VERSION ""

NS_ :

BS_:

BU_: AHLM ASBS CBC DIAGNOST DPDM DTCM ECM EHPS ESC ESL ESM ETM GPF HCP IC IRCM OCM ORC PTS RF_HUB SCCM SGW TBM TCM TPM

BO_ 131 ESP_A1: 8 ESC
 SG_ ABS_BrkEvt : 14|1@1+ (1,0) [0|0] ""  DTCM,ECM,ETM,HCP,ORC,SGW,TBM,TCM
 SG_ BrkIntrvntn_Actv_AS : 6|1@1+ (1,0) [0|0] ""  ETM,IRCM,SGW,TBM,TCM
 SG_ BrkIntrvntn_Actv_ESP : 5|1@1+ (1,0) [0|0] ""  DTCM,ECM,ETM,HCP,ORC,SGW,TBM,TCM
 SG_ BrkIntrvntn_Enbl : 7|1@1+ (1,0) [0|0] ""  ECM,ORC,SGW,TCM
 SG_ BrkPdl_Flt : 4|1@1+ (1,0) [0|0] ""  ECM,ETM,HCP,IRCM,ORC,SGW,TBM
 SG_ BrkPdl_Stat : 2|2@1+ (1,0) [0|0] ""  CBC,DTCM,ECM,ETM,HCP,IRCM,ORC,RF_HUB,SGW,TBM,TCM
 SG_ Brk_Stat : 0|2@1+ (1,0) [0|0] ""  CBC,ECM,ETM,ORC,PTS,SGW,TBM
 SG_ Brk_Thermdl : 25|1@1+ (1,0) [0|0] ""  IRCM,SGW
 SG_ CRC_Brk_Stat : 56|8@1+ (1,0) [0|0] ""  ECM,HCP,IC,IRCM,PTS,RF_HUB,SGW,TCM
 SG_ DTR_CC_Enabled : 23|1@1+ (1,0) [0|0] ""  ECM,HCP,SGW
 SG_ DTR_CC_Engaged : 15|1@1+ (1,0) [0|0] ""  CBC,ECM,HCP,SGW,TCM
 SG_ ESP_Sys_Stat : 10|2@1+ (1,0) [0|0] ""  ECM,ETM,HCP,SGW,TBM,TCM
 SG_ EmgBrk_Actv : 8|1@1+ (1,0) [0|0] ""  ORC,SGW
 SG_ FullBrk_Actv : 9|1@1+ (1,0) [0|0] ""  ORC,SGW
 SG_ GrMax_Rq_ESC : 19|3@1+ (1,0) [0|0] ""  SGW,TCM
 SG_ GrMinMax_Rq_DTR : 22|1@1+ (1,0) [0|0] ""  SGW,TCM
 SG_ GrMin_Rq_ESC : 16|3@1+ (1,0) [0|0] ""  SGW,TCM
 SG_ HillHolderActive : 24|1@1+ (1,0) [0|0] ""  SGW,TCM
 SG_ MC_Brk_Stat : 52|4@1+ (1,0) [0|15] ""  ECM,HCP,IC,IRCM,PTS,RF_HUB,SGW,TCM
 SG_ REF_VEH_SPEED : 33|10@0+ (0.5,0) [0|511] "km/h"  ECM,HCP,ORC,SGW,TCM
 SG_ RollTestMd_Actv : 30|2@1+ (1,0) [0|0] ""  DTCM,ECM,IRCM,SGW
 SG_ SPCR_AS_Off_Rq : 38|2@1+ (1,0) [0|0] ""  ECM,IRCM,SGW
 SG_ SelSpdSts : 12|2@1+ (1,0) [0|0] ""  CBC,DTCM,ECM,IC,SGW,TCM
 SG_ ShftChrDsp_Rq_ESC : 26|4@1+ (1,0) [0|0] ""  ECM,SGW,TCM

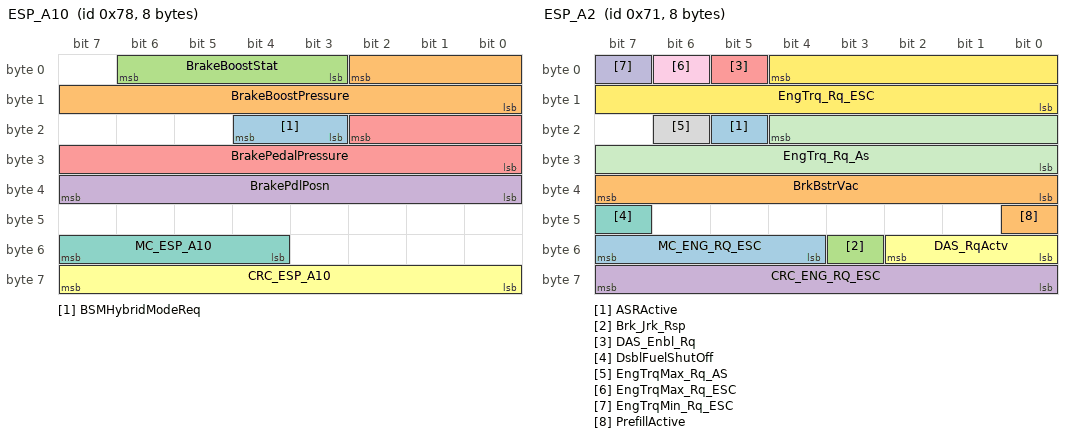
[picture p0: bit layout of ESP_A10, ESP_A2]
BO_ 120 ESP_A10: 8 ESC
 SG_ BSMHybridModeReq : 19|2@1+ (1,0) [0|0] ""  SGW
 SG_ BrakeBoostPressure : 2|11@0+ (0.1,0) [0|200] "bar"  ECM,SGW,TCM
 SG_ BrakeBoostStat : 3|4@1+ (1,0) [0|0] ""  SGW
 SG_ BrakePdlPosn : 32|8@1+ (0.4,0) [0|100] "%"  ECM,ETM,ORC,SGW,TBM,TCM
 SG_ BrakePedalPressure : 18|11@0+ (0.1,0) [0|200] "bar"  ECM,SGW,TCM
 SG_ CRC_ESP_A10 : 56|8@1+ (1,0) [0|0] ""  ECM,SGW,TCM
 SG_ MC_ESP_A10 : 52|4@1+ (1,0) [0|15] ""  ECM,SGW,TCM

BO_ 113 ESP_A2: 8 ESC
 SG_ ASRActive : 21|1@1+ (1,0) [0|0] ""  ETM,ORC,SGW,TBM,TCM
 SG_ BrkBstrVac : 32|8@1+ (0.55,-119.7) [-119.7|20] "kPa"  ECM,ORC,SGW
 SG_ Brk_Jrk_Rsp : 51|1@1+ (1,0) [0|0] ""  IRCM,ORC,SGW
 SG_ CRC_ENG_RQ_ESC : 56|8@1+ (1,0) [0|0] ""  ECM,IRCM,SGW,TCM
 SG_ DAS_Enbl_Rq : 5|1@1+ (1,0) [0|0] ""  ECM,IRCM,SGW
 SG_ DAS_RqActv : 48|3@1+ (1,0) [0|0] ""  IRCM,ORC,SGW
 SG_ DsblFuelShutOff : 47|1@1+ (1,0) [0|0] ""  ECM,SGW
 SG_ EngTrqMax_Rq_AS : 22|1@1+ (1,0) [0|0] ""  ECM,SGW
 SG_ EngTrqMax_Rq_ESC : 6|1@1+ (1,0) [0|0] ""  ECM,SGW,TCM
 SG_ EngTrqMin_Rq_ESC : 7|1@1+ (1,0) [0|0] ""  ECM,SGW,TCM
 SG_ EngTrq_Rq_As : 20|13@0+ (0.25,-500) [-500|1547.5] "Nm"  ECM,IRCM,ORC,SGW
 SG_ EngTrq_Rq_ESC : 4|13@0+ (0.25,-500) [-500|1547.5] "Nm"  DTCM,ECM,ETM,SGW,TBM
 SG_ MC_ENG_RQ_ESC : 52|4@1+ (1,0) [0|15] ""  ECM,IRCM,SGW,TCM
 SG_ PrefillActive : 40|1@1+ (1,0) [0|0] ""  IRCM,SGW

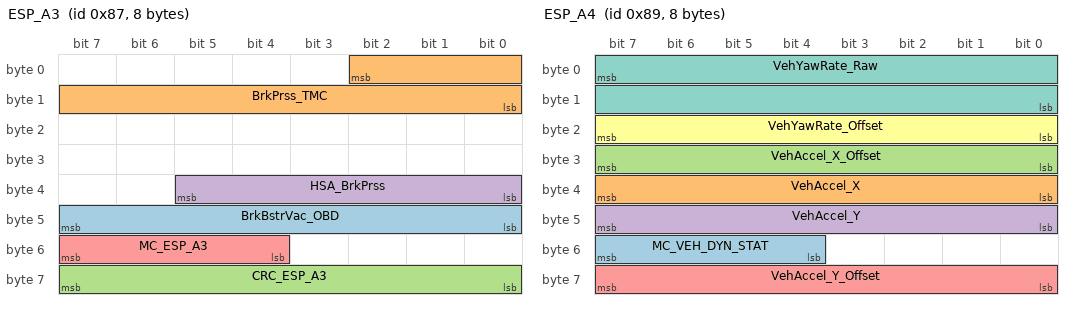
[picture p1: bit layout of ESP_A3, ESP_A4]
BO_ 135 ESP_A3: 8 ESC
 SG_ BrkBstrVac_OBD : 40|8@1+ (0.019607843,0) [0|5] "Volts"  ECM,SGW
 SG_ BrkPrss_TMC : 2|11@0+ (0.1,0) [0|200] "bar"  ECM,ETM,ORC,SGW,TBM,TCM
 SG_ CRC_ESP_A3 : 56|8@1+ (1,0) [0|0] ""  ECM,PTS,SGW,TCM
 SG_ HSA_BrkPrss : 32|6@1+ (1,0) [0|50] "bar"  ECM,ETM,ORC,SGW,TBM
 SG_ MC_ESP_A3 : 52|4@1+ (1,0) [0|15] ""  ECM,PTS,SGW,TCM

BO_ 137 ESP_A4: 8 ESC
 SG_ MC_VEH_DYN_STAT : 52|4@1+ (1,0) [0|15] ""  ECM,ETM,IRCM,PTS,SGW
 SG_ VehAccel_X : 32|8@1+ (0.08,-10.24) [-10.24|10.08] "m/s²"  CBC,DTCM,ECM,ETM,IRCM,SGW,TBM,TCM
 SG_ VehAccel_X_Offset : 24|8@1+ (0.02,-2.56) [-2.56|2.52] "m/s²"  DTCM,ECM,ETM,IRCM,SGW,TBM,TCM
 SG_ VehAccel_Y : 40|8@1+ (0.08,-10.24) [-10.24|10.08] "m/s²"  CBC,DTCM,ECM,ETM,IRCM,SGW,TBM,TCM
 SG_ VehAccel_Y_Offset : 56|8@1+ (0.02,-2.56) [-2.56|2.52] "m/s²"  DTCM,ECM,ETM,IRCM,SGW,TBM,TCM
 SG_ VehYawRate_Offset : 16|8@1+ (0.08,-10.24) [-6.96|6.96] ""  DTCM,ECM,IRCM,ORC,SGW
 SG_ VehYawRate_Raw : 7|16@0+ (0.01,-327.68) [-327.68|327.66] "°/s"  CBC,DTCM,ECM,ETM,IRCM,SGW,TBM

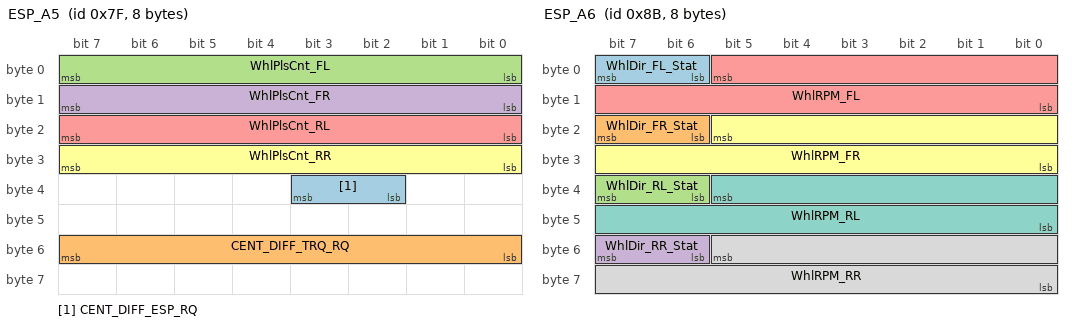
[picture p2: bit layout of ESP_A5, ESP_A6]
BO_ 127 ESP_A5: 8 ESC
 SG_ CENT_DIFF_ESP_RQ : 34|2@1+ (1,0) [0|0] ""  DTCM,SGW
 SG_ CENT_DIFF_TRQ_RQ : 48|8@1+ (10,0) [0|2540] "Nm"  DTCM,SGW
 SG_ WhlPlsCnt_FL : 0|8@1+ (1,0) [0|254] "Impulse"  CBC,IRCM,PTS,SGW,TBM
 SG_ WhlPlsCnt_FR : 8|8@1+ (1,0) [0|254] "Impulse"  CBC,IRCM,PTS,SGW,TBM
 SG_ WhlPlsCnt_RL : 16|8@1+ (1,0) [0|254] "Impulse"  CBC,IRCM,PTS,SGW,TBM
 SG_ WhlPlsCnt_RR : 24|8@1+ (1,0) [0|254] "Impulse"  CBC,IRCM,PTS,SGW,TBM

BO_ 139 ESP_A6: 8 ESC
 SG_ WhlDir_FL_Stat : 6|2@1+ (1,0) [0|0] ""  CBC,HCP,IRCM,PTS,SGW,TBM,TCM
 SG_ WhlDir_FR_Stat : 22|2@1+ (1,0) [0|0] ""  CBC,HCP,IRCM,PTS,SGW,TBM,TCM
 SG_ WhlDir_RL_Stat : 38|2@1+ (1,0) [0|0] ""  CBC,HCP,IRCM,PTS,SGW,TBM,TCM
 SG_ WhlDir_RR_Stat : 54|2@1+ (1,0) [0|0] ""  CBC,HCP,IRCM,PTS,SGW,TBM,TCM
 SG_ WhlRPM_FL : 5|14@0+ (0.5,0) [0|8191] "rpm"  DTCM,ECM,ETM,HCP,IRCM,ORC,PTS,SGW,TBM,TCM
 SG_ WhlRPM_FR : 21|14@0+ (0.5,0) [0|8191] "rpm"  DTCM,ECM,ETM,HCP,IRCM,ORC,PTS,SGW,TBM,TCM
 SG_ WhlRPM_RL : 37|14@0+ (0.5,0) [0|8191] "rpm"  DTCM,ECM,ETM,HCP,IRCM,ORC,PTS,SGW,TBM,TCM
 SG_ WhlRPM_RR : 53|14@0+ (0.5,0) [0|8191] "rpm"  DTCM,ECM,ETM,HCP,IRCM,ORC,PTS,SGW,TBM,TCM

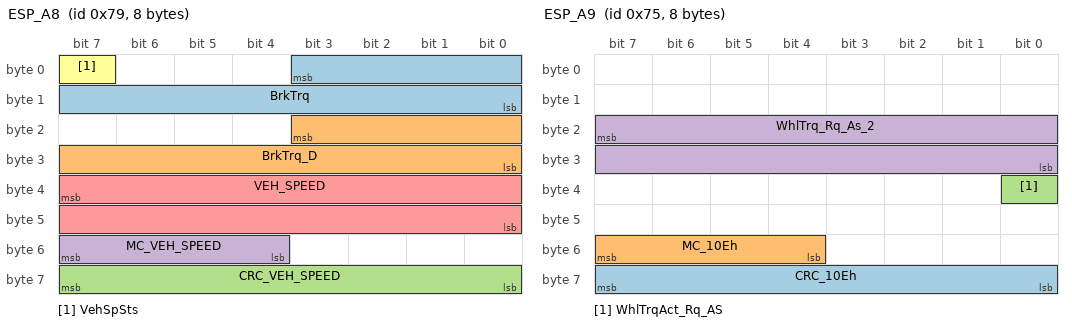
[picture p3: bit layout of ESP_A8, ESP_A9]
BO_ 121 ESP_A8: 8 ESC
 SG_ BrkTrq : 3|12@0+ (3,0) [0|12282] "Nm"  CBC,ECM,IRCM,ORC,SGW,TCM
 SG_ BrkTrq_D : 19|12@0+ (3,0) [0|12282] "Nm"  DTCM,IRCM,SGW,TCM
 SG_ CRC_VEH_SPEED : 56|8@1+ (1,0) [0|0] ""  ECM,ESL,ESM,HCP,IC,IRCM,ORC,PTS,RF_HUB,SGW,TCM
 SG_ MC_VEH_SPEED : 52|4@1+ (1,0) [0|15] ""  ECM,ESL,ESM,HCP,IC,IRCM,ORC,PTS,RF_HUB,SGW,TCM
 SG_ VEH_SPEED : 39|16@0+ (0.0078125,0) [0|511.984375] "km/h"  AHLM,ASBS,CBC,DTCM,ECM,EHPS,ESL,ETM,HCP,IC,IRCM,ORC,PTS,RF_HUB,SGW,TBM,TCM,TPM
 SG_ VehSpSts : 7|1@1+ (1,0) [0|0] ""  HCP,IRCM,SGW

BO_ 117 ESP_A9: 8 ESC
 SG_ CRC_10Eh : 56|8@1+ (1,0) [0|255] ""  ECM,SGW
 SG_ MC_10Eh : 52|4@1+ (1,0) [0|15] ""  ECM,SGW
 SG_ WhlTrqAct_Rq_AS : 32|1@1+ (1,0) [0|0] ""  ECM,SGW
 SG_ WhlTrq_Rq_As_2 : 23|16@0+ (2,-36878) [-36878|94190] "Nm"  ECM,ORC,SGW

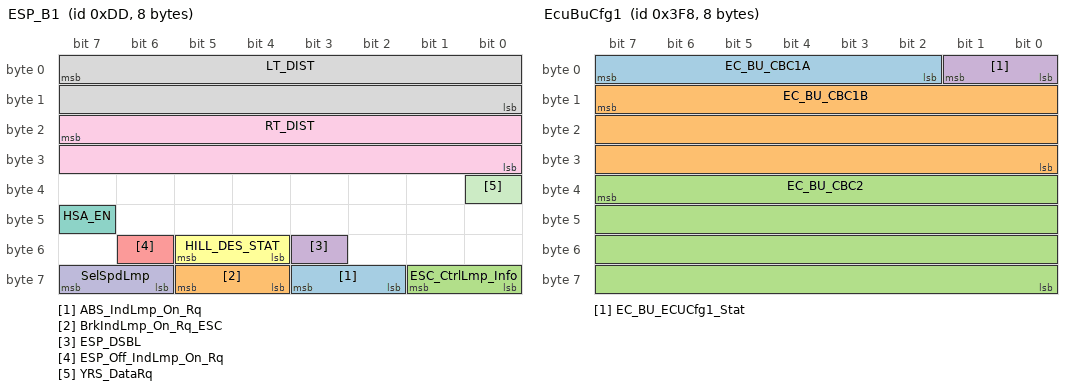
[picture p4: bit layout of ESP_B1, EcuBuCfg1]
BO_ 221 ESP_B1: 8 ESC
 SG_ ABS_IndLmp_On_Rq : 58|2@1+ (1,0) [0|0] ""  ECM,ETM,IC,SGW,TBM
 SG_ BrkIndLmp_On_Rq_ESC : 60|2@1+ (1,0) [0|0] ""  ETM,IC,ORC,SGW,TBM
 SG_ ESC_CtrlLmp_Info : 56|2@1+ (1,0) [0|0] ""  DTCM,ETM,IC,ORC,SGW,TBM
 SG_ ESP_DSBL : 51|1@1+ (1,0) [0|0] ""  CBC,DTCM,ECM,ETM,IC,IRCM,ORC,SGW,TBM
 SG_ ESP_Off_IndLmp_On_Rq : 54|1@1+ (1,0) [0|0] ""  CBC,DTCM,ETM,IC,ORC,SGW,TBM,TCM
 SG_ HILL_DES_STAT : 52|2@1+ (1,0) [0|0] ""  CBC,ECM,IC,ORC,SGW,TCM
 SG_ HSA_EN : 47|1@1+ (1,0) [0|0] ""  CBC,SGW
 SG_ LT_DIST : 7|16@0+ (4,0) [0|262136] "cm"  CBC,ECM,IC,PTS,SGW,TBM
 SG_ RT_DIST : 23|16@0+ (4,0) [0|262136] "cm"  CBC,ECM,IC,PTS,SGW,TBM
 SG_ SelSpdLmp : 62|2@1+ (1,0) [0|0] ""  CBC,ETM,IC,ORC,SGW
 SG_ YRS_DataRq : 32|1@1+ (1,0) [0|0] ""  ORC,SGW

BO_ 327 ESP_B2: 8 ESC
 SG_ ESCSysEmsMlfAtv : 18|1@1+ (1,0) [0|0] ""  HCP,SGW
 SG_ MIL_OnRq_ESC : 2|1@1+ (1,0) [0|0] ""  ECM,ETM,SGW,TBM

BO_ 738 ESP_B4: 8 ESC
 SG_ CODE_CLR_ESC : 15|1@1+ (1,0) [0|0] ""  ECM,SGW
 SG_ REPRGD_PFC_CLR_ESC : 22|1@1+ (1,0) [0|0] ""  ECM,SGW

BO_ 840 ESP_C1: 8 ESC
 SG_ FailSafeError : 7|16@0+ (1,0) [0|65534] ""  IRCM,SGW

BO_ 1016 EcuBuCfg1: 8 RF_HUB
 SG_ EC_BU_CBC1A : 2|6@1+ (1,0) [0|0] ""  CBC,SGW
 SG_ EC_BU_CBC1B : 15|24@0+ (1,0) [0|0] ""  CBC,SGW
 SG_ EC_BU_CBC2 : 39|32@0+ (1,0) [0|0] ""  CBC,SGW
 SG_ EC_BU_ECUCfg1_Stat : 0|2@1+ (1,0) [0|0] ""  CBC,SGW

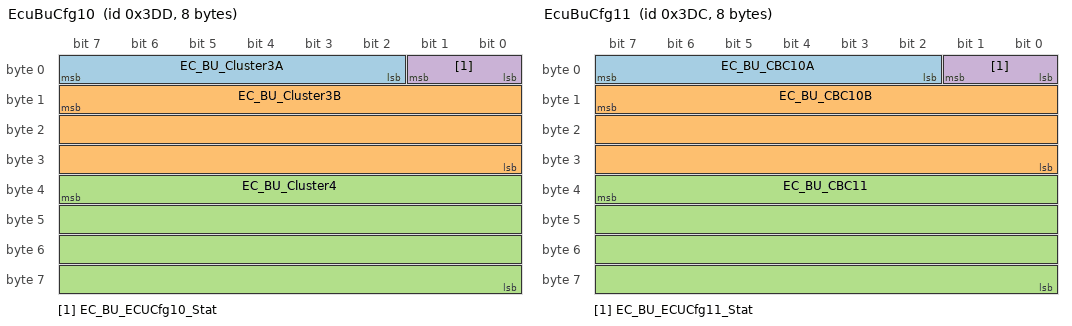
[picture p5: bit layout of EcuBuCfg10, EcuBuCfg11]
BO_ 989 EcuBuCfg10: 8 RF_HUB
 SG_ EC_BU_Cluster3A : 2|6@1+ (1,0) [0|0] ""  CBC,SGW
 SG_ EC_BU_Cluster3B : 15|24@0+ (1,0) [0|0] ""  CBC,SGW
 SG_ EC_BU_Cluster4 : 39|32@0+ (1,0) [0|0] ""  CBC,SGW
 SG_ EC_BU_ECUCfg10_Stat : 0|2@1+ (1,0) [0|0] ""  CBC,SGW

BO_ 988 EcuBuCfg11: 8 RF_HUB
 SG_ EC_BU_CBC10A : 2|6@1+ (1,0) [0|0] ""  CBC,SGW
 SG_ EC_BU_CBC10B : 15|24@0+ (1,0) [0|0] ""  CBC,SGW
 SG_ EC_BU_CBC11 : 39|32@0+ (1,0) [0|0] ""  CBC,SGW
 SG_ EC_BU_ECUCfg11_Stat : 0|2@1+ (1,0) [0|0] ""  CBC,SGW

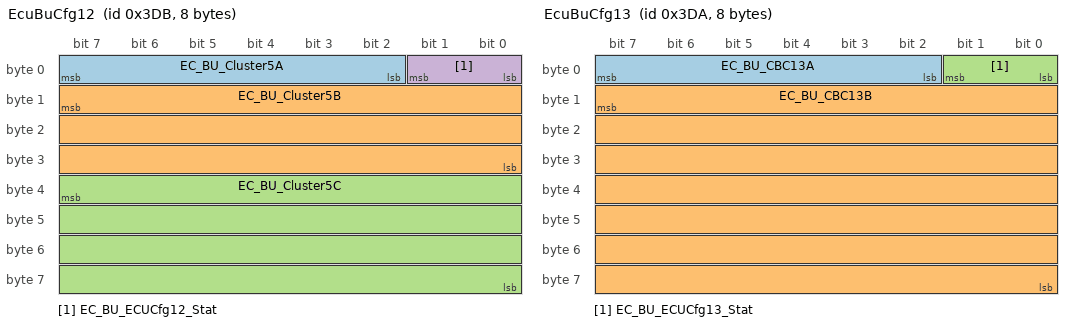
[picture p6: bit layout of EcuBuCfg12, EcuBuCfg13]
BO_ 987 EcuBuCfg12: 8 RF_HUB
 SG_ EC_BU_Cluster5A : 2|6@1+ (1,0) [0|0] ""  CBC,SGW
 SG_ EC_BU_Cluster5B : 15|24@0+ (1,0) [0|0] ""  CBC,SGW
 SG_ EC_BU_Cluster5C : 39|32@0+ (1,0) [0|0] ""  CBC,SGW
 SG_ EC_BU_ECUCfg12_Stat : 0|2@1+ (1,0) [0|0] ""  CBC,SGW

BO_ 986 EcuBuCfg13: 8 RF_HUB
 SG_ EC_BU_CBC13A : 2|6@1+ (1,0) [0|0] ""  CBC,SGW
 SG_ EC_BU_CBC13B : 15|56@0+ (1,0) [0|0] ""  CBC,SGW
 SG_ EC_BU_ECUCfg13_Stat : 0|2@1+ (1,0) [0|0] ""  CBC,SGW

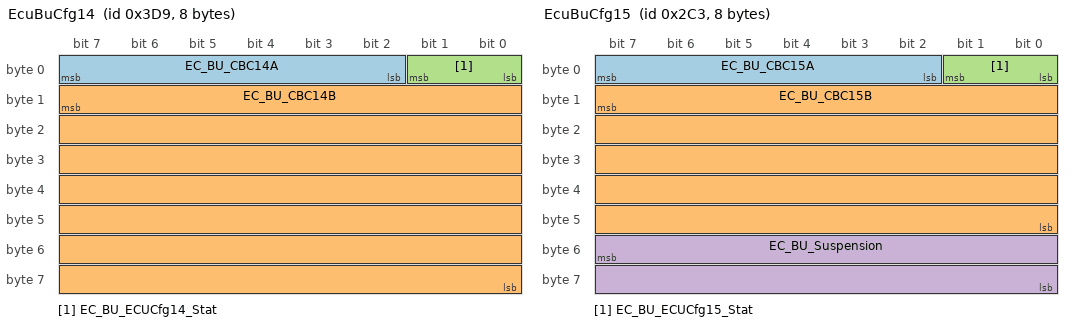
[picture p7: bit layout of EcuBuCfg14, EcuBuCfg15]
BO_ 985 EcuBuCfg14: 8 RF_HUB
 SG_ EC_BU_CBC14A : 2|6@1+ (1,0) [0|0] ""  CBC,SGW
 SG_ EC_BU_CBC14B : 15|56@0+ (1,0) [0|0] ""  CBC,SGW
 SG_ EC_BU_ECUCfg14_Stat : 0|2@1+ (1,0) [0|0] ""  CBC,SGW

BO_ 707 EcuBuCfg15: 8 RF_HUB
 SG_ EC_BU_CBC15A : 2|6@1+ (1,0) [0|0] ""  CBC,SGW
 SG_ EC_BU_CBC15B : 15|40@0+ (1,0) [0|0] ""  CBC,SGW
 SG_ EC_BU_ECUCfg15_Stat : 0|2@1+ (1,0) [0|0] ""  CBC,SGW
 SG_ EC_BU_Suspension : 55|16@0+ (1,0) [0|0] ""  CBC,SGW

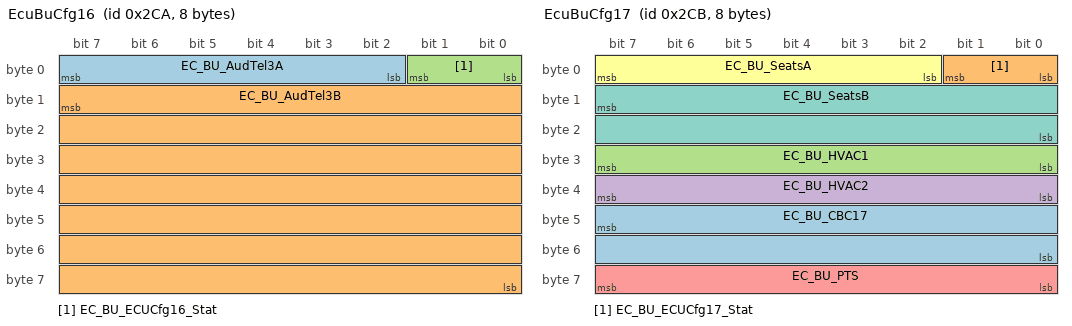
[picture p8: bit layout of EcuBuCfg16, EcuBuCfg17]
BO_ 714 EcuBuCfg16: 8 RF_HUB
 SG_ EC_BU_AudTel3A : 2|6@1+ (1,0) [0|0] ""  CBC,SGW
 SG_ EC_BU_AudTel3B : 15|56@0+ (1,0) [0|0] ""  CBC,SGW
 SG_ EC_BU_ECUCfg16_Stat : 0|2@1+ (1,0) [0|0] ""  CBC,SGW

BO_ 715 EcuBuCfg17: 8 RF_HUB
 SG_ EC_BU_CBC17 : 47|16@0+ (1,0) [0|0] ""  CBC,SGW
 SG_ EC_BU_ECUCfg17_Stat : 0|2@1+ (1,0) [0|0] ""  CBC,SGW
 SG_ EC_BU_HVAC1 : 24|8@1+ (1,0) [0|0] ""  CBC,SGW
 SG_ EC_BU_HVAC2 : 32|8@1+ (1,0) [0|0] ""  CBC,SGW
 SG_ EC_BU_PTS : 56|8@1+ (1,0) [0|0] ""  CBC,SGW
 SG_ EC_BU_SeatsA : 2|6@1+ (1,0) [0|0] ""  CBC,SGW
 SG_ EC_BU_SeatsB : 15|16@0+ (1,0) [0|0] ""  CBC,SGW

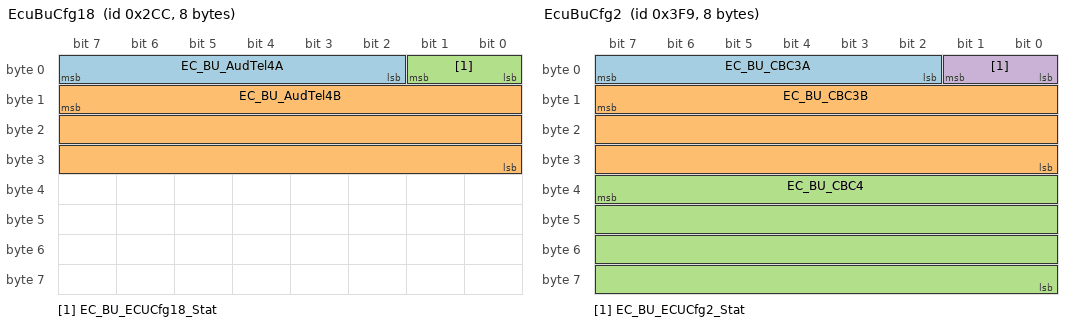
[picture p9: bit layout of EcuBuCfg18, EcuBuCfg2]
BO_ 716 EcuBuCfg18: 8 RF_HUB
 SG_ EC_BU_AudTel4A : 2|6@1+ (1,0) [0|0] ""  CBC,SGW
 SG_ EC_BU_AudTel4B : 15|24@0+ (1,0) [0|0] ""  CBC,SGW
 SG_ EC_BU_ECUCfg18_Stat : 0|2@1+ (1,0) [0|0] ""  CBC,SGW

BO_ 1017 EcuBuCfg2: 8 RF_HUB
 SG_ EC_BU_CBC3A : 2|6@1+ (1,0) [0|0] ""  CBC,SGW
 SG_ EC_BU_CBC3B : 15|24@0+ (1,0) [0|0] ""  CBC,SGW
 SG_ EC_BU_CBC4 : 39|32@0+ (1,0) [0|0] ""  CBC,SGW
 SG_ EC_BU_ECUCfg2_Stat : 0|2@1+ (1,0) [0|0] ""  CBC,SGW

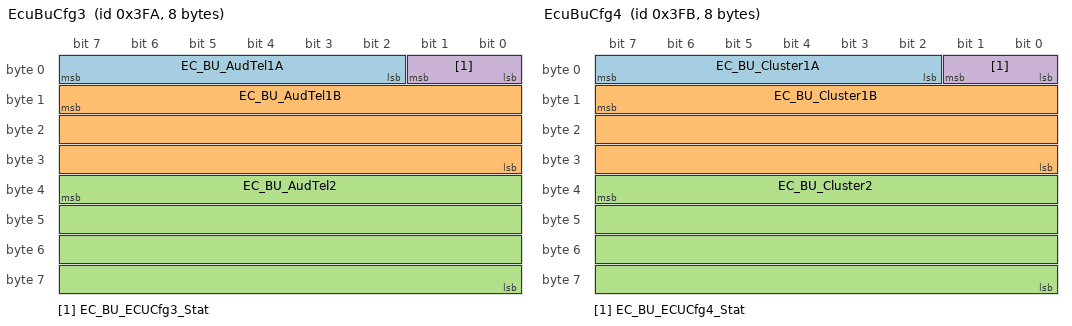
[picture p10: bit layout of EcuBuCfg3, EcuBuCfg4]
BO_ 1018 EcuBuCfg3: 8 RF_HUB
 SG_ EC_BU_AudTel1A : 2|6@1+ (1,0) [0|0] ""  CBC,SGW
 SG_ EC_BU_AudTel1B : 15|24@0+ (1,0) [0|0] ""  CBC,SGW
 SG_ EC_BU_AudTel2 : 39|32@0+ (1,0) [0|0] ""  CBC,SGW
 SG_ EC_BU_ECUCfg3_Stat : 0|2@1+ (1,0) [0|0] ""  CBC,SGW

BO_ 1019 EcuBuCfg4: 8 RF_HUB
 SG_ EC_BU_Cluster1A : 2|6@1+ (1,0) [0|0] ""  CBC,SGW
 SG_ EC_BU_Cluster1B : 15|24@0+ (1,0) [0|0] ""  CBC,SGW
 SG_ EC_BU_Cluster2 : 39|32@0+ (1,0) [0|0] ""  CBC,SGW
 SG_ EC_BU_ECUCfg4_Stat : 0|2@1+ (1,0) [0|0] ""  CBC,SGW

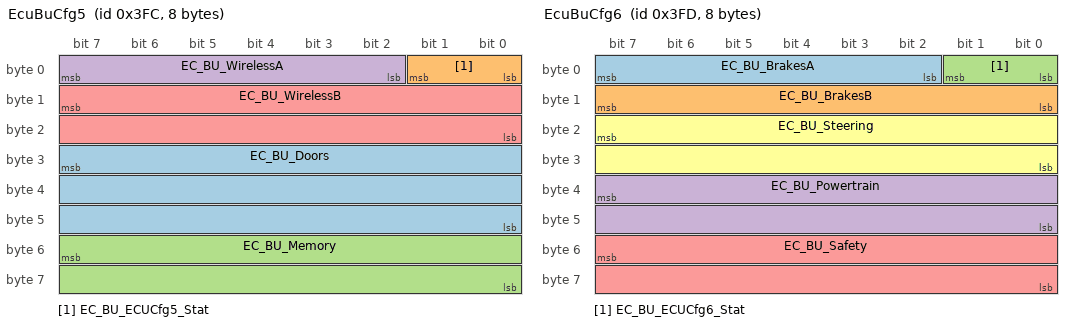
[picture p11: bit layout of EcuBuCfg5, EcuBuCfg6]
BO_ 1020 EcuBuCfg5: 8 RF_HUB
 SG_ EC_BU_Doors : 31|24@0+ (1,0) [0|0] ""  CBC,SGW
 SG_ EC_BU_ECUCfg5_Stat : 0|2@1+ (1,0) [0|0] ""  CBC,SGW
 SG_ EC_BU_Memory : 55|16@0+ (1,0) [0|0] ""  CBC,SGW
 SG_ EC_BU_WirelessA : 2|6@1+ (1,0) [0|0] ""  CBC,SGW
 SG_ EC_BU_WirelessB : 15|16@0+ (1,0) [0|0] ""  CBC,SGW

BO_ 1021 EcuBuCfg6: 8 RF_HUB
 SG_ EC_BU_BrakesA : 2|6@1+ (1,0) [0|0] ""  CBC,SGW
 SG_ EC_BU_BrakesB : 8|8@1+ (1,0) [0|0] ""  CBC,SGW
 SG_ EC_BU_ECUCfg6_Stat : 0|2@1+ (1,0) [0|0] ""  CBC,SGW
 SG_ EC_BU_Powertrain : 39|16@0+ (1,0) [0|0] ""  CBC,SGW
 SG_ EC_BU_Safety : 55|16@0+ (1,0) [0|0] ""  CBC,SGW
 SG_ EC_BU_Steering : 23|16@0+ (1,0) [0|0] ""  CBC,SGW

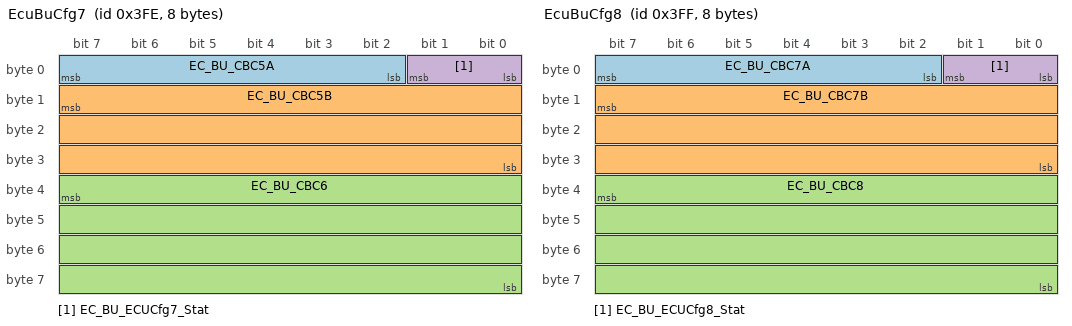
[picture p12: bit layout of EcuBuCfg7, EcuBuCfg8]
BO_ 1022 EcuBuCfg7: 8 RF_HUB
 SG_ EC_BU_CBC5A : 2|6@1+ (1,0) [0|0] ""  CBC,SGW
 SG_ EC_BU_CBC5B : 15|24@0+ (1,0) [0|0] ""  CBC,SGW
 SG_ EC_BU_CBC6 : 39|32@0+ (1,0) [0|0] ""  CBC,SGW
 SG_ EC_BU_ECUCfg7_Stat : 0|2@1+ (1,0) [0|0] ""  CBC,SGW

BO_ 1023 EcuBuCfg8: 8 RF_HUB
 SG_ EC_BU_CBC7A : 2|6@1+ (1,0) [0|0] ""  CBC,SGW
 SG_ EC_BU_CBC7B : 15|24@0+ (1,0) [0|0] ""  CBC,SGW
 SG_ EC_BU_CBC8 : 39|32@0+ (1,0) [0|0] ""  CBC,SGW
 SG_ EC_BU_ECUCfg8_Stat : 0|2@1+ (1,0) [0|0] ""  CBC,SGW

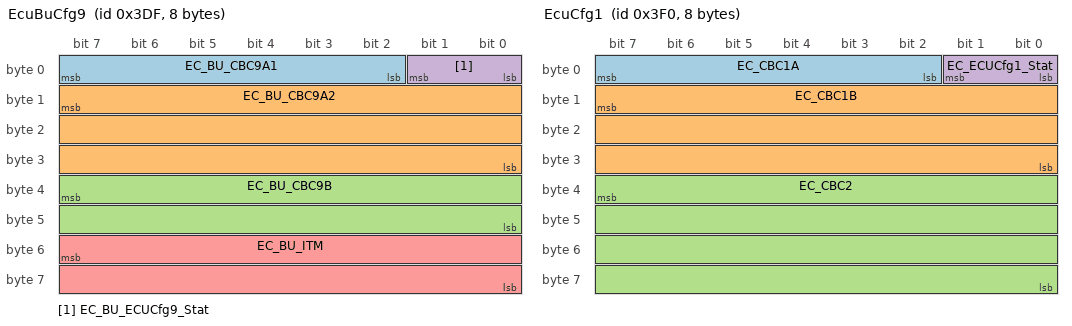
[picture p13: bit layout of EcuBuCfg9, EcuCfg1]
BO_ 991 EcuBuCfg9: 8 RF_HUB
 SG_ EC_BU_CBC9A1 : 2|6@1+ (1,0) [0|0] ""  CBC,SGW
 SG_ EC_BU_CBC9A2 : 15|24@0+ (1,0) [0|0] ""  CBC,SGW
 SG_ EC_BU_CBC9B : 39|16@0+ (1,0) [0|0] ""  CBC,SGW
 SG_ EC_BU_ECUCfg9_Stat : 0|2@1+ (1,0) [0|0] ""  CBC,SGW
 SG_ EC_BU_ITM : 55|16@0+ (1,0) [0|0] ""  CBC,SGW

BO_ 1008 EcuCfg1: 8 CBC
 SG_ EC_CBC1A : 2|6@1+ (1,0) [0|0] ""  RF_HUB,SGW
 SG_ EC_CBC1B : 15|24@0+ (1,0) [0|0] ""  RF_HUB,SGW
 SG_ EC_CBC2 : 39|32@0+ (1,0) [0|0] ""  RF_HUB,SGW
 SG_ EC_ECUCfg1_Stat : 0|2@1+ (1,0) [0|0] ""  RF_HUB,SGW

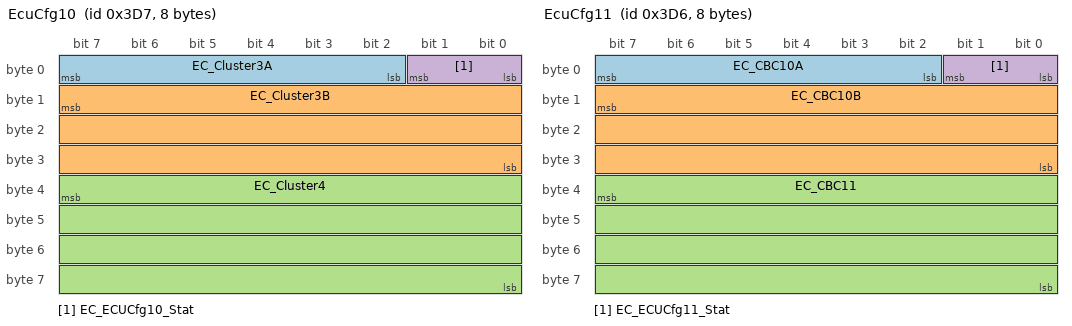
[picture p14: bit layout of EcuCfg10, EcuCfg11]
BO_ 983 EcuCfg10: 8 CBC
 SG_ EC_Cluster3A : 2|6@1+ (1,0) [0|0] ""  RF_HUB,SGW
 SG_ EC_Cluster3B : 15|24@0+ (1,0) [0|0] ""  RF_HUB,SGW
 SG_ EC_Cluster4 : 39|32@0+ (1,0) [0|0] ""  RF_HUB,SGW
 SG_ EC_ECUCfg10_Stat : 0|2@1+ (1,0) [0|0] ""  IC,RF_HUB,SGW

BO_ 982 EcuCfg11: 8 CBC
 SG_ EC_CBC10A : 2|6@1+ (1,0) [0|0] ""  RF_HUB,SGW
 SG_ EC_CBC10B : 15|24@0+ (1,0) [0|0] ""  RF_HUB,SGW
 SG_ EC_CBC11 : 39|32@0+ (1,0) [0|0] ""  RF_HUB,SGW
 SG_ EC_ECUCfg11_Stat : 0|2@1+ (1,0) [0|0] ""  RF_HUB,SGW

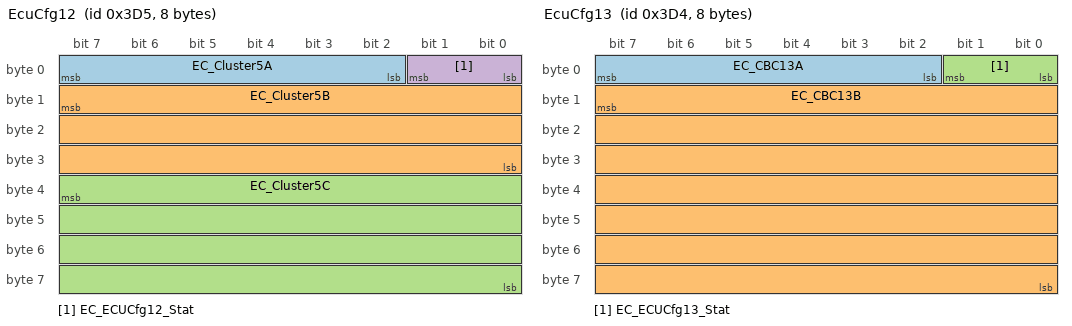
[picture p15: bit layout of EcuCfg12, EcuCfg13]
BO_ 981 EcuCfg12: 8 CBC
 SG_ EC_Cluster5A : 2|6@1+ (1,0) [0|0] ""  RF_HUB,SGW
 SG_ EC_Cluster5B : 15|24@0+ (1,0) [0|0] ""  RF_HUB,SGW
 SG_ EC_Cluster5C : 39|32@0+ (1,0) [0|0] ""  RF_HUB,SGW
 SG_ EC_ECUCfg12_Stat : 0|2@1+ (1,0) [0|0] ""  IC,RF_HUB,SGW

BO_ 980 EcuCfg13: 8 CBC
 SG_ EC_CBC13A : 2|6@1+ (1,0) [0|0] ""  RF_HUB,SGW
 SG_ EC_CBC13B : 15|56@0+ (1,0) [0|0] ""  RF_HUB,SGW
 SG_ EC_ECUCfg13_Stat : 0|2@1+ (1,0) [0|0] ""  RF_HUB,SGW

BO_ 979 EcuCfg14: 8 CBC
 SG_ EC_CBC14A : 2|6@1+ (1,0) [0|0] ""  RF_HUB,SGW
 SG_ EC_CBC14B : 15|56@0+ (1,0) [0|0] ""  RF_HUB,SGW
 SG_ EC_ECUCfg14_Stat : 0|2@1+ (1,0) [0|0] ""  RF_HUB,SGW

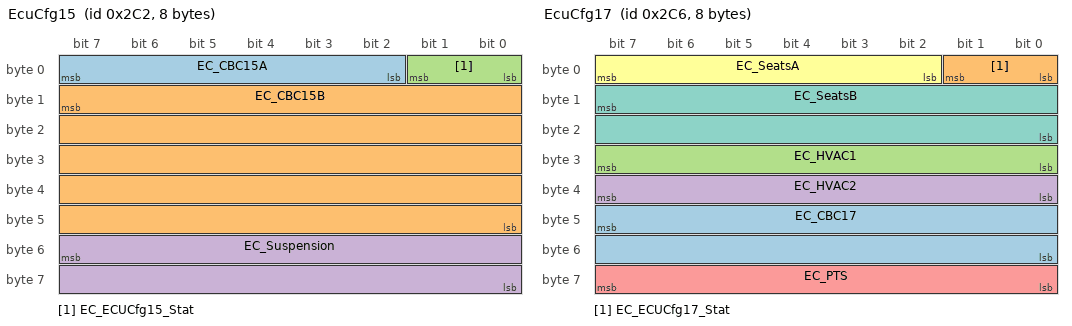
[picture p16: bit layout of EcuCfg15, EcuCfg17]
BO_ 706 EcuCfg15: 8 CBC
 SG_ EC_CBC15A : 2|6@1+ (1,0) [0|0] ""  RF_HUB,SGW
 SG_ EC_CBC15B : 15|40@0+ (1,0) [0|0] ""  RF_HUB,SGW
 SG_ EC_ECUCfg15_Stat : 0|2@1+ (1,0) [0|0] ""  RF_HUB,SGW
 SG_ EC_Suspension : 55|16@0+ (1,0) [0|0] ""  RF_HUB,SGW

BO_ 709 EcuCfg16: 8 CBC
 SG_ EC_AudTel3A : 2|6@1+ (1,0) [0|0] ""  RF_HUB,SGW
 SG_ EC_AudTel3B : 15|56@0+ (1,0) [0|0] ""  RF_HUB,SGW
 SG_ EC_ECUCfg16_Stat : 0|2@1+ (1,0) [0|0] ""  RF_HUB,SGW

BO_ 710 EcuCfg17: 8 CBC
 SG_ EC_CBC17 : 47|16@0+ (1,0) [0|0] ""  RF_HUB,SGW
 SG_ EC_ECUCfg17_Stat : 0|2@1+ (1,0) [0|0] ""  PTS,RF_HUB,SGW
 SG_ EC_HVAC1 : 24|8@1+ (1,0) [0|0] ""  IC,RF_HUB,SGW
 SG_ EC_HVAC2 : 32|8@1+ (1,0) [0|0] ""  RF_HUB,SGW
 SG_ EC_PTS : 56|8@1+ (1,0) [0|0] ""  PTS,RF_HUB,SGW
 SG_ EC_SeatsA : 2|6@1+ (1,0) [0|0] ""  RF_HUB,SGW
 SG_ EC_SeatsB : 15|16@0+ (1,0) [0|0] ""  RF_HUB,SGW

BO_ 711 EcuCfg18: 8 CBC
 SG_ EC_AudTel4A : 2|6@1+ (1,0) [0|0] ""  RF_HUB,SGW
 SG_ EC_AudTel4B : 15|24@0+ (1,0) [0|0] ""  IC,RF_HUB,SGW
 SG_ EC_ECUCfg18_Stat : 0|2@1+ (1,0) [0|0] ""  RF_HUB,SGW

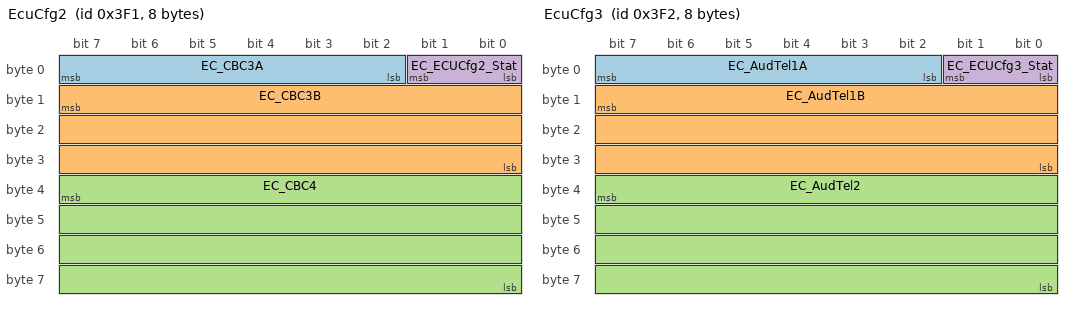
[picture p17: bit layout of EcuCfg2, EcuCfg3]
BO_ 1009 EcuCfg2: 8 CBC
 SG_ EC_CBC3A : 2|6@1+ (1,0) [0|0] ""  RF_HUB,SGW
 SG_ EC_CBC3B : 15|24@0+ (1,0) [0|0] ""  RF_HUB,SGW
 SG_ EC_CBC4 : 39|32@0+ (1,0) [0|0] ""  RF_HUB,SGW
 SG_ EC_ECUCfg2_Stat : 0|2@1+ (1,0) [0|0] ""  RF_HUB,SGW

BO_ 1010 EcuCfg3: 8 CBC
 SG_ EC_AudTel1A : 2|6@1+ (1,0) [0|0] ""  RF_HUB,SGW
 SG_ EC_AudTel1B : 15|24@0+ (1,0) [0|0] ""  RF_HUB,SGW
 SG_ EC_AudTel2 : 39|32@0+ (1,0) [0|0] ""  RF_HUB,SGW
 SG_ EC_ECUCfg3_Stat : 0|2@1+ (1,0) [0|0] ""  RF_HUB,SGW

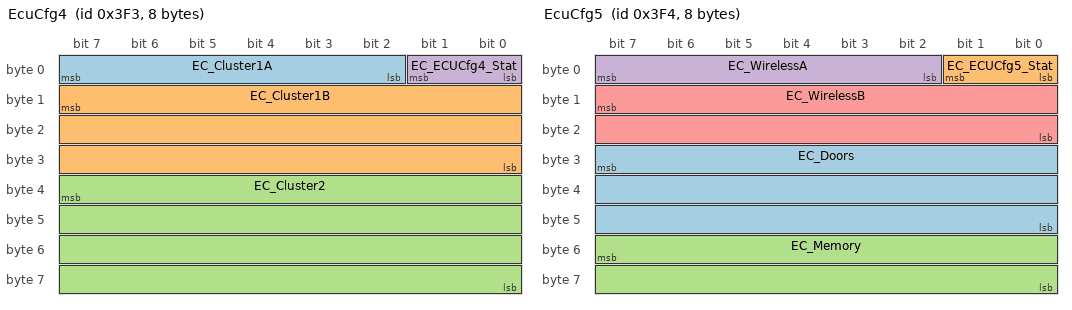
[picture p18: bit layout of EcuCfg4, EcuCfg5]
BO_ 1011 EcuCfg4: 8 CBC
 SG_ EC_Cluster1A : 2|6@1+ (1,0) [0|0] ""  ETM,IC,RF_HUB,SGW
 SG_ EC_Cluster1B : 15|24@0+ (1,0) [0|0] ""  IC,RF_HUB,SGW
 SG_ EC_Cluster2 : 39|32@0+ (1,0) [0|0] ""  IC,RF_HUB,SGW
 SG_ EC_ECUCfg4_Stat : 0|2@1+ (1,0) [0|0] ""  IC,RF_HUB,SGW

BO_ 1012 EcuCfg5: 8 CBC
 SG_ EC_Doors : 31|24@0+ (1,0) [0|0] ""  RF_HUB,SGW
 SG_ EC_ECUCfg5_Stat : 0|2@1+ (1,0) [0|0] ""  OCM,RF_HUB,SGW
 SG_ EC_Memory : 55|16@0+ (1,0) [0|0] ""  OCM,RF_HUB,SGW
 SG_ EC_WirelessA : 2|6@1+ (1,0) [0|0] ""  RF_HUB,SGW
 SG_ EC_WirelessB : 15|16@0+ (1,0) [0|0] ""  RF_HUB,SGW

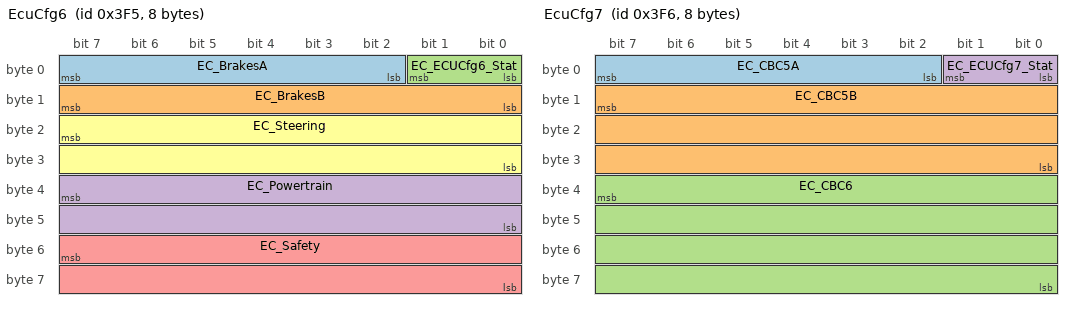
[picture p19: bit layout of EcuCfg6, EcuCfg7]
BO_ 1013 EcuCfg6: 8 CBC
 SG_ EC_BrakesA : 2|6@1+ (1,0) [0|0] ""  ESC,RF_HUB,SGW
 SG_ EC_BrakesB : 8|8@1+ (1,0) [0|0] ""  ESC,RF_HUB,SGW
 SG_ EC_ECUCfg6_Stat : 0|2@1+ (1,0) [0|0] ""  ECM,EHPS,ESC,ORC,RF_HUB,SGW,TCM
 SG_ EC_Powertrain : 39|16@0+ (1,0) [0|0] ""  ECM,RF_HUB,SGW
 SG_ EC_Safety : 55|16@0+ (1,0) [0|0] ""  ORC,RF_HUB,SGW
 SG_ EC_Steering : 23|16@0+ (1,0) [0|0] ""  EHPS,ESC,RF_HUB,SGW

BO_ 1014 EcuCfg7: 8 CBC
 SG_ EC_CBC5A : 2|6@1+ (1,0) [0|0] ""  RF_HUB,SGW
 SG_ EC_CBC5B : 15|24@0+ (1,0) [0|0] ""  RF_HUB,SGW
 SG_ EC_CBC6 : 39|32@0+ (1,0) [0|0] ""  RF_HUB,SGW
 SG_ EC_ECUCfg7_Stat : 0|2@1+ (1,0) [0|0] ""  RF_HUB,SGW

CM_ SG_ 131 ABS_BrkEvt "Any ABS brake event";
CM_ SG_ 131 BrkIntrvntn_Actv_AS "Brake intervention by assistance system active";
CM_ SG_ 131 BrkIntrvntn_Actv_ESP "Brake intervention by ESP active";
CM_ SG_ 131 BrkIntrvntn_Enbl "Brake intervention enabled";
CM_ SG_ 131 BrkPdl_Flt "Brake Pedal Fault is active, 1=Faulted";
CM_ SG_ 131 BrkPdl_Stat "Brake pedal state";
CM_ SG_ 131 Brk_Stat "Brake state";
CM_ SG_ 131 Brk_Thermdl "Brake thermal over target";
CM_ SG_ 131 CRC_Brk_Stat "CRC-checksum byte 1 to 7 according to SAE J1850";
CM_ SG_ 131 DTR_CC_Enabled "ACC is enabled; True = [1]";
CM_ SG_ 131 DTR_CC_Engaged "ACC is engaged; True = [1]";
CM_ SG_ 131 ESP_Sys_Stat "ESP system state";
CM_ SG_ 131 EmgBrk_Actv "Emergency braking";
CM_ SG_ 131 FullBrk_Actv "Maximum (hard) braking (ALS controls all wheels)";
CM_ SG_ 131 GrMax_Rq_ESC "Requested gear, upper limit";
CM_ SG_ 131 GrMinMax_Rq_DTR "Gear limit request from DTR";
CM_ SG_ 131 GrMin_Rq_ESC "Requested gear, lower limit";
CM_ SG_ 131 HillHolderActive "HillHolderActive";
CM_ SG_ 131 MC_Brk_Stat "Message counter";
CM_ SG_ 131 REF_VEH_SPEED "Reference vehicle actual speed";
CM_ SG_ 131 RollTestMd_Actv "Roller test bench mode active";
CM_ SG_ 131 SPCR_AS_Off_Rq "Assistance system off request";
CM_ SG_ 131 SelSpdSts "Select speed status";
CM_ SG_ 131 ShftChrDsp_Rq_ESC "Shift characteristic displacement request";
CM_ SG_ 120 BSMHybridModeReq "Hybrid Drive Mode Request";
CM_ SG_ 120 BrakeBoostPressure "Pressure Information from Brake Booster Pedal Pressure Sensor";
CM_ SG_ 120 BrakeBoostStat "Brake eBoost Status";
CM_ SG_ 120 BrakePdlPosn "Brake pedal travel sensor 0-100% (0 = upstop)";
CM_ SG_ 120 BrakePedalPressure "Pressure Information from Brake Pedal Simulator Pressure Sensor";
CM_ SG_ 120 CRC_ESP_A10 "CRC-checksum byte 1 to 7 according to SAE J1850";
CM_ SG_ 120 MC_ESP_A10 "Message counter";
CM_ SG_ 113 ASRActive "Traction control is active";
CM_ SG_ 113 BrkBstrVac "Brake Booster Vacuum Level";
CM_ SG_ 113 Brk_Jrk_Rsp "Brake jerk response; True = [1]";
CM_ SG_ 113 CRC_ENG_RQ_ESC "CRC-checksum byte 1 to 7 according to SAE J1850";
CM_ SG_ 113 DAS_Enbl_Rq "Enable DAS request; True = [1]";
CM_ SG_ 113 DAS_RqActv "DAS request active";
CM_ SG_ 113 DsblFuelShutOff "Disable fuel shutoff; True = [1]";
CM_ SG_ 113 EngTrqMax_Rq_AS "Engine torque request maximum; True = [1]";
CM_ SG_ 113 EngTrqMax_Rq_ESC "Engine torque request maximum";
CM_ SG_ 113 EngTrqMin_Rq_ESC "Engine torque request minimum";
CM_ SG_ 113 EngTrq_Rq_As "Engine torque request";
CM_ SG_ 113 EngTrq_Rq_ESC "Engine torque request";
CM_ SG_ 113 MC_ENG_RQ_ESC "Message counter";
CM_ SG_ 113 PrefillActive "Brake prefill is active - True = [1]";
CM_ SG_ 135 BrkBstrVac_OBD "Brake booster vacuum level, raw";
CM_ SG_ 135 BrkPrss_TMC "Master cylinder pressure";
CM_ SG_ 135 CRC_ESP_A3 "CRC-checksum byte 1 to 7 according to SAE J1850";
CM_ SG_ 135 HSA_BrkPrss "Hill start assist brake pressure";
CM_ SG_ 135 MC_ESP_A3 "Message counter";
CM_ SG_ 137 MC_VEH_DYN_STAT "Message counter";
CM_ SG_ 137 VehAccel_X "Vehicle longitudinal acceleration (+ means forward)";
CM_ SG_ 137 VehAccel_X_Offset "Offset of vehicle longitudinal acceleration (+ means forward)";
CM_ SG_ 137 VehAccel_Y "Vehicle lateral acceleration (+ means left, specific to center of gravity, offset-corrected )";
CM_ SG_ 137 VehAccel_Y_Offset "Offset of vehicle lateral acceleration (+ means left)";
CM_ SG_ 137 VehYawRate_Offset "Offset of vehicle yaw rate unfiltered/unadjusted (+ means left)";
CM_ SG_ 137 VehYawRate_Raw "Vehicle yaw rate unfiltered/unadjusted (+ means left)";
CM_ SG_ 127 CENT_DIFF_ESP_RQ "ESP Requested Center  Differential State";
CM_ SG_ 127 CENT_DIFF_TRQ_RQ "Desired Torque for Center Diff";
CM_ SG_ 127 WhlPlsCnt_FL "Wheel pulse counter front left (96 per rotation)";
CM_ SG_ 127 WhlPlsCnt_FR "Wheel pulse counter front right (96 per rotation)";
CM_ SG_ 127 WhlPlsCnt_RL "Wheel pulse counter rear left (96 per rotation)";
CM_ SG_ 127 WhlPlsCnt_RR "Wheel pulse counter rear right (96 per rotation)";
CM_ SG_ 139 WhlDir_FL_Stat "Direction of rotation of front left wheel";
CM_ SG_ 139 WhlDir_FR_Stat "Direction of rotation of front right wheel";
CM_ SG_ 139 WhlDir_RL_Stat "Direction of rotation of rear left wheel";
CM_ SG_ 139 WhlDir_RR_Stat "Direction of rotation of rear right wheel";
CM_ SG_ 139 WhlRPM_FL "Wheel rpm front left";
CM_ SG_ 139 WhlRPM_FR "Wheel rpm front right";
CM_ SG_ 139 WhlRPM_RL "Wheel rpm rear left";
CM_ SG_ 139 WhlRPM_RR "Wheel rpm rear right";
CM_ SG_ 121 BrkTrq "Actual brake torque";
CM_ SG_ 121 BrkTrq_D "Brake torque requested by driver";
CM_ SG_ 121 CRC_VEH_SPEED "CRC-checksum byte 1 to 7 according to SAE J1850";
CM_ SG_ 121 MC_VEH_SPEED "Message counter";
CM_ SG_ 121 VEH_SPEED "Vehicle speed";
CM_ SG_ 121 VehSpSts "Vehicle is stopped status signal";
CM_ SG_ 117 CRC_10Eh "CRC-checksum byte 1 to 7 according to SAE J1850";
CM_ SG_ 117 MC_10Eh "Message counter";
CM_ SG_ 117 WhlTrqAct_Rq_AS "Wheel torque request active; True = [1]";
CM_ SG_ 117 WhlTrq_Rq_As_2 "ACC torque request in wheel Domain.";
CM_ SG_ 221 ABS_IndLmp_On_Rq "ABS indication lamp on request";
CM_ SG_ 221 BrkIndLmp_On_Rq_ESC "Brake indication lamp (red) on request";
CM_ SG_ 221 ESC_CtrlLmp_Info "ESC control lamp information";
CM_ SG_ 221 ESP_DSBL "ESP feature is completely disabled = [1]";
CM_ SG_ 221 ESP_Off_IndLmp_On_Rq "ESP-OFF indication lamp on request";
CM_ SG_ 221 HILL_DES_STAT "Hill descent feature status";
CM_ SG_ 221 HSA_EN "Hill Start Assist enabled (1=enabled)";
CM_ SG_ 221 LT_DIST "Distance Traveled by Left Wheel";
CM_ SG_ 221 RT_DIST "Distance Traveled by Right Wheel";
CM_ SG_ 221 SelSpdLmp "Select speed lamp status";
CM_ SG_ 221 YRS_DataRq "Request from ESC for YRS information";
CM_ SG_ 327 ESCSysEmsMlfAtv "ESC emissions related malfunction active";
CM_ SG_ 327 MIL_OnRq_ESC "MIL on request from the ESC";
CM_ SG_ 738 CODE_CLR_ESC "Clear emission related faults; 0= not clear, 1= Clear";
CM_ SG_ 738 REPRGD_PFC_CLR_ESC "Set readiness to 'incomplete'; 0 = Do nothing; 1= Set incomplete";
CM_ SG_ 840 FailSafeError "Fail safe error";
CM_ SG_ 1016 EC_BU_CBC1A "Backup for CBC ecu configuration 1A";
CM_ SG_ 1016 EC_BU_CBC1B "Backup for CBC ecu configuration 1B";
CM_ SG_ 1016 EC_BU_CBC2 "Backup for CBC ecu configuration 2";
CM_ SG_ 1016 EC_BU_ECUCfg1_Stat "Backup for ECU Configuration messages status 1";
CM_ SG_ 989 EC_BU_Cluster3A "Backup for Instrument cluster ecu configuration 3A";
CM_ SG_ 989 EC_BU_Cluster3B "Backup for Instrument cluster ecu configuration 3B";
CM_ SG_ 989 EC_BU_Cluster4 "Backup for Instrument cluster ecu configuration 4";
CM_ SG_ 989 EC_BU_ECUCfg10_Stat "Backup for ECU Configuration messages status 10";
CM_ SG_ 988 EC_BU_CBC10A "Backup for CBC ecu configuration 10A";
CM_ SG_ 988 EC_BU_CBC10B "Backup for CBC ecu configuration 10B";
CM_ SG_ 988 EC_BU_CBC11 "Backup for CBC ecu configuration 11";
CM_ SG_ 988 EC_BU_ECUCfg11_Stat "Backup for ECU Configuration messages status 11";
CM_ SG_ 987 EC_BU_Cluster5A "Backup for Instrument cluster ecu configuration 5A";
CM_ SG_ 987 EC_BU_Cluster5B "Backup for Instrument cluster ecu configuration 5B";
CM_ SG_ 987 EC_BU_Cluster5C "Backup for Instrument cluster ecu configuration 5C";
CM_ SG_ 987 EC_BU_ECUCfg12_Stat "Backup for ECU Configuration messages status 12";
CM_ SG_ 986 EC_BU_CBC13A "Backup for CBC ecu configuration 13A";
CM_ SG_ 986 EC_BU_CBC13B "Backup for CBC ecu configuration 13B";
CM_ SG_ 986 EC_BU_ECUCfg13_Stat "Backup for ECU Configuration messages status 13";
CM_ SG_ 985 EC_BU_CBC14A "Backup for CBC ecu configuration 14A";
CM_ SG_ 985 EC_BU_CBC14B "Backup for CBC ecu configuration 14B";
CM_ SG_ 985 EC_BU_ECUCfg14_Stat "Backup for ECU Configuration messages status 14";
CM_ SG_ 707 EC_BU_CBC15A "Backup for CBC ecu configuration 15A";
CM_ SG_ 707 EC_BU_CBC15B "Backup for CBC ecu configuration 15B";
CM_ SG_ 707 EC_BU_ECUCfg15_Stat "Backup for ECU Configuration messages status 15";
CM_ SG_ 707 EC_BU_Suspension "Backup for Suspension ecu configuration";
CM_ SG_ 714 EC_BU_AudTel3A "Backup for audio and telematics ecu configuration 3A";
CM_ SG_ 714 EC_BU_AudTel3B "Backup for audio and telematics ecu configuration 3B";
CM_ SG_ 714 EC_BU_ECUCfg16_Stat "Backup for ECU Configuration messages status 16";
CM_ SG_ 715 EC_BU_CBC17 "CBC ECU Config 17 Backup";
CM_ SG_ 715 EC_BU_ECUCfg17_Stat "Backup for ECU Configuration messages status 17";
CM_ SG_ 715 EC_BU_HVAC1 "Backup for HVAC ECU Configurations - 1";
CM_ SG_ 715 EC_BU_HVAC2 "Backup for HVAC ECU Configurations - 2";
CM_ SG_ 715 EC_BU_PTS "Backup for park assist ecu configuration";
CM_ SG_ 715 EC_BU_SeatsA "Backup for heated seats ecu configuration";
CM_ SG_ 715 EC_BU_SeatsB "Backup for heated seats ecu configuration";
CM_ SG_ 716 EC_BU_AudTel4A "Backup for audio and telematics ecu configuration 4A";
CM_ SG_ 716 EC_BU_AudTel4B "Backup for audio and telematics ecu configuration 4B";
CM_ SG_ 716 EC_BU_ECUCfg18_Stat "Backup for ECU Configuration messages status 18";
CM_ SG_ 1017 EC_BU_CBC3A "Backup for CBC ecu configuration 3A";
CM_ SG_ 1017 EC_BU_CBC3B "Backup for CBC ecu configuration 3B";
CM_ SG_ 1017 EC_BU_CBC4 "Backup for CBC ecu configuration 4";
CM_ SG_ 1017 EC_BU_ECUCfg2_Stat "Backup for ECU Configuration messages status 2";
CM_ SG_ 1018 EC_BU_AudTel1A "Backup for Audio and telematics ecu configuration 1A";
CM_ SG_ 1018 EC_BU_AudTel1B "Backup for Audio and telematics ecu configuration 1B";
CM_ SG_ 1018 EC_BU_AudTel2 "Backup for Audio and telematics ecu configuration 2";
CM_ SG_ 1018 EC_BU_ECUCfg3_Stat "Backup for ECU Configuration messages status 3";
CM_ SG_ 1019 EC_BU_Cluster1A "Backup for Instrument cluster ecu configuration 1A";
CM_ SG_ 1019 EC_BU_Cluster1B "Backup for Instrument cluster ecu configuration 1B";
CM_ SG_ 1019 EC_BU_Cluster2 "Backup for Instrument cluster ecu configuration 2";
CM_ SG_ 1019 EC_BU_ECUCfg4_Stat "Backup for ECU Configuration messages status 4";
CM_ SG_ 1020 EC_BU_Doors "Backup for Doors ecu configuration";
CM_ SG_ 1020 EC_BU_ECUCfg5_Stat "Backup for ECU Configuration messages status 5";
CM_ SG_ 1020 EC_BU_Memory "Backup for Memory ecu configuration";
CM_ SG_ 1020 EC_BU_WirelessA "Backup for Wireless ecu configurationA";
CM_ SG_ 1020 EC_BU_WirelessB "Backup for Wireless ecu configurationB";
CM_ SG_ 1021 EC_BU_BrakesA "Backup for Brake system ecu configurationA";
CM_ SG_ 1021 EC_BU_BrakesB "Backup for Brake system ecu configurationB";
CM_ SG_ 1021 EC_BU_ECUCfg6_Stat "Backup for ECU Configuration messages status 6";
CM_ SG_ 1021 EC_BU_Powertrain "Backup for Powertrain ecu configuration";
CM_ SG_ 1021 EC_BU_Safety "Backup for Safety ecu configuration";
CM_ SG_ 1021 EC_BU_Steering "Backup for steering ecu configuration";
CM_ SG_ 1022 EC_BU_CBC5A "Backup for CBC ecu configuration 5A";
CM_ SG_ 1022 EC_BU_CBC5B "Backup for CBC ecu configuration 5B";
CM_ SG_ 1022 EC_BU_CBC6 "Backup for CBC ecu configuration 6";
CM_ SG_ 1022 EC_BU_ECUCfg7_Stat "Backup for ECU Configuration messages status 7";
CM_ SG_ 1023 EC_BU_CBC7A "Backup for CBC ecu configuration 7A";
CM_ SG_ 1023 EC_BU_CBC7B "Backup for CBC ecu configuration 7B";
CM_ SG_ 1023 EC_BU_CBC8 "Backup for CBC ecu configuration 8";
CM_ SG_ 1023 EC_BU_ECUCfg8_Stat "Backup for ECU Configuration messages status 8";
CM_ SG_ 991 EC_BU_CBC9A1 "Backup for CBC configuration 9A1";
CM_ SG_ 991 EC_BU_CBC9A2 "Backup for CBC configuration 9A2";
CM_ SG_ 991 EC_BU_CBC9B "Backup for CBC configuration 9B";
CM_ SG_ 991 EC_BU_ECUCfg9_Stat "Backup for ECU Configuration messages status 9";
CM_ SG_ 991 EC_BU_ITM "Backup for ITM ecu configuration";
CM_ SG_ 1008 EC_CBC1A "CBC ecu configuration 1A";
CM_ SG_ 1008 EC_CBC1B "CBC ecu configuration 1B";
CM_ SG_ 1008 EC_CBC2 "CBC ecu configuration 2";
CM_ SG_ 1008 EC_ECUCfg1_Stat "ECU Configuration messages status 1";
CM_ SG_ 983 EC_Cluster3A "Instrument cluster ecu configuration 3A";
CM_ SG_ 983 EC_Cluster3B "Instrument cluster ecu configuration 3B";
CM_ SG_ 983 EC_Cluster4 "Instrument cluster ecu configuration 4";
CM_ SG_ 983 EC_ECUCfg10_Stat "ECU Configuration messages status 10";
CM_ SG_ 982 EC_CBC10A "CBC ecu configuration 10A";
CM_ SG_ 982 EC_CBC10B "CBC ecu configuration 10B";
CM_ SG_ 982 EC_CBC11 "CBC ecu configuration 11";
CM_ SG_ 982 EC_ECUCfg11_Stat "ECU Configuration messages status 11";
CM_ SG_ 981 EC_Cluster5A "Instrument cluster ecu configuration 5A";
CM_ SG_ 981 EC_Cluster5B "Instrument cluster ecu configuration 5B";
CM_ SG_ 981 EC_Cluster5C "Instrument cluster ecu configuration 5C";
CM_ SG_ 981 EC_ECUCfg12_Stat "ECU Configuration messages status 12";
CM_ SG_ 980 EC_CBC13A "CBC ecu configuration 13A";
CM_ SG_ 980 EC_CBC13B "CBC ecu configuration 13B";
CM_ SG_ 980 EC_ECUCfg13_Stat "ECU Configuration messages status 13";
CM_ SG_ 979 EC_CBC14A "CBC ecu configuration 14A";
CM_ SG_ 979 EC_CBC14B "CBC ecu configuration 14B";
CM_ SG_ 979 EC_ECUCfg14_Stat "ECU Configuration messages status 14";
CM_ SG_ 706 EC_CBC15A "CBC ecu configuration 15A";
CM_ SG_ 706 EC_CBC15B "CBC ecu configuration 15B";
CM_ SG_ 706 EC_ECUCfg15_Stat "ECU Configuration messages status 15";
CM_ SG_ 706 EC_Suspension "Suspension ecu configuration";
CM_ SG_ 709 EC_AudTel3A "Audio and telematics ecu configuration 3A";
CM_ SG_ 709 EC_AudTel3B "Audio and telematics ecu configuration 3B";
CM_ SG_ 709 EC_ECUCfg16_Stat "ECU Configuration messages status 16";
CM_ SG_ 710 EC_CBC17 "CBC ECU Config 17";
CM_ SG_ 710 EC_ECUCfg17_Stat "ECU Configuration messages status 17";
CM_ SG_ 710 EC_HVAC1 "HVAC ECU Configurations - 1";
CM_ SG_ 710 EC_HVAC2 "HVAC ECU Configurations - 2";
CM_ SG_ 710 EC_PTS "Park assist ecu configuration";
CM_ SG_ 710 EC_SeatsA "Heated seats ecu configuration - A";
CM_ SG_ 710 EC_SeatsB "Heated seats ecu configuration - B";
CM_ SG_ 711 EC_AudTel4A "Audio and telematics ecu configuration 4A";
CM_ SG_ 711 EC_AudTel4B "Audio and telematics ecu configuration 4B";
CM_ SG_ 711 EC_ECUCfg18_Stat "ECU Configuration messages status 18";
CM_ SG_ 1009 EC_CBC3A "CBC ecu configuration 3A";
CM_ SG_ 1009 EC_CBC3B "CBC ecu configuration 3B";
CM_ SG_ 1009 EC_CBC4 "CBC ecu configuration 4";
CM_ SG_ 1009 EC_ECUCfg2_Stat "ECU Configuration messages status 2";
CM_ SG_ 1010 EC_AudTel1A "Audio and telematics ecu configuration 1A";
CM_ SG_ 1010 EC_AudTel1B "Audio and telematics ecu configuration 1B";
CM_ SG_ 1010 EC_AudTel2 "Audio and telematics ecu configuration 2";
CM_ SG_ 1010 EC_ECUCfg3_Stat "ECU Configuration messages status 3";
CM_ SG_ 1011 EC_Cluster1A "Instrument cluster ecu configuration 1A";
CM_ SG_ 1011 EC_Cluster1B "Instrument cluster ecu configuration 1B";
CM_ SG_ 1011 EC_Cluster2 "Instrument cluster ecu configuration 2";
CM_ SG_ 1011 EC_ECUCfg4_Stat "ECU Configuration messages status 4";
CM_ SG_ 1012 EC_Doors "Doors ecu configuration";
CM_ SG_ 1012 EC_ECUCfg5_Stat "ECU Configuration messages status 5";
CM_ SG_ 1012 EC_Memory "Memory ecu configuration";
CM_ SG_ 1012 EC_WirelessA "Wireless ecu configurationA";
CM_ SG_ 1012 EC_WirelessB "Wireless ecu configurationB";
CM_ SG_ 1013 EC_BrakesA "Brake system ecu configurationA";
CM_ SG_ 1013 EC_BrakesB "Brake system ecu configurationB";
CM_ SG_ 1013 EC_ECUCfg6_Stat "ECU Configuration messages status 6";
CM_ SG_ 1013 EC_Powertrain "Powertrain ecu configuration";
CM_ SG_ 1013 EC_Safety "Safety ecu configuration";
CM_ SG_ 1013 EC_Steering "Steering ecu configuration";
CM_ SG_ 1014 EC_CBC5A "CBC ecu configuration 5A";
CM_ SG_ 1014 EC_CBC5B "CBC ecu configuration 5B";
CM_ SG_ 1014 EC_CBC6 "CBC ecu configuration 6";
CM_ SG_ 1014 EC_ECUCfg7_Stat "ECU Configuration messages status 7";
BA_DEF_ BO_  "App-Botschaft" ENUM  "nein","ja";
BA_DEF_ BO_  "CanMsgMinLen" INT 0 8;
BA_DEF_ BO_  "DiagRequest" ENUM  "nein","ja";
BA_DEF_ BO_  "DiagResponse" ENUM  "nein","ja";
BA_DEF_ BO_  "DiagState" ENUM  "nein","ja";
BA_DEF_ BO_  "GenMsgCycleTime" INT 0 65535;
BA_DEF_ BO_  "GenMsgCycleTimeActive" INT 0 65535;
BA_DEF_ BO_  "GenMsgDelayTime" INT 0 65535;
BA_DEF_ BO_  "GenMsgNrOfRepetitions" INT 0 65535;
BA_DEF_ BO_  "GenMsgSendType" ENUM  "cyclicX","spontanX","cyclicIfActiveX","spontanWithDelay","cyclicAndSpontanX","cyclicAndSpontanWithDelay","spontanWithRepitition","cyclicIfActiveAndSpontanWD","cyclicIfActiveFast","cyclicWithRepeatOnDemand","none";
BA_DEF_ BO_  "GenMsgStartDelayTime" INT 0 65535;
BA_DEF_ BO_  "GenMsgStartValue" STRING ;
BA_DEF_ BO_  "NWM-Botschaft" ENUM  "nein","ja";
BA_DEF_ BO_  "TpTxIndex" INT 0 99;
BA_DEF_ SG_  "FlexKomComment" STRING ;
BA_DEF_ SG_  "FlexKomIsMotorola" ENUM  "nein","ja";
BA_DEF_ SG_  "FlexKomSID" INT 0 2147483647;
BA_DEF_ SG_  "FlexKomSigLaenge" INT 0 64;
BA_DEF_ SG_  "FlexKomSigName" STRING ;
BA_DEF_ SG_  "FlexKomSigStartPos" INT 0 63;
BA_DEF_ SG_  "FlexKomSigStartValue" STRING ;
BA_DEF_ SG_  "GenSigCycleTime" INT 0 65535;
BA_DEF_ SG_  "GenSigCycleTimeActive" INT 0 65535;
BA_DEF_ SG_  "GenSigSendType" ENUM  "cyclicX","spontanX","cyclicIfActiveX","spontanWithDelay","cyclicAndSpontanX","cyclicAndSpontanWithDelay","spontanWithRepitition","cyclicIfActiveAndSpontanWD","cyclicIfActiveFast","cyclicWithRepeatOnDemand","none";
BA_DEF_ SG_  "GenSigSNA" STRING ;
BA_DEF_ SG_  "GenSigStartValue" HEX 0 2147483648;
BA_DEF_ SG_  "GenSigTimeout_AHLM" INT 0 65535;
BA_DEF_ SG_  "GenSigTimeout_ASBS" INT 0 65535;
BA_DEF_ SG_  "GenSigTimeout_CBC" INT 0 65535;
BA_DEF_ SG_  "GenSigTimeout_DPDM" INT 0 65535;
BA_DEF_ SG_  "GenSigTimeout_DTCM" INT 0 65535;
BA_DEF_ SG_  "GenSigTimeout_EHPS" INT 0 65535;
BA_DEF_ SG_  "GenSigTimeout_ESC" INT 0 65535;
BA_DEF_ SG_  "GenSigTimeout_ESL" INT 0 65535;
BA_DEF_ SG_  "GenSigTimeout_ESM" INT 0 65535;
BA_DEF_ SG_  "GenSigTimeout_ETM" INT 0 65535;
BA_DEF_ SG_  "GenSigTimeout_IC" INT 0 65535;
BA_DEF_ SG_  "GenSigTimeout_OCM" INT 0 65535;
BA_DEF_ SG_  "GenSigTimeout_ORC" INT 0 65535;
BA_DEF_ SG_  "GenSigTimeout_PTS" INT 0 65535;
BA_DEF_ SG_  "GenSigTimeout_RF_HUB" INT 0 65535;
BA_DEF_ SG_  "GenSigTimeout_SCCM" INT 0 65535;
BA_DEF_ SG_  "GenSigTimeout_TBM" INT 0 65535;
BA_DEF_ SG_  "GenSigTimeout_TCM" INT 0 65535;
BA_DEF_ SG_  "GenSigTimeout_TPM" INT 0 65535;
BA_DEF_ SG_  "RID" STRING ;
BA_DEF_ SG_  "SystemSignalLongSymbol" STRING ;
BA_DEF_DEF_  "App-Botschaft" "nein";
BA_DEF_DEF_  "CanMsgMinLen" 0;
BA_DEF_DEF_  "DiagRequest" "nein";
BA_DEF_DEF_  "DiagResponse" "nein";
BA_DEF_DEF_  "DiagState" "nein";
BA_DEF_DEF_  "GenMsgCycleTime" 0;
BA_DEF_DEF_  "GenMsgCycleTimeActive" 0;
BA_DEF_DEF_  "GenMsgDelayTime" 0;
BA_DEF_DEF_  "GenMsgNrOfRepetitions" 0;
BA_DEF_DEF_  "GenMsgSendType" "cyclicX";
BA_DEF_DEF_  "GenMsgStartDelayTime" 0;
BA_DEF_DEF_  "GenMsgStartValue" "";
BA_DEF_DEF_  "NWM-Botschaft" "nein";
BA_DEF_DEF_  "TpTxIndex" 0;
BA_DEF_DEF_  "FlexKomComment" "";
BA_DEF_DEF_  "FlexKomIsMotorola" "nein";
BA_DEF_DEF_  "FlexKomSID" 0;
BA_DEF_DEF_  "FlexKomSigLaenge" 0;
BA_DEF_DEF_  "FlexKomSigName" "";
BA_DEF_DEF_  "FlexKomSigStartPos" 0;
BA_DEF_DEF_  "FlexKomSigStartValue" "";
BA_DEF_DEF_  "GenSigCycleTime" 0;
BA_DEF_DEF_  "GenSigCycleTimeActive" 0;
BA_DEF_DEF_  "GenSigSendType" "cyclicX";
BA_DEF_DEF_  "GenSigSNA" "";
BA_DEF_DEF_  "GenSigStartValue" 0;
BA_DEF_DEF_  "GenSigTimeout_AHLM" 0;
BA_DEF_DEF_  "GenSigTimeout_ASBS" 0;
BA_DEF_DEF_  "GenSigTimeout_CBC" 0;
BA_DEF_DEF_  "GenSigTimeout_DPDM" 0;
BA_DEF_DEF_  "GenSigTimeout_DTCM" 0;
BA_DEF_DEF_  "GenSigTimeout_EHPS" 0;
BA_DEF_DEF_  "GenSigTimeout_ESC" 0;
BA_DEF_DEF_  "GenSigTimeout_ESL" 0;
BA_DEF_DEF_  "GenSigTimeout_ESM" 0;
BA_DEF_DEF_  "GenSigTimeout_ETM" 0;
BA_DEF_DEF_  "GenSigTimeout_IC" 0;
BA_DEF_DEF_  "GenSigTimeout_OCM" 0;
BA_DEF_DEF_  "GenSigTimeout_ORC" 0;
BA_DEF_DEF_  "GenSigTimeout_PTS" 0;
BA_DEF_DEF_  "GenSigTimeout_RF_HUB" 0;
BA_DEF_DEF_  "GenSigTimeout_SCCM" 0;
BA_DEF_DEF_  "GenSigTimeout_TBM" 0;
BA_DEF_DEF_  "GenSigTimeout_TCM" 0;
BA_DEF_DEF_  "GenSigTimeout_TPM" 0;
BA_DEF_DEF_  "RID" "";
BA_DEF_DEF_  "SystemSignalLongSymbol" "";
BA_ "GenMsgStartValue" BO_ 131 "0F3400C003FF00FFh";
BA_ "GenMsgNrOfRepetitions" BO_ 131 2;
BA_ "GenMsgDelayTime" BO_ 131 20;
BA_ "GenMsgCycleTime" BO_ 131 20;
BA_ "GenMsgStartValue" BO_ 120 "00000000000000FFh";
BA_ "GenMsgNrOfRepetitions" BO_ 120 2;
BA_ "GenMsgDelayTime" BO_ 120 20;
BA_ "GenMsgCycleTime" BO_ 120 20;
BA_ "GenMsgStartValue" BO_ 113 "00000000FF0000FFh";
BA_ "GenMsgNrOfRepetitions" BO_ 113 2;
BA_ "GenMsgDelayTime" BO_ 113 20;
BA_ "GenMsgCycleTime" BO_ 113 20;
BA_ "GenMsgStartValue" BO_ 135 "7000FFFF00FF00FFh";
BA_ "GenMsgNrOfRepetitions" BO_ 135 2;
BA_ "GenMsgDelayTime" BO_ 135 20;
BA_ "GenMsgCycleTime" BO_ 135 20;
BA_ "GenMsgStartValue" BO_ 137 "FFFFFFFFFFFF00FFh";
BA_ "GenMsgNrOfRepetitions" BO_ 137 2;
BA_ "GenMsgDelayTime" BO_ 137 20;
BA_ "GenMsgCycleTime" BO_ 137 20;
BA_ "GenMsgStartValue" BO_ 127 "0000000000FFFFFFh";
BA_ "GenMsgNrOfRepetitions" BO_ 127 2;
BA_ "GenMsgDelayTime" BO_ 127 20;
BA_ "GenMsgCycleTime" BO_ 127 20;
BA_ "GenMsgStartValue" BO_ 139 "FFFFFFFFFFFFFFFFh";
BA_ "GenMsgNrOfRepetitions" BO_ 139 2;
BA_ "GenMsgDelayTime" BO_ 139 20;
BA_ "GenMsgCycleTime" BO_ 139 20;
BA_ "GenMsgStartValue" BO_ 121 "0FFF0FFFFFFF00FFh";
BA_ "GenMsgNrOfRepetitions" BO_ 121 2;
BA_ "GenMsgDelayTime" BO_ 121 20;
BA_ "GenMsgCycleTime" BO_ 121 20;
BA_ "GenMsgStartValue" BO_ 117 "00000000000000FFh";
BA_ "GenMsgNrOfRepetitions" BO_ 117 2;
BA_ "GenMsgDelayTime" BO_ 117 20;
BA_ "GenMsgCycleTime" BO_ 117 20;
BA_ "GenMsgStartValue" BO_ 221 "FFFFFFFF0000003Fh";
BA_ "GenMsgNrOfRepetitions" BO_ 221 2;
BA_ "GenMsgDelayTime" BO_ 221 20;
BA_ "GenMsgCycleTime" BO_ 221 50;
BA_ "GenMsgStartValue" BO_ 327 "C1FE01FE00000000h";
BA_ "GenMsgNrOfRepetitions" BO_ 327 2;
BA_ "GenMsgDelayTime" BO_ 327 20;
BA_ "GenMsgCycleTime" BO_ 327 100;
BA_ "GenMsgStartValue" BO_ 738 "00000000000000FFh";
BA_ "GenMsgNrOfRepetitions" BO_ 738 2;
BA_ "GenMsgDelayTime" BO_ 738 20;
BA_ "GenMsgCycleTime" BO_ 738 100;
BA_ "GenMsgStartValue" BO_ 840 "0000000000000000h";
BA_ "GenMsgSendType" BO_ 840 1;
BA_ "GenMsgNrOfRepetitions" BO_ 840 2;
BA_ "GenMsgDelayTime" BO_ 840 20;
BA_ "GenMsgStartValue" BO_ 1016 "0300000000000000h";
BA_ "GenMsgSendType" BO_ 1016 1;
BA_ "GenMsgNrOfRepetitions" BO_ 1016 2;
BA_ "GenMsgDelayTime" BO_ 1016 20;
BA_ "GenMsgStartValue" BO_ 989 "0300000000000000h";
BA_ "GenMsgSendType" BO_ 989 1;
BA_ "GenMsgNrOfRepetitions" BO_ 989 2;
BA_ "GenMsgDelayTime" BO_ 989 20;
BA_ "GenMsgStartValue" BO_ 988 "0300000000000000h";
BA_ "GenMsgSendType" BO_ 988 1;
BA_ "GenMsgNrOfRepetitions" BO_ 988 2;
BA_ "GenMsgDelayTime" BO_ 988 20;
BA_ "GenMsgStartValue" BO_ 987 "0300000000000000h";
BA_ "GenMsgSendType" BO_ 987 1;
BA_ "GenMsgNrOfRepetitions" BO_ 987 2;
BA_ "GenMsgDelayTime" BO_ 987 20;
BA_ "GenMsgStartValue" BO_ 986 "0300000000000000h";
BA_ "GenMsgSendType" BO_ 986 1;
BA_ "GenMsgNrOfRepetitions" BO_ 986 2;
BA_ "GenMsgDelayTime" BO_ 986 20;
BA_ "GenMsgStartValue" BO_ 985 "0300000000000000h";
BA_ "GenMsgSendType" BO_ 985 1;
BA_ "GenMsgNrOfRepetitions" BO_ 985 2;
BA_ "GenMsgDelayTime" BO_ 985 20;
BA_ "GenMsgStartValue" BO_ 707 "0300000000000000h";
BA_ "GenMsgSendType" BO_ 707 1;
BA_ "GenMsgNrOfRepetitions" BO_ 707 2;
BA_ "GenMsgDelayTime" BO_ 707 20;
BA_ "GenMsgStartValue" BO_ 714 "0300000000000000h";
BA_ "GenMsgSendType" BO_ 714 1;
BA_ "GenMsgNrOfRepetitions" BO_ 714 2;
BA_ "GenMsgDelayTime" BO_ 714 20;
BA_ "GenMsgStartValue" BO_ 715 "0300000000000000h";
BA_ "GenMsgSendType" BO_ 715 1;
BA_ "GenMsgNrOfRepetitions" BO_ 715 2;
BA_ "GenMsgDelayTime" BO_ 715 20;
BA_ "GenMsgStartValue" BO_ 716 "0300000000000000h";
BA_ "GenMsgSendType" BO_ 716 1;
BA_ "GenMsgNrOfRepetitions" BO_ 716 2;
BA_ "GenMsgDelayTime" BO_ 716 20;
BA_ "GenMsgStartValue" BO_ 1017 "0300000000000000h";
BA_ "GenMsgSendType" BO_ 1017 1;
BA_ "GenMsgNrOfRepetitions" BO_ 1017 2;
BA_ "GenMsgDelayTime" BO_ 1017 20;
BA_ "GenMsgStartValue" BO_ 1018 "0300000000000000h";
BA_ "GenMsgSendType" BO_ 1018 1;
BA_ "GenMsgNrOfRepetitions" BO_ 1018 2;
BA_ "GenMsgDelayTime" BO_ 1018 20;
BA_ "GenMsgStartValue" BO_ 1019 "0300000000000000h";
BA_ "GenMsgSendType" BO_ 1019 1;
BA_ "GenMsgNrOfRepetitions" BO_ 1019 2;
BA_ "GenMsgDelayTime" BO_ 1019 20;
BA_ "GenMsgStartValue" BO_ 1020 "0300000000000000h";
BA_ "GenMsgSendType" BO_ 1020 1;
BA_ "GenMsgNrOfRepetitions" BO_ 1020 2;
BA_ "GenMsgDelayTime" BO_ 1020 20;
BA_ "GenMsgStartValue" BO_ 1021 "0300000000000000h";
BA_ "GenMsgSendType" BO_ 1021 1;
BA_ "GenMsgNrOfRepetitions" BO_ 1021 2;
BA_ "GenMsgDelayTime" BO_ 1021 20;
BA_ "GenMsgStartValue" BO_ 1022 "0300000000000000h";
BA_ "GenMsgSendType" BO_ 1022 1;
BA_ "GenMsgNrOfRepetitions" BO_ 1022 2;
BA_ "GenMsgDelayTime" BO_ 1022 20;
BA_ "GenMsgStartValue" BO_ 1023 "0300000000000000h";
BA_ "GenMsgSendType" BO_ 1023 1;
BA_ "GenMsgNrOfRepetitions" BO_ 1023 2;
BA_ "GenMsgDelayTime" BO_ 1023 20;
BA_ "GenMsgStartValue" BO_ 991 "0300000000000000h";
BA_ "GenMsgSendType" BO_ 991 1;
BA_ "GenMsgNrOfRepetitions" BO_ 991 2;
BA_ "GenMsgDelayTime" BO_ 991 20;
BA_ "GenMsgStartValue" BO_ 1008 "0300000000000000h";
BA_ "GenMsgStartDelayTime" BO_ 1008 140;
BA_ "GenMsgNrOfRepetitions" BO_ 1008 2;
BA_ "GenMsgDelayTime" BO_ 1008 20;
BA_ "GenMsgCycleTime" BO_ 1008 2000;
BA_ "GenMsgStartValue" BO_ 983 "0300000000000000h";
BA_ "GenMsgStartDelayTime" BO_ 983 100;
BA_ "GenMsgSendType" BO_ 983 5;
BA_ "GenMsgNrOfRepetitions" BO_ 983 2;
BA_ "GenMsgDelayTime" BO_ 983 20;
BA_ "GenMsgCycleTime" BO_ 983 2000;
BA_ "GenMsgStartValue" BO_ 982 "0300000000000000h";
BA_ "GenMsgStartDelayTime" BO_ 982 130;
BA_ "GenMsgNrOfRepetitions" BO_ 982 2;
BA_ "GenMsgDelayTime" BO_ 982 20;
BA_ "GenMsgCycleTime" BO_ 982 2000;
BA_ "GenMsgStartValue" BO_ 981 "0300000000000000h";
BA_ "GenMsgStartDelayTime" BO_ 981 120;
BA_ "GenMsgSendType" BO_ 981 5;
BA_ "GenMsgNrOfRepetitions" BO_ 981 2;
BA_ "GenMsgDelayTime" BO_ 981 20;
BA_ "GenMsgCycleTime" BO_ 981 2000;
BA_ "GenMsgStartValue" BO_ 980 "0300000000000000h";
BA_ "GenMsgStartDelayTime" BO_ 980 130;
BA_ "GenMsgNrOfRepetitions" BO_ 980 2;
BA_ "GenMsgDelayTime" BO_ 980 20;
BA_ "GenMsgCycleTime" BO_ 980 2000;
BA_ "GenMsgStartValue" BO_ 979 "0300000000000000h";
BA_ "GenMsgStartDelayTime" BO_ 979 130;
BA_ "GenMsgNrOfRepetitions" BO_ 979 2;
BA_ "GenMsgDelayTime" BO_ 979 20;
BA_ "GenMsgCycleTime" BO_ 979 2000;
BA_ "GenMsgStartValue" BO_ 706 "0300000000000000h";
BA_ "GenMsgSendType" BO_ 706 5;
BA_ "GenMsgNrOfRepetitions" BO_ 706 2;
BA_ "GenMsgDelayTime" BO_ 706 20;
BA_ "GenMsgCycleTime" BO_ 706 2000;
BA_ "GenMsgStartValue" BO_ 709 "0300000000000000h";
BA_ "GenMsgSendType" BO_ 709 5;
BA_ "GenMsgNrOfRepetitions" BO_ 709 2;
BA_ "GenMsgDelayTime" BO_ 709 20;
BA_ "GenMsgCycleTime" BO_ 709 2000;
BA_ "GenMsgStartValue" BO_ 710 "0300000000000000h";
BA_ "GenMsgSendType" BO_ 710 5;
BA_ "GenMsgNrOfRepetitions" BO_ 710 2;
BA_ "GenMsgDelayTime" BO_ 710 20;
BA_ "GenMsgCycleTime" BO_ 710 2000;
BA_ "GenMsgStartValue" BO_ 711 "0300000000000000h";
BA_ "GenMsgSendType" BO_ 711 5;
BA_ "GenMsgNrOfRepetitions" BO_ 711 2;
BA_ "GenMsgDelayTime" BO_ 711 20;
BA_ "GenMsgCycleTime" BO_ 711 2000;
BA_ "GenMsgStartValue" BO_ 1009 "0300000000000000h";
BA_ "GenMsgStartDelayTime" BO_ 1009 150;
BA_ "GenMsgNrOfRepetitions" BO_ 1009 2;
BA_ "GenMsgDelayTime" BO_ 1009 20;
BA_ "GenMsgCycleTime" BO_ 1009 2000;
BA_ "GenMsgStartValue" BO_ 1010 "0300000000000000h";
BA_ "GenMsgStartDelayTime" BO_ 1010 30;
BA_ "GenMsgSendType" BO_ 1010 5;
BA_ "GenMsgNrOfRepetitions" BO_ 1010 2;
BA_ "GenMsgDelayTime" BO_ 1010 20;
BA_ "GenMsgCycleTime" BO_ 1010 2000;
BA_ "GenMsgStartValue" BO_ 1011 "0300000000000000h";
BA_ "GenMsgStartDelayTime" BO_ 1011 40;
BA_ "GenMsgSendType" BO_ 1011 5;
BA_ "GenMsgNrOfRepetitions" BO_ 1011 2;
BA_ "GenMsgDelayTime" BO_ 1011 20;
BA_ "GenMsgCycleTime" BO_ 1011 2000;
BA_ "GenMsgStartValue" BO_ 1012 "0300000000000000h";
BA_ "GenMsgStartDelayTime" BO_ 1012 50;
BA_ "GenMsgSendType" BO_ 1012 5;
BA_ "GenMsgNrOfRepetitions" BO_ 1012 2;
BA_ "GenMsgDelayTime" BO_ 1012 20;
BA_ "GenMsgCycleTime" BO_ 1012 2000;
BA_ "GenMsgStartValue" BO_ 1013 "0300000000000000h";
BA_ "GenMsgStartDelayTime" BO_ 1013 60;
BA_ "GenMsgSendType" BO_ 1013 5;
BA_ "GenMsgNrOfRepetitions" BO_ 1013 2;
BA_ "GenMsgDelayTime" BO_ 1013 20;
BA_ "GenMsgCycleTime" BO_ 1013 2000;
BA_ "GenMsgStartValue" BO_ 1014 "0300000000000000h";
BA_ "GenMsgStartDelayTime" BO_ 1014 150;
BA_ "GenMsgNrOfRepetitions" BO_ 1014 2;
BA_ "GenMsgDelayTime" BO_ 1014 20;
BA_ "GenMsgCycleTime" BO_ 1014 2000;
BA_ "RID" SG_ 131 ABS_BrkEvt "5034";
BA_ "GenSigTimeout_ORC" SG_ 131 ABS_BrkEvt 70;
BA_ "GenSigTimeout_ETM" SG_ 131 ABS_BrkEvt 210;
BA_ "GenSigTimeout_DTCM" SG_ 131 ABS_BrkEvt 210;
BA_ "GenSigSNA" SG_ 131 ABS_BrkEvt "0h";
BA_ "GenSigCycleTime" SG_ 131 ABS_BrkEvt 20;
BA_ "FlexKomSigStartValue" SG_ 131 ABS_BrkEvt "0F3400C003FF00FFh";
BA_ "FlexKomSigStartPos" SG_ 131 ABS_BrkEvt 7;
BA_ "FlexKomSigName" SG_ 131 ABS_BrkEvt "ESP_BRK_STAT";
BA_ "FlexKomSigLaenge" SG_ 131 ABS_BrkEvt 64;
BA_ "FlexKomIsMotorola" SG_ 131 ABS_BrkEvt 1;
BA_ "FlexKomComment" SG_ 131 ABS_BrkEvt "ESP Brake Status Information";
BA_ "GenSigTimeout_TBM" SG_ 131 BrkIntrvntn_Actv_AS 210;
BA_ "GenSigTimeout_ORC" SG_ 131 BrkIntrvntn_Actv_AS 70;
BA_ "GenSigSNA" SG_ 131 BrkIntrvntn_Actv_AS "0h";
BA_ "GenSigCycleTime" SG_ 131 BrkIntrvntn_Actv_AS 20;
BA_ "FlexKomSigStartValue" SG_ 131 BrkIntrvntn_Actv_AS "0F3400C003FF00FFh";
BA_ "FlexKomSigStartPos" SG_ 131 BrkIntrvntn_Actv_AS 7;
BA_ "FlexKomSigName" SG_ 131 BrkIntrvntn_Actv_AS "ESP_BRK_STAT";
BA_ "FlexKomSigLaenge" SG_ 131 BrkIntrvntn_Actv_AS 64;
BA_ "FlexKomIsMotorola" SG_ 131 BrkIntrvntn_Actv_AS 1;
BA_ "FlexKomComment" SG_ 131 BrkIntrvntn_Actv_AS "ESP Brake Status Information";
BA_ "GenSigTimeout_TBM" SG_ 131 BrkIntrvntn_Actv_ESP 210;
BA_ "GenSigTimeout_ORC" SG_ 131 BrkIntrvntn_Actv_ESP 70;
BA_ "GenSigTimeout_ESM" SG_ 131 BrkIntrvntn_Actv_ESP 210;
BA_ "GenSigTimeout_DTCM" SG_ 131 BrkIntrvntn_Actv_ESP 210;
BA_ "GenSigSNA" SG_ 131 BrkIntrvntn_Actv_ESP "0h";
BA_ "GenSigCycleTime" SG_ 131 BrkIntrvntn_Actv_ESP 20;
BA_ "FlexKomSigStartValue" SG_ 131 BrkIntrvntn_Actv_ESP "0F3400C003FF00FFh";
BA_ "FlexKomSigStartPos" SG_ 131 BrkIntrvntn_Actv_ESP 7;
BA_ "FlexKomSigName" SG_ 131 BrkIntrvntn_Actv_ESP "ESP_BRK_STAT";
BA_ "FlexKomSigLaenge" SG_ 131 BrkIntrvntn_Actv_ESP 64;
BA_ "FlexKomIsMotorola" SG_ 131 BrkIntrvntn_Actv_ESP 1;
BA_ "FlexKomComment" SG_ 131 BrkIntrvntn_Actv_ESP "ESP Brake Status Information";
BA_ "GenSigTimeout_ORC" SG_ 131 BrkIntrvntn_Enbl 70;
BA_ "GenSigSNA" SG_ 131 BrkIntrvntn_Enbl "0h";
BA_ "GenSigCycleTime" SG_ 131 BrkIntrvntn_Enbl 20;
BA_ "FlexKomSigStartValue" SG_ 131 BrkIntrvntn_Enbl "0F3400C003FF00FFh";
BA_ "FlexKomSigStartPos" SG_ 131 BrkIntrvntn_Enbl 7;
BA_ "FlexKomSigName" SG_ 131 BrkIntrvntn_Enbl "ESP_BRK_STAT";
BA_ "FlexKomSigLaenge" SG_ 131 BrkIntrvntn_Enbl 64;
BA_ "FlexKomIsMotorola" SG_ 131 BrkIntrvntn_Enbl 1;
BA_ "FlexKomComment" SG_ 131 BrkIntrvntn_Enbl "ESP Brake Status Information";
BA_ "RID" SG_ 131 BrkPdl_Flt "5033";
BA_ "GenSigSNA" SG_ 131 BrkPdl_Flt "0h";
BA_ "GenSigCycleTime" SG_ 131 BrkPdl_Flt 20;
BA_ "FlexKomSigStartValue" SG_ 131 BrkPdl_Flt "0F3400C003FF00FFh";
BA_ "FlexKomSigStartPos" SG_ 131 BrkPdl_Flt 7;
BA_ "FlexKomSigName" SG_ 131 BrkPdl_Flt "ESP_BRK_STAT";
BA_ "FlexKomSigLaenge" SG_ 131 BrkPdl_Flt 64;
BA_ "FlexKomIsMotorola" SG_ 131 BrkPdl_Flt 1;
BA_ "FlexKomComment" SG_ 131 BrkPdl_Flt "ESP Brake Status Information";
BA_ "RID" SG_ 131 BrkPdl_Stat "1135";
BA_ "GenSigTimeout_TCM" SG_ 131 BrkPdl_Stat 210;
BA_ "GenSigTimeout_ORC" SG_ 131 BrkPdl_Stat 70;
BA_ "GenSigTimeout_IC" SG_ 131 BrkPdl_Stat 210;
BA_ "GenSigTimeout_ETM" SG_ 131 BrkPdl_Stat 210;
BA_ "GenSigTimeout_ESM" SG_ 131 BrkPdl_Stat 210;
BA_ "GenSigTimeout_DTCM" SG_ 131 BrkPdl_Stat 210;
BA_ "GenSigTimeout_CBC" SG_ 131 BrkPdl_Stat 510;
BA_ "GenSigStartValue" SG_ 131 BrkPdl_Stat 3;
BA_ "GenSigSNA" SG_ 131 BrkPdl_Stat "3h";
BA_ "GenSigCycleTime" SG_ 131 BrkPdl_Stat 20;
BA_ "FlexKomSigStartValue" SG_ 131 BrkPdl_Stat "0F3400C003FF00FFh";
BA_ "FlexKomSigStartPos" SG_ 131 BrkPdl_Stat 7;
BA_ "FlexKomSigName" SG_ 131 BrkPdl_Stat "ESP_BRK_STAT";
BA_ "FlexKomSigLaenge" SG_ 131 BrkPdl_Stat 64;
BA_ "FlexKomIsMotorola" SG_ 131 BrkPdl_Stat 1;
BA_ "FlexKomComment" SG_ 131 BrkPdl_Stat "ESP Brake Status Information";
BA_ "RID" SG_ 131 Brk_Stat "1226";
BA_ "GenSigTimeout_ORC" SG_ 131 Brk_Stat 70;
BA_ "GenSigTimeout_CBC" SG_ 131 Brk_Stat 210;
BA_ "GenSigStartValue" SG_ 131 Brk_Stat 3;
BA_ "GenSigSNA" SG_ 131 Brk_Stat "3h";
BA_ "GenSigCycleTime" SG_ 131 Brk_Stat 20;
BA_ "FlexKomSigStartValue" SG_ 131 Brk_Stat "0F3400C003FF00FFh";
BA_ "FlexKomSigStartPos" SG_ 131 Brk_Stat 7;
BA_ "FlexKomSigName" SG_ 131 Brk_Stat "ESP_BRK_STAT";
BA_ "FlexKomSigLaenge" SG_ 131 Brk_Stat 64;
BA_ "FlexKomIsMotorola" SG_ 131 Brk_Stat 1;
BA_ "FlexKomComment" SG_ 131 Brk_Stat "ESP Brake Status Information";
BA_ "GenSigSNA" SG_ 131 Brk_Thermdl "0h";
BA_ "GenSigCycleTime" SG_ 131 Brk_Thermdl 20;
BA_ "FlexKomSigStartValue" SG_ 131 Brk_Thermdl "0F3400C003FF00FFh";
BA_ "FlexKomSigStartPos" SG_ 131 Brk_Thermdl 7;
BA_ "FlexKomSigName" SG_ 131 Brk_Thermdl "ESP_BRK_STAT";
BA_ "FlexKomSigLaenge" SG_ 131 Brk_Thermdl 64;
BA_ "FlexKomIsMotorola" SG_ 131 Brk_Thermdl 1;
BA_ "FlexKomComment" SG_ 131 Brk_Thermdl "ESP Brake Status Information";
BA_ "GenSigTimeout_ORC" SG_ 131 CRC_Brk_Stat 70;
BA_ "GenSigTimeout_IC" SG_ 131 CRC_Brk_Stat 210;
BA_ "GenSigTimeout_DTCM" SG_ 131 CRC_Brk_Stat 210;
BA_ "GenSigStartValue" SG_ 131 CRC_Brk_Stat 255;
BA_ "GenSigSNA" SG_ 131 CRC_Brk_Stat "FFh";
BA_ "GenSigCycleTime" SG_ 131 CRC_Brk_Stat 20;
BA_ "FlexKomSigStartValue" SG_ 131 CRC_Brk_Stat "0F3400C003FF00FFh";
BA_ "FlexKomSigStartPos" SG_ 131 CRC_Brk_Stat 7;
BA_ "FlexKomSigName" SG_ 131 CRC_Brk_Stat "ESP_BRK_STAT";
BA_ "FlexKomSigLaenge" SG_ 131 CRC_Brk_Stat 64;
BA_ "FlexKomIsMotorola" SG_ 131 CRC_Brk_Stat 1;
BA_ "FlexKomComment" SG_ 131 CRC_Brk_Stat "ESP Brake Status Information";
BA_ "GenSigSNA" SG_ 131 DTR_CC_Enabled "0h";
BA_ "GenSigCycleTime" SG_ 131 DTR_CC_Enabled 20;
BA_ "FlexKomSigStartValue" SG_ 131 DTR_CC_Enabled "0F3400C003FF00FFh";
BA_ "FlexKomSigStartPos" SG_ 131 DTR_CC_Enabled 7;
BA_ "FlexKomSigName" SG_ 131 DTR_CC_Enabled "ESP_BRK_STAT";
BA_ "FlexKomSigLaenge" SG_ 131 DTR_CC_Enabled 64;
BA_ "FlexKomIsMotorola" SG_ 131 DTR_CC_Enabled 1;
BA_ "FlexKomComment" SG_ 131 DTR_CC_Enabled "ESP Brake Status Information";
BA_ "GenSigTimeout_ORC" SG_ 131 DTR_CC_Engaged 70;
BA_ "GenSigSNA" SG_ 131 DTR_CC_Engaged "0h";
BA_ "GenSigCycleTime" SG_ 131 DTR_CC_Engaged 20;
BA_ "FlexKomSigStartValue" SG_ 131 DTR_CC_Engaged "0F3400C003FF00FFh";
BA_ "FlexKomSigStartPos" SG_ 131 DTR_CC_Engaged 7;
BA_ "FlexKomSigName" SG_ 131 DTR_CC_Engaged "ESP_BRK_STAT";
BA_ "FlexKomSigLaenge" SG_ 131 DTR_CC_Engaged 64;
BA_ "FlexKomIsMotorola" SG_ 131 DTR_CC_Engaged 1;
BA_ "FlexKomComment" SG_ 131 DTR_CC_Engaged "ESP Brake Status Information";
BA_ "GenSigTimeout_TBM" SG_ 131 ESP_Sys_Stat 210;
BA_ "GenSigTimeout_ORC" SG_ 131 ESP_Sys_Stat 70;
BA_ "GenSigTimeout_IC" SG_ 131 ESP_Sys_Stat 210;
BA_ "GenSigTimeout_DTCM" SG_ 131 ESP_Sys_Stat 210;
BA_ "GenSigStartValue" SG_ 131 ESP_Sys_Stat 1;
BA_ "GenSigSNA" SG_ 131 ESP_Sys_Stat "1h";
BA_ "GenSigCycleTime" SG_ 131 ESP_Sys_Stat 20;
BA_ "FlexKomSigStartValue" SG_ 131 ESP_Sys_Stat "0F3400C003FF00FFh";
BA_ "FlexKomSigStartPos" SG_ 131 ESP_Sys_Stat 7;
BA_ "FlexKomSigName" SG_ 131 ESP_Sys_Stat "ESP_BRK_STAT";
BA_ "FlexKomSigLaenge" SG_ 131 ESP_Sys_Stat 64;
BA_ "FlexKomIsMotorola" SG_ 131 ESP_Sys_Stat 1;
BA_ "FlexKomComment" SG_ 131 ESP_Sys_Stat "ESP Brake Status Information";
BA_ "GenSigTimeout_ORC" SG_ 131 EmgBrk_Actv 70;
BA_ "GenSigSNA" SG_ 131 EmgBrk_Actv "0h";
BA_ "GenSigCycleTime" SG_ 131 EmgBrk_Actv 20;
BA_ "FlexKomSigStartValue" SG_ 131 EmgBrk_Actv "0F3400C003FF00FFh";
BA_ "FlexKomSigStartPos" SG_ 131 EmgBrk_Actv 7;
BA_ "FlexKomSigName" SG_ 131 EmgBrk_Actv "ESP_BRK_STAT";
BA_ "FlexKomSigLaenge" SG_ 131 EmgBrk_Actv 64;
BA_ "FlexKomIsMotorola" SG_ 131 EmgBrk_Actv 1;
BA_ "FlexKomComment" SG_ 131 EmgBrk_Actv "ESP Brake Status Information";
BA_ "GenSigTimeout_ORC" SG_ 131 FullBrk_Actv 70;
BA_ "GenSigTimeout_IC" SG_ 131 FullBrk_Actv 210;
BA_ "GenSigTimeout_CBC" SG_ 131 FullBrk_Actv 210;
BA_ "GenSigSNA" SG_ 131 FullBrk_Actv "0h";
BA_ "GenSigCycleTime" SG_ 131 FullBrk_Actv 20;
BA_ "FlexKomSigStartValue" SG_ 131 FullBrk_Actv "0F3400C003FF00FFh";
BA_ "FlexKomSigStartPos" SG_ 131 FullBrk_Actv 7;
BA_ "FlexKomSigName" SG_ 131 FullBrk_Actv "ESP_BRK_STAT";
BA_ "FlexKomSigLaenge" SG_ 131 FullBrk_Actv 64;
BA_ "FlexKomIsMotorola" SG_ 131 FullBrk_Actv 1;
BA_ "FlexKomComment" SG_ 131 FullBrk_Actv "ESP Brake Status Information";
BA_ "GenSigTimeout_TCM" SG_ 131 GrMax_Rq_ESC 210;
BA_ "GenSigSNA" SG_ 131 GrMax_Rq_ESC "0h";
BA_ "GenSigCycleTime" SG_ 131 GrMax_Rq_ESC 20;
BA_ "FlexKomSigStartValue" SG_ 131 GrMax_Rq_ESC "0F3400C003FF00FFh";
BA_ "FlexKomSigStartPos" SG_ 131 GrMax_Rq_ESC 7;
BA_ "FlexKomSigName" SG_ 131 GrMax_Rq_ESC "ESP_BRK_STAT";
BA_ "FlexKomSigLaenge" SG_ 131 GrMax_Rq_ESC 64;
BA_ "FlexKomIsMotorola" SG_ 131 GrMax_Rq_ESC 1;
BA_ "FlexKomComment" SG_ 131 GrMax_Rq_ESC "ESP Brake Status Information";
BA_ "GenSigTimeout_ORC" SG_ 131 GrMinMax_Rq_DTR 70;
BA_ "GenSigSNA" SG_ 131 GrMinMax_Rq_DTR "0h";
BA_ "GenSigCycleTime" SG_ 131 GrMinMax_Rq_DTR 20;
BA_ "FlexKomSigStartValue" SG_ 131 GrMinMax_Rq_DTR "0F3400C003FF00FFh";
BA_ "FlexKomSigStartPos" SG_ 131 GrMinMax_Rq_DTR 7;
BA_ "FlexKomSigName" SG_ 131 GrMinMax_Rq_DTR "ESP_BRK_STAT";
BA_ "FlexKomSigLaenge" SG_ 131 GrMinMax_Rq_DTR 64;
BA_ "FlexKomIsMotorola" SG_ 131 GrMinMax_Rq_DTR 1;
BA_ "FlexKomComment" SG_ 131 GrMinMax_Rq_DTR "ESP Brake Status Information";
BA_ "GenSigTimeout_TCM" SG_ 131 GrMin_Rq_ESC 210;
BA_ "GenSigSNA" SG_ 131 GrMin_Rq_ESC "0h";
BA_ "GenSigCycleTime" SG_ 131 GrMin_Rq_ESC 20;
BA_ "FlexKomSigStartValue" SG_ 131 GrMin_Rq_ESC "0F3400C003FF00FFh";
BA_ "FlexKomSigStartPos" SG_ 131 GrMin_Rq_ESC 7;
BA_ "FlexKomSigName" SG_ 131 GrMin_Rq_ESC "ESP_BRK_STAT";
BA_ "FlexKomSigLaenge" SG_ 131 GrMin_Rq_ESC 64;
BA_ "FlexKomIsMotorola" SG_ 131 GrMin_Rq_ESC 1;
BA_ "FlexKomComment" SG_ 131 GrMin_Rq_ESC "ESP Brake Status Information";
BA_ "GenSigSNA" SG_ 131 HillHolderActive "0h";
BA_ "GenSigCycleTime" SG_ 131 HillHolderActive 20;
BA_ "FlexKomSigStartValue" SG_ 131 HillHolderActive "0F3400C003FF00FFh";
BA_ "FlexKomSigStartPos" SG_ 131 HillHolderActive 7;
BA_ "FlexKomSigName" SG_ 131 HillHolderActive "ESP_BRK_STAT";
BA_ "FlexKomSigLaenge" SG_ 131 HillHolderActive 64;
BA_ "FlexKomIsMotorola" SG_ 131 HillHolderActive 1;
BA_ "FlexKomComment" SG_ 131 HillHolderActive "ESP Brake Status Information";
BA_ "GenSigTimeout_ORC" SG_ 131 MC_Brk_Stat 70;
BA_ "GenSigTimeout_IC" SG_ 131 MC_Brk_Stat 210;
BA_ "GenSigTimeout_DTCM" SG_ 131 MC_Brk_Stat 210;
BA_ "GenSigSNA" SG_ 131 MC_Brk_Stat "0h";
BA_ "GenSigCycleTime" SG_ 131 MC_Brk_Stat 20;
BA_ "FlexKomSigStartValue" SG_ 131 MC_Brk_Stat "0F3400C003FF00FFh";
BA_ "FlexKomSigStartPos" SG_ 131 MC_Brk_Stat 7;
BA_ "FlexKomSigName" SG_ 131 MC_Brk_Stat "ESP_BRK_STAT";
BA_ "FlexKomSigLaenge" SG_ 131 MC_Brk_Stat 64;
BA_ "FlexKomIsMotorola" SG_ 131 MC_Brk_Stat 1;
BA_ "FlexKomComment" SG_ 131 MC_Brk_Stat "ESP Brake Status Information";
BA_ "GenSigTimeout_ORC" SG_ 131 REF_VEH_SPEED 70;
BA_ "GenSigTimeout_IC" SG_ 131 REF_VEH_SPEED 210;
BA_ "GenSigStartValue" SG_ 131 REF_VEH_SPEED 1023;
BA_ "GenSigSNA" SG_ 131 REF_VEH_SPEED "3FFh";
BA_ "GenSigCycleTime" SG_ 131 REF_VEH_SPEED 20;
BA_ "FlexKomSigStartValue" SG_ 131 REF_VEH_SPEED "0F3400C003FF00FFh";
BA_ "FlexKomSigStartPos" SG_ 131 REF_VEH_SPEED 7;
BA_ "FlexKomSigName" SG_ 131 REF_VEH_SPEED "ESP_BRK_STAT";
BA_ "FlexKomSigLaenge" SG_ 131 REF_VEH_SPEED 64;
BA_ "FlexKomIsMotorola" SG_ 131 REF_VEH_SPEED 1;
BA_ "FlexKomComment" SG_ 131 REF_VEH_SPEED "ESP Brake Status Information";
BA_ "GenSigTimeout_DTCM" SG_ 131 RollTestMd_Actv 210;
BA_ "GenSigStartValue" SG_ 131 RollTestMd_Actv 3;
BA_ "GenSigSNA" SG_ 131 RollTestMd_Actv "3h";
BA_ "GenSigCycleTime" SG_ 131 RollTestMd_Actv 20;
BA_ "FlexKomSigStartValue" SG_ 131 RollTestMd_Actv "0F3400C003FF00FFh";
BA_ "FlexKomSigStartPos" SG_ 131 RollTestMd_Actv 7;
BA_ "FlexKomSigName" SG_ 131 RollTestMd_Actv "ESP_BRK_STAT";
BA_ "FlexKomSigLaenge" SG_ 131 RollTestMd_Actv 64;
BA_ "FlexKomIsMotorola" SG_ 131 RollTestMd_Actv 1;
BA_ "FlexKomComment" SG_ 131 RollTestMd_Actv "ESP Brake Status Information";
BA_ "GenSigSNA" SG_ 131 SPCR_AS_Off_Rq "0h";
BA_ "GenSigCycleTime" SG_ 131 SPCR_AS_Off_Rq 20;
BA_ "FlexKomSigStartValue" SG_ 131 SPCR_AS_Off_Rq "0F3400C003FF00FFh";
BA_ "FlexKomSigStartPos" SG_ 131 SPCR_AS_Off_Rq 7;
BA_ "FlexKomSigName" SG_ 131 SPCR_AS_Off_Rq "ESP_BRK_STAT";
BA_ "FlexKomSigLaenge" SG_ 131 SPCR_AS_Off_Rq 64;
BA_ "FlexKomIsMotorola" SG_ 131 SPCR_AS_Off_Rq 1;
BA_ "FlexKomComment" SG_ 131 SPCR_AS_Off_Rq "ESP Brake Status Information";
BA_ "RID" SG_ 131 SelSpdSts "1982";
BA_ "GenSigTimeout_ORC" SG_ 131 SelSpdSts 70;
BA_ "GenSigTimeout_IC" SG_ 131 SelSpdSts 210;
BA_ "GenSigTimeout_ETM" SG_ 131 SelSpdSts 210;
BA_ "GenSigTimeout_CBC" SG_ 131 SelSpdSts 210;
BA_ "GenSigStartValue" SG_ 131 SelSpdSts 3;
BA_ "GenSigSNA" SG_ 131 SelSpdSts "3h";
BA_ "GenSigCycleTime" SG_ 131 SelSpdSts 20;
BA_ "FlexKomSigStartValue" SG_ 131 SelSpdSts "0F3400C003FF00FFh";
BA_ "FlexKomSigStartPos" SG_ 131 SelSpdSts 7;
BA_ "FlexKomSigName" SG_ 131 SelSpdSts "ESP_BRK_STAT";
BA_ "FlexKomSigLaenge" SG_ 131 SelSpdSts 64;
BA_ "FlexKomIsMotorola" SG_ 131 SelSpdSts 1;
BA_ "FlexKomComment" SG_ 131 SelSpdSts "ESP Brake Status Information";
BA_ "GenSigSNA" SG_ 131 ShftChrDsp_Rq_ESC "Fh";
BA_ "GenSigCycleTime" SG_ 131 ShftChrDsp_Rq_ESC 20;
BA_ "FlexKomSigStartValue" SG_ 131 ShftChrDsp_Rq_ESC "0F3400C003FF00FFh";
BA_ "FlexKomSigStartPos" SG_ 131 ShftChrDsp_Rq_ESC 7;
BA_ "FlexKomSigName" SG_ 131 ShftChrDsp_Rq_ESC "ESP_BRK_STAT";
BA_ "FlexKomSigLaenge" SG_ 131 ShftChrDsp_Rq_ESC 64;
BA_ "FlexKomIsMotorola" SG_ 131 ShftChrDsp_Rq_ESC 1;
BA_ "FlexKomComment" SG_ 131 ShftChrDsp_Rq_ESC "ESP Brake Status Information";
BA_ "GenSigSNA" SG_ 120 BSMHybridModeReq "3h";
BA_ "GenSigCycleTime" SG_ 120 BSMHybridModeReq 20;
BA_ "FlexKomSigStartValue" SG_ 120 BSMHybridModeReq "00000000000000FFh";
BA_ "FlexKomSigStartPos" SG_ 120 BSMHybridModeReq 7;
BA_ "FlexKomSigName" SG_ 120 BSMHybridModeReq "ESP_A10_Pkt";
BA_ "FlexKomSigLaenge" SG_ 120 BSMHybridModeReq 64;
BA_ "FlexKomSID" SG_ 120 BSMHybridModeReq 2964;
BA_ "FlexKomIsMotorola" SG_ 120 BSMHybridModeReq 1;
BA_ "FlexKomComment" SG_ 120 BSMHybridModeReq "ESP_A10_Pkt";
BA_ "GenSigSNA" SG_ 120 BrakeBoostPressure "7FFh";
BA_ "GenSigCycleTime" SG_ 120 BrakeBoostPressure 20;
BA_ "FlexKomSigStartValue" SG_ 120 BrakeBoostPressure "00000000000000FFh";
BA_ "FlexKomSigStartPos" SG_ 120 BrakeBoostPressure 7;
BA_ "FlexKomSigName" SG_ 120 BrakeBoostPressure "ESP_A10_Pkt";
BA_ "FlexKomSigLaenge" SG_ 120 BrakeBoostPressure 64;
BA_ "FlexKomSID" SG_ 120 BrakeBoostPressure 2964;
BA_ "FlexKomIsMotorola" SG_ 120 BrakeBoostPressure 1;
BA_ "FlexKomComment" SG_ 120 BrakeBoostPressure "ESP_A10_Pkt";
BA_ "GenSigSNA" SG_ 120 BrakeBoostStat "Fh";
BA_ "GenSigCycleTime" SG_ 120 BrakeBoostStat 20;
BA_ "FlexKomSigStartValue" SG_ 120 BrakeBoostStat "00000000000000FFh";
BA_ "FlexKomSigStartPos" SG_ 120 BrakeBoostStat 7;
BA_ "FlexKomSigName" SG_ 120 BrakeBoostStat "ESP_A10_Pkt";
BA_ "FlexKomSigLaenge" SG_ 120 BrakeBoostStat 64;
BA_ "FlexKomSID" SG_ 120 BrakeBoostStat 2964;
BA_ "FlexKomIsMotorola" SG_ 120 BrakeBoostStat 1;
BA_ "FlexKomComment" SG_ 120 BrakeBoostStat "ESP_A10_Pkt";
BA_ "GenSigSNA" SG_ 120 BrakePdlPosn "FFh";
BA_ "GenSigCycleTime" SG_ 120 BrakePdlPosn 20;
BA_ "FlexKomSigStartValue" SG_ 120 BrakePdlPosn "00000000000000FFh";
BA_ "FlexKomSigStartPos" SG_ 120 BrakePdlPosn 7;
BA_ "FlexKomSigName" SG_ 120 BrakePdlPosn "ESP_A10_Pkt";
BA_ "FlexKomSigLaenge" SG_ 120 BrakePdlPosn 64;
BA_ "FlexKomSID" SG_ 120 BrakePdlPosn 2964;
BA_ "FlexKomIsMotorola" SG_ 120 BrakePdlPosn 1;
BA_ "FlexKomComment" SG_ 120 BrakePdlPosn "ESP_A10_Pkt";
BA_ "GenSigSNA" SG_ 120 BrakePedalPressure "7FFh";
BA_ "GenSigCycleTime" SG_ 120 BrakePedalPressure 20;
BA_ "FlexKomSigStartValue" SG_ 120 BrakePedalPressure "00000000000000FFh";
BA_ "FlexKomSigStartPos" SG_ 120 BrakePedalPressure 7;
BA_ "FlexKomSigName" SG_ 120 BrakePedalPressure "ESP_A10_Pkt";
BA_ "FlexKomSigLaenge" SG_ 120 BrakePedalPressure 64;
BA_ "FlexKomSID" SG_ 120 BrakePedalPressure 2964;
BA_ "FlexKomIsMotorola" SG_ 120 BrakePedalPressure 1;
BA_ "FlexKomComment" SG_ 120 BrakePedalPressure "ESP_A10_Pkt";
BA_ "GenSigStartValue" SG_ 120 CRC_ESP_A10 255;
BA_ "GenSigSNA" SG_ 120 CRC_ESP_A10 "FFh";
BA_ "GenSigCycleTime" SG_ 120 CRC_ESP_A10 20;
BA_ "FlexKomSigStartValue" SG_ 120 CRC_ESP_A10 "00000000000000FFh";
BA_ "FlexKomSigStartPos" SG_ 120 CRC_ESP_A10 7;
BA_ "FlexKomSigName" SG_ 120 CRC_ESP_A10 "ESP_A10_Pkt";
BA_ "FlexKomSigLaenge" SG_ 120 CRC_ESP_A10 64;
BA_ "FlexKomSID" SG_ 120 CRC_ESP_A10 2964;
BA_ "FlexKomIsMotorola" SG_ 120 CRC_ESP_A10 1;
BA_ "FlexKomComment" SG_ 120 CRC_ESP_A10 "ESP_A10_Pkt";
BA_ "GenSigSNA" SG_ 120 MC_ESP_A10 "0h";
BA_ "GenSigCycleTime" SG_ 120 MC_ESP_A10 20;
BA_ "FlexKomSigStartValue" SG_ 120 MC_ESP_A10 "00000000000000FFh";
BA_ "FlexKomSigStartPos" SG_ 120 MC_ESP_A10 7;
BA_ "FlexKomSigName" SG_ 120 MC_ESP_A10 "ESP_A10_Pkt";
BA_ "FlexKomSigLaenge" SG_ 120 MC_ESP_A10 64;
BA_ "FlexKomSID" SG_ 120 MC_ESP_A10 2964;
BA_ "FlexKomIsMotorola" SG_ 120 MC_ESP_A10 1;
BA_ "FlexKomComment" SG_ 120 MC_ESP_A10 "ESP_A10_Pkt";
BA_ "RID" SG_ 113 ASRActive "5029";
BA_ "GenSigSNA" SG_ 113 ASRActive "0h";
BA_ "GenSigCycleTime" SG_ 113 ASRActive 20;
BA_ "FlexKomSigStartValue" SG_ 113 ASRActive "00000000FF0000FFh";
BA_ "FlexKomSigStartPos" SG_ 113 ASRActive 7;
BA_ "FlexKomSigName" SG_ 113 ASRActive "Eng_Trq_Rq";
BA_ "FlexKomSigLaenge" SG_ 113 ASRActive 64;
BA_ "FlexKomSID" SG_ 113 ASRActive 1;
BA_ "FlexKomIsMotorola" SG_ 113 ASRActive 1;
BA_ "FlexKomComment" SG_ 113 ASRActive "Engine torque request from ESC";
BA_ "GenSigTimeout_ORC" SG_ 113 BrkBstrVac 70;
BA_ "GenSigStartValue" SG_ 113 BrkBstrVac 255;
BA_ "GenSigSNA" SG_ 113 BrkBstrVac "FFh";
BA_ "GenSigCycleTime" SG_ 113 BrkBstrVac 20;
BA_ "FlexKomSigStartValue" SG_ 113 BrkBstrVac "00000000FF0000FFh";
BA_ "FlexKomSigStartPos" SG_ 113 BrkBstrVac 7;
BA_ "FlexKomSigName" SG_ 113 BrkBstrVac "Eng_Trq_Rq";
BA_ "FlexKomSigLaenge" SG_ 113 BrkBstrVac 64;
BA_ "FlexKomSID" SG_ 113 BrkBstrVac 1;
BA_ "FlexKomIsMotorola" SG_ 113 BrkBstrVac 1;
BA_ "FlexKomComment" SG_ 113 BrkBstrVac "Engine torque request from ESC";
BA_ "GenSigTimeout_ORC" SG_ 113 Brk_Jrk_Rsp 70;
BA_ "GenSigSNA" SG_ 113 Brk_Jrk_Rsp "0h";
BA_ "GenSigCycleTime" SG_ 113 Brk_Jrk_Rsp 20;
BA_ "FlexKomSigStartValue" SG_ 113 Brk_Jrk_Rsp "00000000FF0000FFh";
BA_ "FlexKomSigStartPos" SG_ 113 Brk_Jrk_Rsp 7;
BA_ "FlexKomSigName" SG_ 113 Brk_Jrk_Rsp "Eng_Trq_Rq";
BA_ "FlexKomSigLaenge" SG_ 113 Brk_Jrk_Rsp 64;
BA_ "FlexKomSID" SG_ 113 Brk_Jrk_Rsp 1;
BA_ "FlexKomIsMotorola" SG_ 113 Brk_Jrk_Rsp 1;
BA_ "FlexKomComment" SG_ 113 Brk_Jrk_Rsp "Engine torque request from ESC";
BA_ "GenSigStartValue" SG_ 113 CRC_ENG_RQ_ESC 255;
BA_ "GenSigSNA" SG_ 113 CRC_ENG_RQ_ESC "FFh";
BA_ "GenSigCycleTime" SG_ 113 CRC_ENG_RQ_ESC 20;
BA_ "FlexKomSigStartValue" SG_ 113 CRC_ENG_RQ_ESC "00000000FF0000FFh";
BA_ "FlexKomSigStartPos" SG_ 113 CRC_ENG_RQ_ESC 7;
BA_ "FlexKomSigName" SG_ 113 CRC_ENG_RQ_ESC "Eng_Trq_Rq";
BA_ "FlexKomSigLaenge" SG_ 113 CRC_ENG_RQ_ESC 64;
BA_ "FlexKomSID" SG_ 113 CRC_ENG_RQ_ESC 1;
BA_ "FlexKomIsMotorola" SG_ 113 CRC_ENG_RQ_ESC 1;
BA_ "FlexKomComment" SG_ 113 CRC_ENG_RQ_ESC "Engine torque request from ESC";
BA_ "GenSigTimeout_ORC" SG_ 113 DAS_Enbl_Rq 70;
BA_ "GenSigSNA" SG_ 113 DAS_Enbl_Rq "0h";
BA_ "GenSigCycleTime" SG_ 113 DAS_Enbl_Rq 20;
BA_ "FlexKomSigStartValue" SG_ 113 DAS_Enbl_Rq "00000000FF0000FFh";
BA_ "FlexKomSigStartPos" SG_ 113 DAS_Enbl_Rq 7;
BA_ "FlexKomSigName" SG_ 113 DAS_Enbl_Rq "Eng_Trq_Rq";
BA_ "FlexKomSigLaenge" SG_ 113 DAS_Enbl_Rq 64;
BA_ "FlexKomSID" SG_ 113 DAS_Enbl_Rq 1;
BA_ "FlexKomIsMotorola" SG_ 113 DAS_Enbl_Rq 1;
BA_ "FlexKomComment" SG_ 113 DAS_Enbl_Rq "Engine torque request from ESC";
BA_ "GenSigTimeout_ORC" SG_ 113 DAS_RqActv 70;
BA_ "GenSigSNA" SG_ 113 DAS_RqActv "7h";
BA_ "GenSigCycleTime" SG_ 113 DAS_RqActv 20;
BA_ "FlexKomSigStartValue" SG_ 113 DAS_RqActv "00000000FF0000FFh";
BA_ "FlexKomSigStartPos" SG_ 113 DAS_RqActv 7;
BA_ "FlexKomSigName" SG_ 113 DAS_RqActv "Eng_Trq_Rq";
BA_ "FlexKomSigLaenge" SG_ 113 DAS_RqActv 64;
BA_ "FlexKomSID" SG_ 113 DAS_RqActv 1;
BA_ "FlexKomIsMotorola" SG_ 113 DAS_RqActv 1;
BA_ "FlexKomComment" SG_ 113 DAS_RqActv "Engine torque request from ESC";
BA_ "GenSigSNA" SG_ 113 DsblFuelShutOff "0h";
BA_ "GenSigCycleTime" SG_ 113 DsblFuelShutOff 20;
BA_ "FlexKomSigStartValue" SG_ 113 DsblFuelShutOff "00000000FF0000FFh";
BA_ "FlexKomSigStartPos" SG_ 113 DsblFuelShutOff 7;
BA_ "FlexKomSigName" SG_ 113 DsblFuelShutOff "Eng_Trq_Rq";
BA_ "FlexKomSigLaenge" SG_ 113 DsblFuelShutOff 64;
BA_ "FlexKomSID" SG_ 113 DsblFuelShutOff 1;
BA_ "FlexKomIsMotorola" SG_ 113 DsblFuelShutOff 1;
BA_ "FlexKomComment" SG_ 113 DsblFuelShutOff "Engine torque request from ESC";
BA_ "GenSigSNA" SG_ 113 EngTrqMax_Rq_AS "0h";
BA_ "GenSigCycleTime" SG_ 113 EngTrqMax_Rq_AS 20;
BA_ "FlexKomSigStartValue" SG_ 113 EngTrqMax_Rq_AS "00000000FF0000FFh";
BA_ "FlexKomSigStartPos" SG_ 113 EngTrqMax_Rq_AS 7;
BA_ "FlexKomSigName" SG_ 113 EngTrqMax_Rq_AS "Eng_Trq_Rq";
BA_ "FlexKomSigLaenge" SG_ 113 EngTrqMax_Rq_AS 64;
BA_ "FlexKomSID" SG_ 113 EngTrqMax_Rq_AS 1;
BA_ "FlexKomIsMotorola" SG_ 113 EngTrqMax_Rq_AS 1;
BA_ "FlexKomComment" SG_ 113 EngTrqMax_Rq_AS "Engine torque request from ESC";
BA_ "GenSigSNA" SG_ 113 EngTrqMax_Rq_ESC "0h";
BA_ "GenSigCycleTime" SG_ 113 EngTrqMax_Rq_ESC 20;
BA_ "FlexKomSigStartValue" SG_ 113 EngTrqMax_Rq_ESC "00000000FF0000FFh";
BA_ "FlexKomSigStartPos" SG_ 113 EngTrqMax_Rq_ESC 7;
BA_ "FlexKomSigName" SG_ 113 EngTrqMax_Rq_ESC "Eng_Trq_Rq";
BA_ "FlexKomSigLaenge" SG_ 113 EngTrqMax_Rq_ESC 64;
BA_ "FlexKomSID" SG_ 113 EngTrqMax_Rq_ESC 1;
BA_ "FlexKomIsMotorola" SG_ 113 EngTrqMax_Rq_ESC 1;
BA_ "FlexKomComment" SG_ 113 EngTrqMax_Rq_ESC "Engine torque request from ESC";
BA_ "GenSigTimeout_DTCM" SG_ 113 EngTrqMin_Rq_ESC 210;
BA_ "GenSigSNA" SG_ 113 EngTrqMin_Rq_ESC "0h";
BA_ "GenSigCycleTime" SG_ 113 EngTrqMin_Rq_ESC 20;
BA_ "FlexKomSigStartValue" SG_ 113 EngTrqMin_Rq_ESC "00000000FF0000FFh";
BA_ "FlexKomSigStartPos" SG_ 113 EngTrqMin_Rq_ESC 7;
BA_ "FlexKomSigName" SG_ 113 EngTrqMin_Rq_ESC "Eng_Trq_Rq";
BA_ "FlexKomSigLaenge" SG_ 113 EngTrqMin_Rq_ESC 64;
BA_ "FlexKomSID" SG_ 113 EngTrqMin_Rq_ESC 1;
BA_ "FlexKomIsMotorola" SG_ 113 EngTrqMin_Rq_ESC 1;
BA_ "FlexKomComment" SG_ 113 EngTrqMin_Rq_ESC "Engine torque request from ESC";
BA_ "GenSigTimeout_ORC" SG_ 113 EngTrq_Rq_As 70;
BA_ "GenSigSNA" SG_ 113 EngTrq_Rq_As "1FFFh";
BA_ "GenSigCycleTime" SG_ 113 EngTrq_Rq_As 20;
BA_ "FlexKomSigStartValue" SG_ 113 EngTrq_Rq_As "00000000FF0000FFh";
BA_ "FlexKomSigStartPos" SG_ 113 EngTrq_Rq_As 7;
BA_ "FlexKomSigName" SG_ 113 EngTrq_Rq_As "Eng_Trq_Rq";
BA_ "FlexKomSigLaenge" SG_ 113 EngTrq_Rq_As 64;
BA_ "FlexKomSID" SG_ 113 EngTrq_Rq_As 1;
BA_ "FlexKomIsMotorola" SG_ 113 EngTrq_Rq_As 1;
BA_ "FlexKomComment" SG_ 113 EngTrq_Rq_As "Engine torque request from ESC";
BA_ "GenSigTimeout_TBM" SG_ 113 EngTrq_Rq_ESC 210;
BA_ "GenSigTimeout_ETM" SG_ 113 EngTrq_Rq_ESC 210;
BA_ "GenSigTimeout_DTCM" SG_ 113 EngTrq_Rq_ESC 210;
BA_ "GenSigSNA" SG_ 113 EngTrq_Rq_ESC "1FFFh";
BA_ "GenSigCycleTime" SG_ 113 EngTrq_Rq_ESC 20;
BA_ "FlexKomSigStartValue" SG_ 113 EngTrq_Rq_ESC "00000000FF0000FFh";
BA_ "FlexKomSigStartPos" SG_ 113 EngTrq_Rq_ESC 7;
BA_ "FlexKomSigName" SG_ 113 EngTrq_Rq_ESC "Eng_Trq_Rq";
BA_ "FlexKomSigLaenge" SG_ 113 EngTrq_Rq_ESC 64;
BA_ "FlexKomSID" SG_ 113 EngTrq_Rq_ESC 1;
BA_ "FlexKomIsMotorola" SG_ 113 EngTrq_Rq_ESC 1;
BA_ "FlexKomComment" SG_ 113 EngTrq_Rq_ESC "Engine torque request from ESC";
BA_ "GenSigSNA" SG_ 113 MC_ENG_RQ_ESC "0h";
BA_ "GenSigCycleTime" SG_ 113 MC_ENG_RQ_ESC 20;
BA_ "FlexKomSigStartValue" SG_ 113 MC_ENG_RQ_ESC "00000000FF0000FFh";
BA_ "FlexKomSigStartPos" SG_ 113 MC_ENG_RQ_ESC 7;
BA_ "FlexKomSigName" SG_ 113 MC_ENG_RQ_ESC "Eng_Trq_Rq";
BA_ "FlexKomSigLaenge" SG_ 113 MC_ENG_RQ_ESC 64;
BA_ "FlexKomSID" SG_ 113 MC_ENG_RQ_ESC 1;
BA_ "FlexKomIsMotorola" SG_ 113 MC_ENG_RQ_ESC 1;
BA_ "FlexKomComment" SG_ 113 MC_ENG_RQ_ESC "Engine torque request from ESC";
BA_ "GenSigSNA" SG_ 113 PrefillActive "0h";
BA_ "GenSigCycleTime" SG_ 113 PrefillActive 20;
BA_ "FlexKomSigStartValue" SG_ 113 PrefillActive "00000000FF0000FFh";
BA_ "FlexKomSigStartPos" SG_ 113 PrefillActive 7;
BA_ "FlexKomSigName" SG_ 113 PrefillActive "Eng_Trq_Rq";
BA_ "FlexKomSigLaenge" SG_ 113 PrefillActive 64;
BA_ "FlexKomSID" SG_ 113 PrefillActive 1;
BA_ "FlexKomIsMotorola" SG_ 113 PrefillActive 1;
BA_ "FlexKomComment" SG_ 113 PrefillActive "Engine torque request from ESC";
BA_ "GenSigStartValue" SG_ 135 BrkBstrVac_OBD 255;
BA_ "GenSigSNA" SG_ 135 BrkBstrVac_OBD "FFh";
BA_ "GenSigCycleTime" SG_ 135 BrkBstrVac_OBD 20;
BA_ "FlexKomSigStartValue" SG_ 135 BrkBstrVac_OBD "7000FFFF00FF00FFh";
BA_ "FlexKomSigStartPos" SG_ 135 BrkBstrVac_OBD 7;
BA_ "FlexKomSigName" SG_ 135 BrkBstrVac_OBD "ESC_data";
BA_ "FlexKomSigLaenge" SG_ 135 BrkBstrVac_OBD 64;
BA_ "FlexKomSID" SG_ 135 BrkBstrVac_OBD 1416;
BA_ "FlexKomIsMotorola" SG_ 135 BrkBstrVac_OBD 1;
BA_ "FlexKomComment" SG_ 135 BrkBstrVac_OBD "ESC data";
BA_ "GenSigTimeout_TBM" SG_ 135 BrkPrss_TMC 210;
BA_ "GenSigTimeout_ORC" SG_ 135 BrkPrss_TMC 70;
BA_ "GenSigTimeout_IC" SG_ 135 BrkPrss_TMC 210;
BA_ "GenSigTimeout_ETM" SG_ 135 BrkPrss_TMC 210;
BA_ "GenSigTimeout_DTCM" SG_ 135 BrkPrss_TMC 210;
BA_ "GenSigSNA" SG_ 135 BrkPrss_TMC "7FFh";
BA_ "GenSigCycleTime" SG_ 135 BrkPrss_TMC 20;
BA_ "FlexKomSigStartValue" SG_ 135 BrkPrss_TMC "7000FFFF00FF00FFh";
BA_ "FlexKomSigStartPos" SG_ 135 BrkPrss_TMC 7;
BA_ "FlexKomSigName" SG_ 135 BrkPrss_TMC "ESC_data";
BA_ "FlexKomSigLaenge" SG_ 135 BrkPrss_TMC 64;
BA_ "FlexKomSID" SG_ 135 BrkPrss_TMC 1416;
BA_ "FlexKomIsMotorola" SG_ 135 BrkPrss_TMC 1;
BA_ "FlexKomComment" SG_ 135 BrkPrss_TMC "ESC data";
BA_ "GenSigTimeout_ORC" SG_ 135 CRC_ESP_A3 70;
BA_ "GenSigStartValue" SG_ 135 CRC_ESP_A3 255;
BA_ "GenSigSNA" SG_ 135 CRC_ESP_A3 "FFh";
BA_ "GenSigCycleTime" SG_ 135 CRC_ESP_A3 20;
BA_ "FlexKomSigStartValue" SG_ 135 CRC_ESP_A3 "7000FFFF00FF00FFh";
BA_ "FlexKomSigStartPos" SG_ 135 CRC_ESP_A3 7;
BA_ "FlexKomSigName" SG_ 135 CRC_ESP_A3 "ESC_data";
BA_ "FlexKomSigLaenge" SG_ 135 CRC_ESP_A3 64;
BA_ "FlexKomSID" SG_ 135 CRC_ESP_A3 1416;
BA_ "FlexKomIsMotorola" SG_ 135 CRC_ESP_A3 1;
BA_ "FlexKomComment" SG_ 135 CRC_ESP_A3 "ESC data";
BA_ "GenSigTimeout_TBM" SG_ 135 HSA_BrkPrss 210;
BA_ "GenSigTimeout_ORC" SG_ 135 HSA_BrkPrss 70;
BA_ "GenSigTimeout_ETM" SG_ 135 HSA_BrkPrss 210;
BA_ "GenSigSNA" SG_ 135 HSA_BrkPrss "3Fh";
BA_ "GenSigCycleTime" SG_ 135 HSA_BrkPrss 20;
BA_ "FlexKomSigStartValue" SG_ 135 HSA_BrkPrss "7000FFFF00FF00FFh";
BA_ "FlexKomSigStartPos" SG_ 135 HSA_BrkPrss 7;
BA_ "FlexKomSigName" SG_ 135 HSA_BrkPrss "ESC_data";
BA_ "FlexKomSigLaenge" SG_ 135 HSA_BrkPrss 64;
BA_ "FlexKomSID" SG_ 135 HSA_BrkPrss 1416;
BA_ "FlexKomIsMotorola" SG_ 135 HSA_BrkPrss 1;
BA_ "FlexKomComment" SG_ 135 HSA_BrkPrss "ESC data";
BA_ "GenSigTimeout_ORC" SG_ 135 MC_ESP_A3 70;
BA_ "GenSigSNA" SG_ 135 MC_ESP_A3 "0h";
BA_ "GenSigCycleTime" SG_ 135 MC_ESP_A3 20;
BA_ "FlexKomSigStartValue" SG_ 135 MC_ESP_A3 "7000FFFF00FF00FFh";
BA_ "FlexKomSigStartPos" SG_ 135 MC_ESP_A3 7;
BA_ "FlexKomSigName" SG_ 135 MC_ESP_A3 "ESC_data";
BA_ "FlexKomSigLaenge" SG_ 135 MC_ESP_A3 64;
BA_ "FlexKomSID" SG_ 135 MC_ESP_A3 1416;
BA_ "FlexKomIsMotorola" SG_ 135 MC_ESP_A3 1;
BA_ "FlexKomComment" SG_ 135 MC_ESP_A3 "ESC data";
BA_ "GenSigTimeout_TBM" SG_ 137 MC_VEH_DYN_STAT 210;
BA_ "GenSigTimeout_ORC" SG_ 137 MC_VEH_DYN_STAT 70;
BA_ "GenSigTimeout_ETM" SG_ 137 MC_VEH_DYN_STAT 210;
BA_ "GenSigSNA" SG_ 137 MC_VEH_DYN_STAT "0h";
BA_ "GenSigCycleTime" SG_ 137 MC_VEH_DYN_STAT 20;
BA_ "FlexKomSigStartValue" SG_ 137 MC_VEH_DYN_STAT "00h";
BA_ "FlexKomSigStartPos" SG_ 137 MC_VEH_DYN_STAT 55;
BA_ "FlexKomSigName" SG_ 137 MC_VEH_DYN_STAT "MC_VEH_DYN_STAT";
BA_ "FlexKomSigLaenge" SG_ 137 MC_VEH_DYN_STAT 4;
BA_ "FlexKomSID" SG_ 137 MC_VEH_DYN_STAT 1267;
BA_ "FlexKomIsMotorola" SG_ 137 MC_VEH_DYN_STAT 1;
BA_ "FlexKomComment" SG_ 137 MC_VEH_DYN_STAT "Message counter";
BA_ "RID" SG_ 137 VehAccel_X "1277";
BA_ "GenSigTimeout_ORC" SG_ 137 VehAccel_X 70;
BA_ "GenSigTimeout_IC" SG_ 137 VehAccel_X 210;
BA_ "GenSigTimeout_CBC" SG_ 137 VehAccel_X 210;
BA_ "GenSigStartValue" SG_ 137 VehAccel_X 255;
BA_ "GenSigSNA" SG_ 137 VehAccel_X "FFh";
BA_ "GenSigCycleTime" SG_ 137 VehAccel_X 20;
BA_ "FlexKomSigStartValue" SG_ 137 VehAccel_X "FFh";
BA_ "FlexKomSigStartPos" SG_ 137 VehAccel_X 39;
BA_ "FlexKomSigName" SG_ 137 VehAccel_X "VehAccel_X";
BA_ "FlexKomSigLaenge" SG_ 137 VehAccel_X 8;
BA_ "FlexKomSID" SG_ 137 VehAccel_X 1265;
BA_ "FlexKomIsMotorola" SG_ 137 VehAccel_X 1;
BA_ "FlexKomComment" SG_ 137 VehAccel_X "Vehicle longitudinal acceleration (+ means forward";
BA_ "GenSigTimeout_TBM" SG_ 137 VehAccel_X_Offset 210;
BA_ "GenSigTimeout_ORC" SG_ 137 VehAccel_X_Offset 70;
BA_ "GenSigTimeout_IC" SG_ 137 VehAccel_X_Offset 210;
BA_ "GenSigTimeout_ETM" SG_ 137 VehAccel_X_Offset 210;
BA_ "GenSigStartValue" SG_ 137 VehAccel_X_Offset 255;
BA_ "GenSigSNA" SG_ 137 VehAccel_X_Offset "FFh";
BA_ "GenSigCycleTime" SG_ 137 VehAccel_X_Offset 20;
BA_ "FlexKomSigStartValue" SG_ 137 VehAccel_X_Offset "FFh";
BA_ "FlexKomSigStartPos" SG_ 137 VehAccel_X_Offset 31;
BA_ "FlexKomSigName" SG_ 137 VehAccel_X_Offset "VehAccel_X_Offset";
BA_ "FlexKomSigLaenge" SG_ 137 VehAccel_X_Offset 8;
BA_ "FlexKomSID" SG_ 137 VehAccel_X_Offset 1264;
BA_ "FlexKomIsMotorola" SG_ 137 VehAccel_X_Offset 1;
BA_ "FlexKomComment" SG_ 137 VehAccel_X_Offset "Offset of vehicle longitudinal acceleration (+ mea";
BA_ "RID" SG_ 137 VehAccel_Y "1137";
BA_ "GenSigTimeout_ORC" SG_ 137 VehAccel_Y 70;
BA_ "GenSigTimeout_IC" SG_ 137 VehAccel_Y 210;
BA_ "GenSigTimeout_DTCM" SG_ 137 VehAccel_Y 210;
BA_ "GenSigTimeout_CBC" SG_ 137 VehAccel_Y 210;
BA_ "GenSigStartValue" SG_ 137 VehAccel_Y 255;
BA_ "GenSigSNA" SG_ 137 VehAccel_Y "FFh";
BA_ "GenSigCycleTime" SG_ 137 VehAccel_Y 20;
BA_ "FlexKomSigStartValue" SG_ 137 VehAccel_Y "FFh";
BA_ "FlexKomSigStartPos" SG_ 137 VehAccel_Y 47;
BA_ "FlexKomSigName" SG_ 137 VehAccel_Y "VehAccel_Y";
BA_ "FlexKomSigLaenge" SG_ 137 VehAccel_Y 8;
BA_ "FlexKomSID" SG_ 137 VehAccel_Y 1266;
BA_ "FlexKomIsMotorola" SG_ 137 VehAccel_Y 1;
BA_ "FlexKomComment" SG_ 137 VehAccel_Y "Vehicle lateral acceleration (+ means left, specif";
BA_ "GenSigTimeout_TBM" SG_ 137 VehAccel_Y_Offset 210;
BA_ "GenSigTimeout_ORC" SG_ 137 VehAccel_Y_Offset 70;
BA_ "GenSigTimeout_IC" SG_ 137 VehAccel_Y_Offset 210;
BA_ "GenSigTimeout_ETM" SG_ 137 VehAccel_Y_Offset 210;
BA_ "GenSigStartValue" SG_ 137 VehAccel_Y_Offset 255;
BA_ "GenSigSNA" SG_ 137 VehAccel_Y_Offset "FFh";
BA_ "GenSigCycleTime" SG_ 137 VehAccel_Y_Offset 20;
BA_ "FlexKomSigStartValue" SG_ 137 VehAccel_Y_Offset "FFh";
BA_ "FlexKomSigStartPos" SG_ 137 VehAccel_Y_Offset 63;
BA_ "FlexKomSigName" SG_ 137 VehAccel_Y_Offset "VehAccel_Y_Offset";
BA_ "FlexKomSigLaenge" SG_ 137 VehAccel_Y_Offset 8;
BA_ "FlexKomSID" SG_ 137 VehAccel_Y_Offset 1268;
BA_ "FlexKomIsMotorola" SG_ 137 VehAccel_Y_Offset 1;
BA_ "FlexKomComment" SG_ 137 VehAccel_Y_Offset "Offset of vehicle lateral acceleration (+ means le";
BA_ "RID" SG_ 137 VehYawRate_Offset "1299 1710 5037";
BA_ "GenSigTimeout_ORC" SG_ 137 VehYawRate_Offset 70;
BA_ "GenSigTimeout_IC" SG_ 137 VehYawRate_Offset 210;
BA_ "GenSigTimeout_ETM" SG_ 137 VehYawRate_Offset 210;
BA_ "GenSigTimeout_CBC" SG_ 137 VehYawRate_Offset 210;
BA_ "GenSigStartValue" SG_ 137 VehYawRate_Offset 255;
BA_ "GenSigSNA" SG_ 137 VehYawRate_Offset "FFh";
BA_ "GenSigCycleTime" SG_ 137 VehYawRate_Offset 20;
BA_ "FlexKomSigStartValue" SG_ 137 VehYawRate_Offset "FFh";
BA_ "FlexKomSigStartPos" SG_ 137 VehYawRate_Offset 23;
BA_ "FlexKomSigName" SG_ 137 VehYawRate_Offset "VehYawRate_Offset";
BA_ "FlexKomSigLaenge" SG_ 137 VehYawRate_Offset 8;
BA_ "FlexKomSID" SG_ 137 VehYawRate_Offset 1263;
BA_ "FlexKomIsMotorola" SG_ 137 VehYawRate_Offset 1;
BA_ "FlexKomComment" SG_ 137 VehYawRate_Offset "Offset of vehicle yaw rate unfiltered/unadjusted (";
BA_ "RID" SG_ 137 VehYawRate_Raw "1058 1289 1711";
BA_ "GenSigTimeout_TBM" SG_ 137 VehYawRate_Raw 210;
BA_ "GenSigTimeout_ORC" SG_ 137 VehYawRate_Raw 70;
BA_ "GenSigTimeout_IC" SG_ 137 VehYawRate_Raw 210;
BA_ "GenSigTimeout_DTCM" SG_ 137 VehYawRate_Raw 210;
BA_ "GenSigTimeout_CBC" SG_ 137 VehYawRate_Raw 210;
BA_ "GenSigStartValue" SG_ 137 VehYawRate_Raw 65535;
BA_ "GenSigSNA" SG_ 137 VehYawRate_Raw "FFFFh";
BA_ "GenSigCycleTime" SG_ 137 VehYawRate_Raw 20;
BA_ "FlexKomSigStartValue" SG_ 137 VehYawRate_Raw "FFFFh";
BA_ "FlexKomSigStartPos" SG_ 137 VehYawRate_Raw 7;
BA_ "FlexKomSigName" SG_ 137 VehYawRate_Raw "VehYawRate_Raw";
BA_ "FlexKomSigLaenge" SG_ 137 VehYawRate_Raw 16;
BA_ "FlexKomSID" SG_ 137 VehYawRate_Raw 1262;
BA_ "FlexKomIsMotorola" SG_ 137 VehYawRate_Raw 1;
BA_ "FlexKomComment" SG_ 137 VehYawRate_Raw "Vehicle yaw rate unfiltered/unadjusted (+ means le";
BA_ "GenSigTimeout_DTCM" SG_ 127 CENT_DIFF_ESP_RQ 210;
BA_ "GenSigSNA" SG_ 127 CENT_DIFF_ESP_RQ "3h";
BA_ "GenSigCycleTime" SG_ 127 CENT_DIFF_ESP_RQ 20;
BA_ "FlexKomSigStartValue" SG_ 127 CENT_DIFF_ESP_RQ "00FFFFFFh";
BA_ "FlexKomSigStartPos" SG_ 127 CENT_DIFF_ESP_RQ 39;
BA_ "FlexKomSigName" SG_ 127 CENT_DIFF_ESP_RQ "ESP_DIFF_RQ";
BA_ "FlexKomSigLaenge" SG_ 127 CENT_DIFF_ESP_RQ 32;
BA_ "FlexKomSID" SG_ 127 CENT_DIFF_ESP_RQ 394;
BA_ "FlexKomIsMotorola" SG_ 127 CENT_DIFF_ESP_RQ 1;
BA_ "FlexKomComment" SG_ 127 CENT_DIFF_ESP_RQ "ESP DIFF Control Requests";
BA_ "GenSigTimeout_DTCM" SG_ 127 CENT_DIFF_TRQ_RQ 210;
BA_ "GenSigStartValue" SG_ 127 CENT_DIFF_TRQ_RQ 255;
BA_ "GenSigSNA" SG_ 127 CENT_DIFF_TRQ_RQ "FFh";
BA_ "GenSigCycleTime" SG_ 127 CENT_DIFF_TRQ_RQ 20;
BA_ "FlexKomSigStartValue" SG_ 127 CENT_DIFF_TRQ_RQ "00FFFFFFh";
BA_ "FlexKomSigStartPos" SG_ 127 CENT_DIFF_TRQ_RQ 39;
BA_ "FlexKomSigName" SG_ 127 CENT_DIFF_TRQ_RQ "ESP_DIFF_RQ";
BA_ "FlexKomSigLaenge" SG_ 127 CENT_DIFF_TRQ_RQ 32;
BA_ "FlexKomSID" SG_ 127 CENT_DIFF_TRQ_RQ 394;
BA_ "FlexKomIsMotorola" SG_ 127 CENT_DIFF_TRQ_RQ 1;
BA_ "FlexKomComment" SG_ 127 CENT_DIFF_TRQ_RQ "ESP DIFF Control Requests";
BA_ "RID" SG_ 127 WhlPlsCnt_FL "1251";
BA_ "GenSigTimeout_IC" SG_ 127 WhlPlsCnt_FL 210;
BA_ "GenSigTimeout_CBC" SG_ 127 WhlPlsCnt_FL 210;
BA_ "GenSigSNA" SG_ 127 WhlPlsCnt_FL "FFh";
BA_ "GenSigCycleTime" SG_ 127 WhlPlsCnt_FL 20;
BA_ "FlexKomSigStartValue" SG_ 127 WhlPlsCnt_FL "00000000h";
BA_ "FlexKomSigStartPos" SG_ 127 WhlPlsCnt_FL 7;
BA_ "FlexKomSigName" SG_ 127 WhlPlsCnt_FL "ESP_WHL_PULS";
BA_ "FlexKomSigLaenge" SG_ 127 WhlPlsCnt_FL 32;
BA_ "FlexKomSID" SG_ 127 WhlPlsCnt_FL 65;
BA_ "FlexKomIsMotorola" SG_ 127 WhlPlsCnt_FL 1;
BA_ "FlexKomComment" SG_ 127 WhlPlsCnt_FL "ESP Wheel pulse counts";
BA_ "RID" SG_ 127 WhlPlsCnt_FR "1086";
BA_ "GenSigTimeout_IC" SG_ 127 WhlPlsCnt_FR 210;
BA_ "GenSigTimeout_CBC" SG_ 127 WhlPlsCnt_FR 210;
BA_ "GenSigSNA" SG_ 127 WhlPlsCnt_FR "FFh";
BA_ "GenSigCycleTime" SG_ 127 WhlPlsCnt_FR 20;
BA_ "FlexKomSigStartValue" SG_ 127 WhlPlsCnt_FR "00000000h";
BA_ "FlexKomSigStartPos" SG_ 127 WhlPlsCnt_FR 7;
BA_ "FlexKomSigName" SG_ 127 WhlPlsCnt_FR "ESP_WHL_PULS";
BA_ "FlexKomSigLaenge" SG_ 127 WhlPlsCnt_FR 32;
BA_ "FlexKomSID" SG_ 127 WhlPlsCnt_FR 65;
BA_ "FlexKomIsMotorola" SG_ 127 WhlPlsCnt_FR 1;
BA_ "FlexKomComment" SG_ 127 WhlPlsCnt_FR "ESP Wheel pulse counts";
BA_ "RID" SG_ 127 WhlPlsCnt_RL "1049";
BA_ "GenSigTimeout_IC" SG_ 127 WhlPlsCnt_RL 210;
BA_ "GenSigTimeout_CBC" SG_ 127 WhlPlsCnt_RL 210;
BA_ "GenSigSNA" SG_ 127 WhlPlsCnt_RL "FFh";
BA_ "GenSigCycleTime" SG_ 127 WhlPlsCnt_RL 20;
BA_ "FlexKomSigStartValue" SG_ 127 WhlPlsCnt_RL "00000000h";
BA_ "FlexKomSigStartPos" SG_ 127 WhlPlsCnt_RL 7;
BA_ "FlexKomSigName" SG_ 127 WhlPlsCnt_RL "ESP_WHL_PULS";
BA_ "FlexKomSigLaenge" SG_ 127 WhlPlsCnt_RL 32;
BA_ "FlexKomSID" SG_ 127 WhlPlsCnt_RL 65;
BA_ "FlexKomIsMotorola" SG_ 127 WhlPlsCnt_RL 1;
BA_ "FlexKomComment" SG_ 127 WhlPlsCnt_RL "ESP Wheel pulse counts";
BA_ "RID" SG_ 127 WhlPlsCnt_RR "1047";
BA_ "GenSigTimeout_IC" SG_ 127 WhlPlsCnt_RR 210;
BA_ "GenSigTimeout_CBC" SG_ 127 WhlPlsCnt_RR 210;
BA_ "GenSigSNA" SG_ 127 WhlPlsCnt_RR "FFh";
BA_ "GenSigCycleTime" SG_ 127 WhlPlsCnt_RR 20;
BA_ "FlexKomSigStartValue" SG_ 127 WhlPlsCnt_RR "00000000h";
BA_ "FlexKomSigStartPos" SG_ 127 WhlPlsCnt_RR 7;
BA_ "FlexKomSigName" SG_ 127 WhlPlsCnt_RR "ESP_WHL_PULS";
BA_ "FlexKomSigLaenge" SG_ 127 WhlPlsCnt_RR 32;
BA_ "FlexKomSID" SG_ 127 WhlPlsCnt_RR 65;
BA_ "FlexKomIsMotorola" SG_ 127 WhlPlsCnt_RR 1;
BA_ "FlexKomComment" SG_ 127 WhlPlsCnt_RR "ESP Wheel pulse counts";
BA_ "GenSigTimeout_ORC" SG_ 139 WhlDir_FL_Stat 70;
BA_ "GenSigStartValue" SG_ 139 WhlDir_FL_Stat 3;
BA_ "GenSigSNA" SG_ 139 WhlDir_FL_Stat "3h";
BA_ "GenSigCycleTime" SG_ 139 WhlDir_FL_Stat 20;
BA_ "FlexKomSigStartValue" SG_ 139 WhlDir_FL_Stat "FFFFFFFFFFFFFFFFh";
BA_ "FlexKomSigStartPos" SG_ 139 WhlDir_FL_Stat 7;
BA_ "FlexKomSigName" SG_ 139 WhlDir_FL_Stat "WHEEL_SPEED";
BA_ "FlexKomSigLaenge" SG_ 139 WhlDir_FL_Stat 64;
BA_ "FlexKomSID" SG_ 139 WhlDir_FL_Stat 64;
BA_ "FlexKomIsMotorola" SG_ 139 WhlDir_FL_Stat 1;
BA_ "FlexKomComment" SG_ 139 WhlDir_FL_Stat "ESP Wheel Speed";
BA_ "GenSigTimeout_ORC" SG_ 139 WhlDir_FR_Stat 70;
BA_ "GenSigStartValue" SG_ 139 WhlDir_FR_Stat 3;
BA_ "GenSigSNA" SG_ 139 WhlDir_FR_Stat "3h";
BA_ "GenSigCycleTime" SG_ 139 WhlDir_FR_Stat 20;
BA_ "FlexKomSigStartValue" SG_ 139 WhlDir_FR_Stat "FFFFFFFFFFFFFFFFh";
BA_ "FlexKomSigStartPos" SG_ 139 WhlDir_FR_Stat 7;
BA_ "FlexKomSigName" SG_ 139 WhlDir_FR_Stat "WHEEL_SPEED";
BA_ "FlexKomSigLaenge" SG_ 139 WhlDir_FR_Stat 64;
BA_ "FlexKomSID" SG_ 139 WhlDir_FR_Stat 64;
BA_ "FlexKomIsMotorola" SG_ 139 WhlDir_FR_Stat 1;
BA_ "FlexKomComment" SG_ 139 WhlDir_FR_Stat "ESP Wheel Speed";
BA_ "GenSigTimeout_ORC" SG_ 139 WhlDir_RL_Stat 70;
BA_ "GenSigStartValue" SG_ 139 WhlDir_RL_Stat 3;
BA_ "GenSigSNA" SG_ 139 WhlDir_RL_Stat "3h";
BA_ "GenSigCycleTime" SG_ 139 WhlDir_RL_Stat 20;
BA_ "FlexKomSigStartValue" SG_ 139 WhlDir_RL_Stat "FFFFFFFFFFFFFFFFh";
BA_ "FlexKomSigStartPos" SG_ 139 WhlDir_RL_Stat 7;
BA_ "FlexKomSigName" SG_ 139 WhlDir_RL_Stat "WHEEL_SPEED";
BA_ "FlexKomSigLaenge" SG_ 139 WhlDir_RL_Stat 64;
BA_ "FlexKomSID" SG_ 139 WhlDir_RL_Stat 64;
BA_ "FlexKomIsMotorola" SG_ 139 WhlDir_RL_Stat 1;
BA_ "FlexKomComment" SG_ 139 WhlDir_RL_Stat "ESP Wheel Speed";
BA_ "GenSigTimeout_ORC" SG_ 139 WhlDir_RR_Stat 70;
BA_ "GenSigStartValue" SG_ 139 WhlDir_RR_Stat 3;
BA_ "GenSigSNA" SG_ 139 WhlDir_RR_Stat "3h";
BA_ "GenSigCycleTime" SG_ 139 WhlDir_RR_Stat 20;
BA_ "FlexKomSigStartValue" SG_ 139 WhlDir_RR_Stat "FFFFFFFFFFFFFFFFh";
BA_ "FlexKomSigStartPos" SG_ 139 WhlDir_RR_Stat 7;
BA_ "FlexKomSigName" SG_ 139 WhlDir_RR_Stat "WHEEL_SPEED";
BA_ "FlexKomSigLaenge" SG_ 139 WhlDir_RR_Stat 64;
BA_ "FlexKomSID" SG_ 139 WhlDir_RR_Stat 64;
BA_ "FlexKomIsMotorola" SG_ 139 WhlDir_RR_Stat 1;
BA_ "FlexKomComment" SG_ 139 WhlDir_RR_Stat "ESP Wheel Speed";
BA_ "GenSigTimeout_ORC" SG_ 139 WhlRPM_FL 70;
BA_ "GenSigTimeout_ESL" SG_ 139 WhlRPM_FL 210;
BA_ "GenSigTimeout_DTCM" SG_ 139 WhlRPM_FL 210;
BA_ "GenSigStartValue" SG_ 139 WhlRPM_FL 16383;
BA_ "GenSigSNA" SG_ 139 WhlRPM_FL "3FFFh";
BA_ "GenSigCycleTime" SG_ 139 WhlRPM_FL 20;
BA_ "FlexKomSigStartValue" SG_ 139 WhlRPM_FL "FFFFFFFFFFFFFFFFh";
BA_ "FlexKomSigStartPos" SG_ 139 WhlRPM_FL 7;
BA_ "FlexKomSigName" SG_ 139 WhlRPM_FL "WHEEL_SPEED";
BA_ "FlexKomSigLaenge" SG_ 139 WhlRPM_FL 64;
BA_ "FlexKomSID" SG_ 139 WhlRPM_FL 64;
BA_ "FlexKomIsMotorola" SG_ 139 WhlRPM_FL 1;
BA_ "FlexKomComment" SG_ 139 WhlRPM_FL "ESP Wheel Speed";
BA_ "GenSigTimeout_ORC" SG_ 139 WhlRPM_FR 70;
BA_ "GenSigTimeout_ESL" SG_ 139 WhlRPM_FR 210;
BA_ "GenSigTimeout_DTCM" SG_ 139 WhlRPM_FR 210;
BA_ "GenSigStartValue" SG_ 139 WhlRPM_FR 16383;
BA_ "GenSigSNA" SG_ 139 WhlRPM_FR "3FFFh";
BA_ "GenSigCycleTime" SG_ 139 WhlRPM_FR 20;
BA_ "FlexKomSigStartValue" SG_ 139 WhlRPM_FR "FFFFFFFFFFFFFFFFh";
BA_ "FlexKomSigStartPos" SG_ 139 WhlRPM_FR 7;
BA_ "FlexKomSigName" SG_ 139 WhlRPM_FR "WHEEL_SPEED";
BA_ "FlexKomSigLaenge" SG_ 139 WhlRPM_FR 64;
BA_ "FlexKomSID" SG_ 139 WhlRPM_FR 64;
BA_ "FlexKomIsMotorola" SG_ 139 WhlRPM_FR 1;
BA_ "FlexKomComment" SG_ 139 WhlRPM_FR "ESP Wheel Speed";
BA_ "GenSigTimeout_TCM" SG_ 139 WhlRPM_RL 210;
BA_ "GenSigTimeout_ORC" SG_ 139 WhlRPM_RL 70;
BA_ "GenSigTimeout_ESL" SG_ 139 WhlRPM_RL 210;
BA_ "GenSigTimeout_DTCM" SG_ 139 WhlRPM_RL 210;
BA_ "GenSigTimeout_CBC" SG_ 139 WhlRPM_RL 110;
BA_ "GenSigStartValue" SG_ 139 WhlRPM_RL 16383;
BA_ "GenSigSNA" SG_ 139 WhlRPM_RL "3FFFh";
BA_ "GenSigCycleTime" SG_ 139 WhlRPM_RL 20;
BA_ "FlexKomSigStartValue" SG_ 139 WhlRPM_RL "FFFFFFFFFFFFFFFFh";
BA_ "FlexKomSigStartPos" SG_ 139 WhlRPM_RL 7;
BA_ "FlexKomSigName" SG_ 139 WhlRPM_RL "WHEEL_SPEED";
BA_ "FlexKomSigLaenge" SG_ 139 WhlRPM_RL 64;
BA_ "FlexKomSID" SG_ 139 WhlRPM_RL 64;
BA_ "FlexKomIsMotorola" SG_ 139 WhlRPM_RL 1;
BA_ "FlexKomComment" SG_ 139 WhlRPM_RL "ESP Wheel Speed";
BA_ "GenSigTimeout_TCM" SG_ 139 WhlRPM_RR 210;
BA_ "GenSigTimeout_ORC" SG_ 139 WhlRPM_RR 70;
BA_ "GenSigTimeout_ESL" SG_ 139 WhlRPM_RR 210;
BA_ "GenSigTimeout_DTCM" SG_ 139 WhlRPM_RR 210;
BA_ "GenSigTimeout_CBC" SG_ 139 WhlRPM_RR 110;
BA_ "GenSigStartValue" SG_ 139 WhlRPM_RR 16383;
BA_ "GenSigSNA" SG_ 139 WhlRPM_RR "3FFFh";
BA_ "GenSigCycleTime" SG_ 139 WhlRPM_RR 20;
BA_ "FlexKomSigStartValue" SG_ 139 WhlRPM_RR "FFFFFFFFFFFFFFFFh";
BA_ "FlexKomSigStartPos" SG_ 139 WhlRPM_RR 7;
BA_ "FlexKomSigName" SG_ 139 WhlRPM_RR "WHEEL_SPEED";
BA_ "FlexKomSigLaenge" SG_ 139 WhlRPM_RR 64;
BA_ "FlexKomSID" SG_ 139 WhlRPM_RR 64;
BA_ "FlexKomIsMotorola" SG_ 139 WhlRPM_RR 1;
BA_ "FlexKomComment" SG_ 139 WhlRPM_RR "ESP Wheel Speed";
BA_ "GenSigTimeout_ESM" SG_ 121 BrkTrq 210;
BA_ "GenSigTimeout_CBC" SG_ 121 BrkTrq 210;
BA_ "GenSigStartValue" SG_ 121 BrkTrq 4095;
BA_ "GenSigSNA" SG_ 121 BrkTrq "FFFh";
BA_ "GenSigCycleTime" SG_ 121 BrkTrq 20;
BA_ "FlexKomSigStartValue" SG_ 121 BrkTrq "0FFF0FFFFFFF00FFh";
BA_ "FlexKomSigStartPos" SG_ 121 BrkTrq 7;
BA_ "FlexKomSigName" SG_ 121 BrkTrq "VEH_SPEED_PKT";
BA_ "FlexKomSigLaenge" SG_ 121 BrkTrq 64;
BA_ "FlexKomSID" SG_ 121 BrkTrq 11;
BA_ "FlexKomIsMotorola" SG_ 121 BrkTrq 1;
BA_ "FlexKomComment" SG_ 121 BrkTrq "Vehicle Speed Packet";
BA_ "GenSigTimeout_ESM" SG_ 121 BrkTrq_D 210;
BA_ "GenSigTimeout_DTCM" SG_ 121 BrkTrq_D 210;
BA_ "GenSigStartValue" SG_ 121 BrkTrq_D 4095;
BA_ "GenSigSNA" SG_ 121 BrkTrq_D "FFFh";
BA_ "GenSigCycleTime" SG_ 121 BrkTrq_D 20;
BA_ "FlexKomSigStartValue" SG_ 121 BrkTrq_D "0FFF0FFFFFFF00FFh";
BA_ "FlexKomSigStartPos" SG_ 121 BrkTrq_D 7;
BA_ "FlexKomSigName" SG_ 121 BrkTrq_D "VEH_SPEED_PKT";
BA_ "FlexKomSigLaenge" SG_ 121 BrkTrq_D 64;
BA_ "FlexKomSID" SG_ 121 BrkTrq_D 11;
BA_ "FlexKomIsMotorola" SG_ 121 BrkTrq_D 1;
BA_ "FlexKomComment" SG_ 121 BrkTrq_D "Vehicle Speed Packet";
BA_ "GenSigTimeout_TPM" SG_ 121 CRC_VEH_SPEED 1010;
BA_ "GenSigTimeout_ORC" SG_ 121 CRC_VEH_SPEED 70;
BA_ "GenSigTimeout_IC" SG_ 121 CRC_VEH_SPEED 210;
BA_ "GenSigTimeout_ESM" SG_ 121 CRC_VEH_SPEED 210;
BA_ "GenSigTimeout_ESL" SG_ 121 CRC_VEH_SPEED 110;
BA_ "GenSigTimeout_CBC" SG_ 121 CRC_VEH_SPEED 110;
BA_ "GenSigStartValue" SG_ 121 CRC_VEH_SPEED 255;
BA_ "GenSigSNA" SG_ 121 CRC_VEH_SPEED "FFh";
BA_ "GenSigCycleTime" SG_ 121 CRC_VEH_SPEED 20;
BA_ "FlexKomSigStartValue" SG_ 121 CRC_VEH_SPEED "0FFF0FFFFFFF00FFh";
BA_ "FlexKomSigStartPos" SG_ 121 CRC_VEH_SPEED 7;
BA_ "FlexKomSigName" SG_ 121 CRC_VEH_SPEED "VEH_SPEED_PKT";
BA_ "FlexKomSigLaenge" SG_ 121 CRC_VEH_SPEED 64;
BA_ "FlexKomSID" SG_ 121 CRC_VEH_SPEED 11;
BA_ "FlexKomIsMotorola" SG_ 121 CRC_VEH_SPEED 1;
BA_ "FlexKomComment" SG_ 121 CRC_VEH_SPEED "Vehicle Speed Packet";
BA_ "GenSigTimeout_TPM" SG_ 121 MC_VEH_SPEED 1010;
BA_ "GenSigTimeout_ORC" SG_ 121 MC_VEH_SPEED 70;
BA_ "GenSigTimeout_IC" SG_ 121 MC_VEH_SPEED 210;
BA_ "GenSigTimeout_ESM" SG_ 121 MC_VEH_SPEED 210;
BA_ "GenSigTimeout_ESL" SG_ 121 MC_VEH_SPEED 110;
BA_ "GenSigTimeout_CBC" SG_ 121 MC_VEH_SPEED 110;
BA_ "GenSigSNA" SG_ 121 MC_VEH_SPEED "0h";
BA_ "GenSigCycleTime" SG_ 121 MC_VEH_SPEED 20;
BA_ "FlexKomSigStartValue" SG_ 121 MC_VEH_SPEED "0FFF0FFFFFFF00FFh";
BA_ "FlexKomSigStartPos" SG_ 121 MC_VEH_SPEED 7;
BA_ "FlexKomSigName" SG_ 121 MC_VEH_SPEED "VEH_SPEED_PKT";
BA_ "FlexKomSigLaenge" SG_ 121 MC_VEH_SPEED 64;
BA_ "FlexKomSID" SG_ 121 MC_VEH_SPEED 11;
BA_ "FlexKomIsMotorola" SG_ 121 MC_VEH_SPEED 1;
BA_ "FlexKomComment" SG_ 121 MC_VEH_SPEED "Vehicle Speed Packet";
BA_ "RID" SG_ 121 VEH_SPEED "2861 2862 2863";
BA_ "GenSigTimeout_TPM" SG_ 121 VEH_SPEED 1010;
BA_ "GenSigTimeout_TCM" SG_ 121 VEH_SPEED 210;
BA_ "GenSigTimeout_RF_HUB" SG_ 121 VEH_SPEED 210;
BA_ "GenSigTimeout_ORC" SG_ 121 VEH_SPEED 70;
BA_ "GenSigTimeout_IC" SG_ 121 VEH_SPEED 210;
BA_ "GenSigTimeout_ESM" SG_ 121 VEH_SPEED 210;
BA_ "GenSigTimeout_ESL" SG_ 121 VEH_SPEED 110;
BA_ "GenSigTimeout_EHPS" SG_ 121 VEH_SPEED 210;
BA_ "GenSigTimeout_DTCM" SG_ 121 VEH_SPEED 210;
BA_ "GenSigTimeout_CBC" SG_ 121 VEH_SPEED 110;
BA_ "GenSigStartValue" SG_ 121 VEH_SPEED 65535;
BA_ "GenSigSNA" SG_ 121 VEH_SPEED "FFFFh";
BA_ "GenSigCycleTime" SG_ 121 VEH_SPEED 20;
BA_ "FlexKomSigStartValue" SG_ 121 VEH_SPEED "0FFF0FFFFFFF00FFh";
BA_ "FlexKomSigStartPos" SG_ 121 VEH_SPEED 7;
BA_ "FlexKomSigName" SG_ 121 VEH_SPEED "VEH_SPEED_PKT";
BA_ "FlexKomSigLaenge" SG_ 121 VEH_SPEED 64;
BA_ "FlexKomSID" SG_ 121 VEH_SPEED 11;
BA_ "FlexKomIsMotorola" SG_ 121 VEH_SPEED 1;
BA_ "FlexKomComment" SG_ 121 VEH_SPEED "Vehicle Speed Packet";
BA_ "GenSigSNA" SG_ 121 VehSpSts "0h";
BA_ "GenSigCycleTime" SG_ 121 VehSpSts 20;
BA_ "FlexKomSigStartValue" SG_ 121 VehSpSts "0FFF0FFFFFFF00FFh";
BA_ "FlexKomSigStartPos" SG_ 121 VehSpSts 7;
BA_ "FlexKomSigName" SG_ 121 VehSpSts "VEH_SPEED_PKT";
BA_ "FlexKomSigLaenge" SG_ 121 VehSpSts 64;
BA_ "FlexKomSID" SG_ 121 VehSpSts 11;
BA_ "FlexKomIsMotorola" SG_ 121 VehSpSts 1;
BA_ "FlexKomComment" SG_ 121 VehSpSts "Vehicle Speed Packet";
BA_ "GenSigStartValue" SG_ 117 CRC_10Eh 255;
BA_ "GenSigSNA" SG_ 117 CRC_10Eh "FFh";
BA_ "GenSigCycleTime" SG_ 117 CRC_10Eh 20;
BA_ "FlexKomSigStartValue" SG_ 117 CRC_10Eh "00000000000000FFh";
BA_ "FlexKomSigStartPos" SG_ 117 CRC_10Eh 7;
BA_ "FlexKomSigName" SG_ 117 CRC_10Eh "ESP_A9_Pkt";
BA_ "FlexKomSigLaenge" SG_ 117 CRC_10Eh 64;
BA_ "FlexKomSID" SG_ 117 CRC_10Eh 2519;
BA_ "FlexKomIsMotorola" SG_ 117 CRC_10Eh 1;
BA_ "FlexKomComment" SG_ 117 CRC_10Eh "ESP_A9_Pkt";
BA_ "GenSigSNA" SG_ 117 MC_10Eh "0h";
BA_ "GenSigCycleTime" SG_ 117 MC_10Eh 20;
BA_ "FlexKomSigStartValue" SG_ 117 MC_10Eh "00000000000000FFh";
BA_ "FlexKomSigStartPos" SG_ 117 MC_10Eh 7;
BA_ "FlexKomSigName" SG_ 117 MC_10Eh "ESP_A9_Pkt";
BA_ "FlexKomSigLaenge" SG_ 117 MC_10Eh 64;
BA_ "FlexKomSID" SG_ 117 MC_10Eh 2519;
BA_ "FlexKomIsMotorola" SG_ 117 MC_10Eh 1;
BA_ "FlexKomComment" SG_ 117 MC_10Eh "ESP_A9_Pkt";
BA_ "GenSigSNA" SG_ 117 WhlTrqAct_Rq_AS "0h";
BA_ "GenSigCycleTime" SG_ 117 WhlTrqAct_Rq_AS 20;
BA_ "FlexKomSigStartValue" SG_ 117 WhlTrqAct_Rq_AS "00000000000000FFh";
BA_ "FlexKomSigStartPos" SG_ 117 WhlTrqAct_Rq_AS 7;
BA_ "FlexKomSigName" SG_ 117 WhlTrqAct_Rq_AS "ESP_A9_Pkt";
BA_ "FlexKomSigLaenge" SG_ 117 WhlTrqAct_Rq_AS 64;
BA_ "FlexKomSID" SG_ 117 WhlTrqAct_Rq_AS 2519;
BA_ "FlexKomIsMotorola" SG_ 117 WhlTrqAct_Rq_AS 1;
BA_ "FlexKomComment" SG_ 117 WhlTrqAct_Rq_AS "ESP_A9_Pkt";
BA_ "GenSigSNA" SG_ 117 WhlTrq_Rq_As_2 "FFFFh";
BA_ "GenSigCycleTime" SG_ 117 WhlTrq_Rq_As_2 20;
BA_ "FlexKomSigStartValue" SG_ 117 WhlTrq_Rq_As_2 "00000000000000FFh";
BA_ "FlexKomSigStartPos" SG_ 117 WhlTrq_Rq_As_2 7;
BA_ "FlexKomSigName" SG_ 117 WhlTrq_Rq_As_2 "ESP_A9_Pkt";
BA_ "FlexKomSigLaenge" SG_ 117 WhlTrq_Rq_As_2 64;
BA_ "FlexKomSID" SG_ 117 WhlTrq_Rq_As_2 2519;
BA_ "FlexKomIsMotorola" SG_ 117 WhlTrq_Rq_As_2 1;
BA_ "FlexKomComment" SG_ 117 WhlTrq_Rq_As_2 "ESP_A9_Pkt";
BA_ "RID" SG_ 221 ABS_IndLmp_On_Rq "6548";
BA_ "GenSigTimeout_TBM" SG_ 221 ABS_IndLmp_On_Rq 525;
BA_ "GenSigTimeout_IC" SG_ 221 ABS_IndLmp_On_Rq 275;
BA_ "GenSigTimeout_ETM" SG_ 221 ABS_IndLmp_On_Rq 525;
BA_ "GenSigStartValue" SG_ 221 ABS_IndLmp_On_Rq 3;
BA_ "GenSigSNA" SG_ 221 ABS_IndLmp_On_Rq "3h";
BA_ "GenSigCycleTime" SG_ 221 ABS_IndLmp_On_Rq 50;
BA_ "FlexKomSigStartValue" SG_ 221 ABS_IndLmp_On_Rq "003Fh";
BA_ "FlexKomSigStartPos" SG_ 221 ABS_IndLmp_On_Rq 55;
BA_ "FlexKomSigName" SG_ 221 ABS_IndLmp_On_Rq "ESP_HMI";
BA_ "FlexKomSigLaenge" SG_ 221 ABS_IndLmp_On_Rq 16;
BA_ "FlexKomSID" SG_ 221 ABS_IndLmp_On_Rq 397;
BA_ "FlexKomIsMotorola" SG_ 221 ABS_IndLmp_On_Rq 1;
BA_ "FlexKomComment" SG_ 221 ABS_IndLmp_On_Rq "ESP Customer Indicators";
BA_ "RID" SG_ 221 BrkIndLmp_On_Rq_ESC "6547";
BA_ "GenSigTimeout_TBM" SG_ 221 BrkIndLmp_On_Rq_ESC 525;
BA_ "GenSigTimeout_IC" SG_ 221 BrkIndLmp_On_Rq_ESC 275;
BA_ "GenSigTimeout_ETM" SG_ 221 BrkIndLmp_On_Rq_ESC 525;
BA_ "GenSigStartValue" SG_ 221 BrkIndLmp_On_Rq_ESC 3;
BA_ "GenSigSNA" SG_ 221 BrkIndLmp_On_Rq_ESC "3h";
BA_ "GenSigCycleTime" SG_ 221 BrkIndLmp_On_Rq_ESC 50;
BA_ "FlexKomSigStartValue" SG_ 221 BrkIndLmp_On_Rq_ESC "003Fh";
BA_ "FlexKomSigStartPos" SG_ 221 BrkIndLmp_On_Rq_ESC 55;
BA_ "FlexKomSigName" SG_ 221 BrkIndLmp_On_Rq_ESC "ESP_HMI";
BA_ "FlexKomSigLaenge" SG_ 221 BrkIndLmp_On_Rq_ESC 16;
BA_ "FlexKomSID" SG_ 221 BrkIndLmp_On_Rq_ESC 397;
BA_ "FlexKomIsMotorola" SG_ 221 BrkIndLmp_On_Rq_ESC 1;
BA_ "FlexKomComment" SG_ 221 BrkIndLmp_On_Rq_ESC "ESP Customer Indicators";
BA_ "RID" SG_ 221 ESC_CtrlLmp_Info "6550";
BA_ "GenSigTimeout_ORC" SG_ 221 ESC_CtrlLmp_Info 175;
BA_ "GenSigTimeout_IC" SG_ 221 ESC_CtrlLmp_Info 275;
BA_ "GenSigTimeout_ETM" SG_ 221 ESC_CtrlLmp_Info 525;
BA_ "GenSigStartValue" SG_ 221 ESC_CtrlLmp_Info 3;
BA_ "GenSigSNA" SG_ 221 ESC_CtrlLmp_Info "3h";
BA_ "GenSigCycleTime" SG_ 221 ESC_CtrlLmp_Info 50;
BA_ "FlexKomSigStartValue" SG_ 221 ESC_CtrlLmp_Info "003Fh";
BA_ "FlexKomSigStartPos" SG_ 221 ESC_CtrlLmp_Info 55;
BA_ "FlexKomSigName" SG_ 221 ESC_CtrlLmp_Info "ESP_HMI";
BA_ "FlexKomSigLaenge" SG_ 221 ESC_CtrlLmp_Info 16;
BA_ "FlexKomSID" SG_ 221 ESC_CtrlLmp_Info 397;
BA_ "FlexKomIsMotorola" SG_ 221 ESC_CtrlLmp_Info 1;
BA_ "FlexKomComment" SG_ 221 ESC_CtrlLmp_Info "ESP Customer Indicators";
BA_ "RID" SG_ 221 ESP_DSBL "1649 1674";
BA_ "GenSigTimeout_ORC" SG_ 221 ESP_DSBL 175;
BA_ "GenSigTimeout_IC" SG_ 221 ESP_DSBL 525;
BA_ "GenSigTimeout_ETM" SG_ 221 ESP_DSBL 525;
BA_ "GenSigSNA" SG_ 221 ESP_DSBL "0h";
BA_ "GenSigCycleTime" SG_ 221 ESP_DSBL 50;
BA_ "FlexKomSigStartValue" SG_ 221 ESP_DSBL "003Fh";
BA_ "FlexKomSigStartPos" SG_ 221 ESP_DSBL 55;
BA_ "FlexKomSigName" SG_ 221 ESP_DSBL "ESP_HMI";
BA_ "FlexKomSigLaenge" SG_ 221 ESP_DSBL 16;
BA_ "FlexKomSID" SG_ 221 ESP_DSBL 397;
BA_ "FlexKomIsMotorola" SG_ 221 ESP_DSBL 1;
BA_ "FlexKomComment" SG_ 221 ESP_DSBL "ESP Customer Indicators";
BA_ "RID" SG_ 221 ESP_Off_IndLmp_On_Rq "1988";
BA_ "GenSigTimeout_ORC" SG_ 221 ESP_Off_IndLmp_On_Rq 175;
BA_ "GenSigTimeout_IC" SG_ 221 ESP_Off_IndLmp_On_Rq 275;
BA_ "GenSigTimeout_ETM" SG_ 221 ESP_Off_IndLmp_On_Rq 525;
BA_ "GenSigSNA" SG_ 221 ESP_Off_IndLmp_On_Rq "0h";
BA_ "GenSigCycleTime" SG_ 221 ESP_Off_IndLmp_On_Rq 50;
BA_ "FlexKomSigStartValue" SG_ 221 ESP_Off_IndLmp_On_Rq "003Fh";
BA_ "FlexKomSigStartPos" SG_ 221 ESP_Off_IndLmp_On_Rq 55;
BA_ "FlexKomSigName" SG_ 221 ESP_Off_IndLmp_On_Rq "ESP_HMI";
BA_ "FlexKomSigLaenge" SG_ 221 ESP_Off_IndLmp_On_Rq 16;
BA_ "FlexKomSID" SG_ 221 ESP_Off_IndLmp_On_Rq 397;
BA_ "FlexKomIsMotorola" SG_ 221 ESP_Off_IndLmp_On_Rq 1;
BA_ "FlexKomComment" SG_ 221 ESP_Off_IndLmp_On_Rq "ESP Customer Indicators";
BA_ "RID" SG_ 221 HILL_DES_STAT "1141 1293 1929";
BA_ "GenSigTimeout_IC" SG_ 221 HILL_DES_STAT 525;
BA_ "GenSigSNA" SG_ 221 HILL_DES_STAT "0h";
BA_ "GenSigCycleTime" SG_ 221 HILL_DES_STAT 50;
BA_ "FlexKomSigStartValue" SG_ 221 HILL_DES_STAT "003Fh";
BA_ "FlexKomSigStartPos" SG_ 221 HILL_DES_STAT 55;
BA_ "FlexKomSigName" SG_ 221 HILL_DES_STAT "ESP_HMI";
BA_ "FlexKomSigLaenge" SG_ 221 HILL_DES_STAT 16;
BA_ "FlexKomSID" SG_ 221 HILL_DES_STAT 397;
BA_ "FlexKomIsMotorola" SG_ 221 HILL_DES_STAT 1;
BA_ "FlexKomComment" SG_ 221 HILL_DES_STAT "ESP Customer Indicators";
BA_ "RID" SG_ 221 HSA_EN "1063";
BA_ "GenSigTimeout_IC" SG_ 221 HSA_EN 525;
BA_ "GenSigSNA" SG_ 221 HSA_EN "0h";
BA_ "GenSigCycleTime" SG_ 221 HSA_EN 50;
BA_ "FlexKomSigStartValue" SG_ 221 HSA_EN "00h";
BA_ "FlexKomSigStartPos" SG_ 221 HSA_EN 47;
BA_ "FlexKomSigName" SG_ 221 HSA_EN "EBC_Feature_Status";
BA_ "FlexKomSigLaenge" SG_ 221 HSA_EN 8;
BA_ "FlexKomSID" SG_ 221 HSA_EN 396;
BA_ "FlexKomIsMotorola" SG_ 221 HSA_EN 1;
BA_ "FlexKomComment" SG_ 221 HSA_EN "ESP feature present and enabled";
BA_ "RID" SG_ 221 LT_DIST "1233";
BA_ "GenSigTimeout_PTS" SG_ 221 LT_DIST 525;
BA_ "GenSigTimeout_IC" SG_ 221 LT_DIST 525;
BA_ "GenSigTimeout_CBC" SG_ 221 LT_DIST 525;
BA_ "GenSigStartValue" SG_ 221 LT_DIST 65535;
BA_ "GenSigSNA" SG_ 221 LT_DIST "FFFFh";
BA_ "GenSigCycleTime" SG_ 221 LT_DIST 50;
BA_ "FlexKomSigStartValue" SG_ 221 LT_DIST "FFFFFFFFh";
BA_ "FlexKomSigStartPos" SG_ 221 LT_DIST 7;
BA_ "FlexKomSigName" SG_ 221 LT_DIST "ESP_DIST";
BA_ "FlexKomSigLaenge" SG_ 221 LT_DIST 32;
BA_ "FlexKomSID" SG_ 221 LT_DIST 395;
BA_ "FlexKomIsMotorola" SG_ 221 LT_DIST 1;
BA_ "FlexKomComment" SG_ 221 LT_DIST "Distance traveled by wheels";
BA_ "RID" SG_ 221 RT_DIST "1113";
BA_ "GenSigTimeout_PTS" SG_ 221 RT_DIST 525;
BA_ "GenSigTimeout_IC" SG_ 221 RT_DIST 525;
BA_ "GenSigTimeout_CBC" SG_ 221 RT_DIST 525;
BA_ "GenSigStartValue" SG_ 221 RT_DIST 65535;
BA_ "GenSigSNA" SG_ 221 RT_DIST "FFFFh";
BA_ "GenSigCycleTime" SG_ 221 RT_DIST 50;
BA_ "FlexKomSigStartValue" SG_ 221 RT_DIST "FFFFFFFFh";
BA_ "FlexKomSigStartPos" SG_ 221 RT_DIST 7;
BA_ "FlexKomSigName" SG_ 221 RT_DIST "ESP_DIST";
BA_ "FlexKomSigLaenge" SG_ 221 RT_DIST 32;
BA_ "FlexKomSID" SG_ 221 RT_DIST 395;
BA_ "FlexKomIsMotorola" SG_ 221 RT_DIST 1;
BA_ "FlexKomComment" SG_ 221 RT_DIST "Distance traveled by wheels";
BA_ "RID" SG_ 221 SelSpdLmp "1879 2059 5071";
BA_ "GenSigTimeout_IC" SG_ 221 SelSpdLmp 525;
BA_ "GenSigTimeout_CBC" SG_ 221 SelSpdLmp 525;
BA_ "GenSigSNA" SG_ 221 SelSpdLmp "3h";
BA_ "GenSigCycleTime" SG_ 221 SelSpdLmp 50;
BA_ "FlexKomSigStartValue" SG_ 221 SelSpdLmp "003Fh";
BA_ "FlexKomSigStartPos" SG_ 221 SelSpdLmp 55;
BA_ "FlexKomSigName" SG_ 221 SelSpdLmp "ESP_HMI";
BA_ "FlexKomSigLaenge" SG_ 221 SelSpdLmp 16;
BA_ "FlexKomSID" SG_ 221 SelSpdLmp 397;
BA_ "FlexKomIsMotorola" SG_ 221 SelSpdLmp 1;
BA_ "FlexKomComment" SG_ 221 SelSpdLmp "ESP Customer Indicators";
BA_ "GenSigTimeout_ORC" SG_ 221 YRS_DataRq 175;
BA_ "GenSigSNA" SG_ 221 YRS_DataRq "0h";
BA_ "GenSigCycleTime" SG_ 221 YRS_DataRq 50;
BA_ "FlexKomSigStartValue" SG_ 221 YRS_DataRq "00h";
BA_ "FlexKomSigStartPos" SG_ 221 YRS_DataRq 32;
BA_ "FlexKomSigName" SG_ 221 YRS_DataRq "YRS_DataRq";
BA_ "FlexKomSigLaenge" SG_ 221 YRS_DataRq 1;
BA_ "FlexKomSID" SG_ 221 YRS_DataRq 1589;
BA_ "FlexKomIsMotorola" SG_ 221 YRS_DataRq 1;
BA_ "FlexKomComment" SG_ 221 YRS_DataRq "Request from ESC for YRS information";
BA_ "GenSigSNA" SG_ 327 ESCSysEmsMlfAtv "0h";
BA_ "GenSigCycleTime" SG_ 327 ESCSysEmsMlfAtv 100;
BA_ "FlexKomSigStartValue" SG_ 327 ESCSysEmsMlfAtv "00h";
BA_ "FlexKomSigStartPos" SG_ 327 ESCSysEmsMlfAtv 18;
BA_ "FlexKomSigName" SG_ 327 ESCSysEmsMlfAtv "ESCSysEmsMlfAtv";
BA_ "FlexKomSigLaenge" SG_ 327 ESCSysEmsMlfAtv 1;
BA_ "FlexKomSID" SG_ 327 ESCSysEmsMlfAtv 2376;
BA_ "FlexKomIsMotorola" SG_ 327 ESCSysEmsMlfAtv 1;
BA_ "FlexKomComment" SG_ 327 ESCSysEmsMlfAtv "ESC emissions related malfunction active";
BA_ "GenSigSNA" SG_ 327 MIL_OnRq_ESC "0h";
BA_ "GenSigCycleTime" SG_ 327 MIL_OnRq_ESC 100;
BA_ "FlexKomSigStartValue" SG_ 327 MIL_OnRq_ESC "00h";
BA_ "FlexKomSigStartPos" SG_ 327 MIL_OnRq_ESC 2;
BA_ "FlexKomSigName" SG_ 327 MIL_OnRq_ESC "MIL_OnRq_ESC";
BA_ "FlexKomSigLaenge" SG_ 327 MIL_OnRq_ESC 1;
BA_ "FlexKomSID" SG_ 327 MIL_OnRq_ESC 2375;
BA_ "FlexKomIsMotorola" SG_ 327 MIL_OnRq_ESC 1;
BA_ "FlexKomComment" SG_ 327 MIL_OnRq_ESC "MIL on request from the ESC";
BA_ "GenSigSNA" SG_ 738 CODE_CLR_ESC "0h";
BA_ "GenSigCycleTime" SG_ 738 CODE_CLR_ESC 100;
BA_ "FlexKomSigStartValue" SG_ 738 CODE_CLR_ESC "00000000000000FFh";
BA_ "FlexKomSigStartPos" SG_ 738 CODE_CLR_ESC 7;
BA_ "FlexKomSigName" SG_ 738 CODE_CLR_ESC "ESP_B4_PKT";
BA_ "FlexKomSigLaenge" SG_ 738 CODE_CLR_ESC 64;
BA_ "FlexKomSID" SG_ 738 CODE_CLR_ESC 2689;
BA_ "FlexKomIsMotorola" SG_ 738 CODE_CLR_ESC 1;
BA_ "FlexKomComment" SG_ 738 CODE_CLR_ESC "ESP_B4 Packet";
BA_ "GenSigSNA" SG_ 738 REPRGD_PFC_CLR_ESC "0h";
BA_ "GenSigCycleTime" SG_ 738 REPRGD_PFC_CLR_ESC 100;
BA_ "FlexKomSigStartValue" SG_ 738 REPRGD_PFC_CLR_ESC "00000000000000FFh";
BA_ "FlexKomSigStartPos" SG_ 738 REPRGD_PFC_CLR_ESC 7;
BA_ "FlexKomSigName" SG_ 738 REPRGD_PFC_CLR_ESC "ESP_B4_PKT";
BA_ "FlexKomSigLaenge" SG_ 738 REPRGD_PFC_CLR_ESC 64;
BA_ "FlexKomSID" SG_ 738 REPRGD_PFC_CLR_ESC 2689;
BA_ "FlexKomIsMotorola" SG_ 738 REPRGD_PFC_CLR_ESC 1;
BA_ "FlexKomComment" SG_ 738 REPRGD_PFC_CLR_ESC "ESP_B4 Packet";
BA_ "GenSigSNA" SG_ 840 FailSafeError "FFFFh";
BA_ "GenSigSendType" SG_ 840 FailSafeError 1;
BA_ "FlexKomSigStartValue" SG_ 840 FailSafeError "0000h";
BA_ "FlexKomSigStartPos" SG_ 840 FailSafeError 7;
BA_ "FlexKomSigName" SG_ 840 FailSafeError "FailSafeError";
BA_ "FlexKomSigLaenge" SG_ 840 FailSafeError 16;
BA_ "FlexKomSID" SG_ 840 FailSafeError 13;
BA_ "FlexKomIsMotorola" SG_ 840 FailSafeError 1;
BA_ "FlexKomComment" SG_ 840 FailSafeError "Fail safe error";
BA_ "GenSigSNA" SG_ 1016 EC_BU_CBC1A "0h";
BA_ "GenSigSendType" SG_ 1016 EC_BU_CBC1A 1;
BA_ "FlexKomSigStartValue" SG_ 1016 EC_BU_CBC1A "00000000h";
BA_ "FlexKomSigStartPos" SG_ 1016 EC_BU_CBC1A 7;
BA_ "FlexKomSigName" SG_ 1016 EC_BU_CBC1A "EC_BU_CBC1";
BA_ "FlexKomSigLaenge" SG_ 1016 EC_BU_CBC1A 32;
BA_ "FlexKomSID" SG_ 1016 EC_BU_CBC1A 907;
BA_ "FlexKomIsMotorola" SG_ 1016 EC_BU_CBC1A 1;
BA_ "FlexKomComment" SG_ 1016 EC_BU_CBC1A "Backup for CBC ecu configuration 1";
BA_ "GenSigSNA" SG_ 1016 EC_BU_CBC1B "0h";
BA_ "GenSigSendType" SG_ 1016 EC_BU_CBC1B 1;
BA_ "FlexKomSigStartValue" SG_ 1016 EC_BU_CBC1B "00000000h";
BA_ "FlexKomSigStartPos" SG_ 1016 EC_BU_CBC1B 7;
BA_ "FlexKomSigName" SG_ 1016 EC_BU_CBC1B "EC_BU_CBC1";
BA_ "FlexKomSigLaenge" SG_ 1016 EC_BU_CBC1B 32;
BA_ "FlexKomSID" SG_ 1016 EC_BU_CBC1B 907;
BA_ "FlexKomIsMotorola" SG_ 1016 EC_BU_CBC1B 1;
BA_ "FlexKomComment" SG_ 1016 EC_BU_CBC1B "Backup for CBC ecu configuration 1";
BA_ "GenSigSNA" SG_ 1016 EC_BU_CBC2 "0h";
BA_ "GenSigSendType" SG_ 1016 EC_BU_CBC2 1;
BA_ "FlexKomSigStartValue" SG_ 1016 EC_BU_CBC2 "00000000h";
BA_ "FlexKomSigStartPos" SG_ 1016 EC_BU_CBC2 39;
BA_ "FlexKomSigName" SG_ 1016 EC_BU_CBC2 "EC_BU_CBC2";
BA_ "FlexKomSigLaenge" SG_ 1016 EC_BU_CBC2 32;
BA_ "FlexKomSID" SG_ 1016 EC_BU_CBC2 908;
BA_ "FlexKomIsMotorola" SG_ 1016 EC_BU_CBC2 1;
BA_ "FlexKomComment" SG_ 1016 EC_BU_CBC2 "Backup for CBC ecu configuration 2";
BA_ "GenSigStartValue" SG_ 1016 EC_BU_ECUCfg1_Stat 3;
BA_ "GenSigSNA" SG_ 1016 EC_BU_ECUCfg1_Stat "3h";
BA_ "GenSigSendType" SG_ 1016 EC_BU_ECUCfg1_Stat 1;
BA_ "FlexKomSigStartValue" SG_ 1016 EC_BU_ECUCfg1_Stat "03h";
BA_ "FlexKomSigStartPos" SG_ 1016 EC_BU_ECUCfg1_Stat 1;
BA_ "FlexKomSigName" SG_ 1016 EC_BU_ECUCfg1_Stat "EC_BU_ECUCfg1_Stat";
BA_ "FlexKomSigLaenge" SG_ 1016 EC_BU_ECUCfg1_Stat 2;
BA_ "FlexKomSID" SG_ 1016 EC_BU_ECUCfg1_Stat 1064;
BA_ "FlexKomIsMotorola" SG_ 1016 EC_BU_ECUCfg1_Stat 1;
BA_ "FlexKomComment" SG_ 1016 EC_BU_ECUCfg1_Stat "Backup for ECU Configuration messages status 1";
BA_ "GenSigSNA" SG_ 989 EC_BU_Cluster3A "0h";
BA_ "GenSigSendType" SG_ 989 EC_BU_Cluster3A 1;
BA_ "FlexKomSigStartValue" SG_ 989 EC_BU_Cluster3A "00000000h";
BA_ "FlexKomSigStartPos" SG_ 989 EC_BU_Cluster3A 7;
BA_ "FlexKomSigName" SG_ 989 EC_BU_Cluster3A "EC_BU_Cluster3";
BA_ "FlexKomSigLaenge" SG_ 989 EC_BU_Cluster3A 32;
BA_ "FlexKomSID" SG_ 989 EC_BU_Cluster3A 1305;
BA_ "FlexKomIsMotorola" SG_ 989 EC_BU_Cluster3A 1;
BA_ "FlexKomComment" SG_ 989 EC_BU_Cluster3A "Backup for Instrument cluster ecu configuration 3";
BA_ "GenSigSNA" SG_ 989 EC_BU_Cluster3B "0h";
BA_ "GenSigSendType" SG_ 989 EC_BU_Cluster3B 1;
BA_ "FlexKomSigStartValue" SG_ 989 EC_BU_Cluster3B "00000000h";
BA_ "FlexKomSigStartPos" SG_ 989 EC_BU_Cluster3B 7;
BA_ "FlexKomSigName" SG_ 989 EC_BU_Cluster3B "EC_BU_Cluster3";
BA_ "FlexKomSigLaenge" SG_ 989 EC_BU_Cluster3B 32;
BA_ "FlexKomSID" SG_ 989 EC_BU_Cluster3B 1305;
BA_ "FlexKomIsMotorola" SG_ 989 EC_BU_Cluster3B 1;
BA_ "FlexKomComment" SG_ 989 EC_BU_Cluster3B "Backup for Instrument cluster ecu configuration 3";
BA_ "GenSigSNA" SG_ 989 EC_BU_Cluster4 "0h";
BA_ "GenSigSendType" SG_ 989 EC_BU_Cluster4 1;
BA_ "FlexKomSigStartValue" SG_ 989 EC_BU_Cluster4 "00000000h";
BA_ "FlexKomSigStartPos" SG_ 989 EC_BU_Cluster4 39;
BA_ "FlexKomSigName" SG_ 989 EC_BU_Cluster4 "EC_BU_Cluster4";
BA_ "FlexKomSigLaenge" SG_ 989 EC_BU_Cluster4 32;
BA_ "FlexKomSID" SG_ 989 EC_BU_Cluster4 1304;
BA_ "FlexKomIsMotorola" SG_ 989 EC_BU_Cluster4 1;
BA_ "FlexKomComment" SG_ 989 EC_BU_Cluster4 "Backup for Instrument cluster ecu configuration 4";
BA_ "GenSigStartValue" SG_ 989 EC_BU_ECUCfg10_Stat 3;
BA_ "GenSigSNA" SG_ 989 EC_BU_ECUCfg10_Stat "3h";
BA_ "GenSigSendType" SG_ 989 EC_BU_ECUCfg10_Stat 1;
BA_ "FlexKomSigStartValue" SG_ 989 EC_BU_ECUCfg10_Stat "03h";
BA_ "FlexKomSigStartPos" SG_ 989 EC_BU_ECUCfg10_Stat 1;
BA_ "FlexKomSigName" SG_ 989 EC_BU_ECUCfg10_Stat "EC_BU_ECUCfg10_Stat";
BA_ "FlexKomSigLaenge" SG_ 989 EC_BU_ECUCfg10_Stat 2;
BA_ "FlexKomSID" SG_ 989 EC_BU_ECUCfg10_Stat 1302;
BA_ "FlexKomIsMotorola" SG_ 989 EC_BU_ECUCfg10_Stat 1;
BA_ "FlexKomComment" SG_ 989 EC_BU_ECUCfg10_Stat "Backup for ECU Configuration messages status 10";
BA_ "GenSigSNA" SG_ 988 EC_BU_CBC10A "0h";
BA_ "GenSigSendType" SG_ 988 EC_BU_CBC10A 1;
BA_ "FlexKomSigStartValue" SG_ 988 EC_BU_CBC10A "00000000h";
BA_ "FlexKomSigStartPos" SG_ 988 EC_BU_CBC10A 7;
BA_ "FlexKomSigName" SG_ 988 EC_BU_CBC10A "EC_BU_CBC10";
BA_ "FlexKomSigLaenge" SG_ 988 EC_BU_CBC10A 32;
BA_ "FlexKomSID" SG_ 988 EC_BU_CBC10A 1712;
BA_ "FlexKomIsMotorola" SG_ 988 EC_BU_CBC10A 1;
BA_ "FlexKomComment" SG_ 988 EC_BU_CBC10A "Backup for CBC ecu configuration 10";
BA_ "GenSigSNA" SG_ 988 EC_BU_CBC10B "0h";
BA_ "GenSigSendType" SG_ 988 EC_BU_CBC10B 1;
BA_ "FlexKomSigStartValue" SG_ 988 EC_BU_CBC10B "00000000h";
BA_ "FlexKomSigStartPos" SG_ 988 EC_BU_CBC10B 7;
BA_ "FlexKomSigName" SG_ 988 EC_BU_CBC10B "EC_BU_CBC10";
BA_ "FlexKomSigLaenge" SG_ 988 EC_BU_CBC10B 32;
BA_ "FlexKomSID" SG_ 988 EC_BU_CBC10B 1712;
BA_ "FlexKomIsMotorola" SG_ 988 EC_BU_CBC10B 1;
BA_ "FlexKomComment" SG_ 988 EC_BU_CBC10B "Backup for CBC ecu configuration 10";
BA_ "GenSigSNA" SG_ 988 EC_BU_CBC11 "0h";
BA_ "GenSigSendType" SG_ 988 EC_BU_CBC11 1;
BA_ "FlexKomSigStartValue" SG_ 988 EC_BU_CBC11 "00000000h";
BA_ "FlexKomSigStartPos" SG_ 988 EC_BU_CBC11 39;
BA_ "FlexKomSigName" SG_ 988 EC_BU_CBC11 "EC_BU_CBC11";
BA_ "FlexKomSigLaenge" SG_ 988 EC_BU_CBC11 32;
BA_ "FlexKomSID" SG_ 988 EC_BU_CBC11 1713;
BA_ "FlexKomIsMotorola" SG_ 988 EC_BU_CBC11 1;
BA_ "FlexKomComment" SG_ 988 EC_BU_CBC11 "Backup for CBC ecu configuration 11";
BA_ "GenSigStartValue" SG_ 988 EC_BU_ECUCfg11_Stat 3;
BA_ "GenSigSNA" SG_ 988 EC_BU_ECUCfg11_Stat "3h";
BA_ "GenSigSendType" SG_ 988 EC_BU_ECUCfg11_Stat 1;
BA_ "FlexKomSigStartValue" SG_ 988 EC_BU_ECUCfg11_Stat "03h";
BA_ "FlexKomSigStartPos" SG_ 988 EC_BU_ECUCfg11_Stat 1;
BA_ "FlexKomSigName" SG_ 988 EC_BU_ECUCfg11_Stat "EC_BU_ECUCfg11_Stat";
BA_ "FlexKomSigLaenge" SG_ 988 EC_BU_ECUCfg11_Stat 2;
BA_ "FlexKomSID" SG_ 988 EC_BU_ECUCfg11_Stat 1711;
BA_ "FlexKomIsMotorola" SG_ 988 EC_BU_ECUCfg11_Stat 1;
BA_ "FlexKomComment" SG_ 988 EC_BU_ECUCfg11_Stat "Backup for ECU Configuration messages status 11";
BA_ "GenSigSNA" SG_ 987 EC_BU_Cluster5A "0h";
BA_ "GenSigSendType" SG_ 987 EC_BU_Cluster5A 1;
BA_ "FlexKomSigStartValue" SG_ 987 EC_BU_Cluster5A "0000000000000000h";
BA_ "FlexKomSigStartPos" SG_ 987 EC_BU_Cluster5A 7;
BA_ "FlexKomSigName" SG_ 987 EC_BU_Cluster5A "EC_BU_Cluster5";
BA_ "FlexKomSigLaenge" SG_ 987 EC_BU_Cluster5A 64;
BA_ "FlexKomSID" SG_ 987 EC_BU_Cluster5A 1837;
BA_ "FlexKomIsMotorola" SG_ 987 EC_BU_Cluster5A 1;
BA_ "FlexKomComment" SG_ 987 EC_BU_Cluster5A "Backup for Instrument cluster ecu configuration 5";
BA_ "GenSigSNA" SG_ 987 EC_BU_Cluster5B "0h";
BA_ "GenSigSendType" SG_ 987 EC_BU_Cluster5B 1;
BA_ "FlexKomSigStartValue" SG_ 987 EC_BU_Cluster5B "0000000000000000h";
BA_ "FlexKomSigStartPos" SG_ 987 EC_BU_Cluster5B 7;
BA_ "FlexKomSigName" SG_ 987 EC_BU_Cluster5B "EC_BU_Cluster5";
BA_ "FlexKomSigLaenge" SG_ 987 EC_BU_Cluster5B 64;
BA_ "FlexKomSID" SG_ 987 EC_BU_Cluster5B 1837;
BA_ "FlexKomIsMotorola" SG_ 987 EC_BU_Cluster5B 1;
BA_ "FlexKomComment" SG_ 987 EC_BU_Cluster5B "Backup for Instrument cluster ecu configuration 5";
BA_ "GenSigSNA" SG_ 987 EC_BU_Cluster5C "0h";
BA_ "GenSigSendType" SG_ 987 EC_BU_Cluster5C 1;
BA_ "FlexKomSigStartValue" SG_ 987 EC_BU_Cluster5C "0000000000000000h";
BA_ "FlexKomSigStartPos" SG_ 987 EC_BU_Cluster5C 7;
BA_ "FlexKomSigName" SG_ 987 EC_BU_Cluster5C "EC_BU_Cluster5";
BA_ "FlexKomSigLaenge" SG_ 987 EC_BU_Cluster5C 64;
BA_ "FlexKomSID" SG_ 987 EC_BU_Cluster5C 1837;
BA_ "FlexKomIsMotorola" SG_ 987 EC_BU_Cluster5C 1;
BA_ "FlexKomComment" SG_ 987 EC_BU_Cluster5C "Backup for Instrument cluster ecu configuration 5";
BA_ "GenSigStartValue" SG_ 987 EC_BU_ECUCfg12_Stat 3;
BA_ "GenSigSNA" SG_ 987 EC_BU_ECUCfg12_Stat "3h";
BA_ "GenSigSendType" SG_ 987 EC_BU_ECUCfg12_Stat 1;
BA_ "FlexKomSigStartValue" SG_ 987 EC_BU_ECUCfg12_Stat "03h";
BA_ "FlexKomSigStartPos" SG_ 987 EC_BU_ECUCfg12_Stat 1;
BA_ "FlexKomSigName" SG_ 987 EC_BU_ECUCfg12_Stat "EC_BU_ECUCfg12_Stat";
BA_ "FlexKomSigLaenge" SG_ 987 EC_BU_ECUCfg12_Stat 2;
BA_ "FlexKomSID" SG_ 987 EC_BU_ECUCfg12_Stat 1836;
BA_ "FlexKomIsMotorola" SG_ 987 EC_BU_ECUCfg12_Stat 1;
BA_ "FlexKomComment" SG_ 987 EC_BU_ECUCfg12_Stat "Backup for ECU Configuration messages status 12";
BA_ "GenSigSNA" SG_ 986 EC_BU_CBC13A "0h";
BA_ "GenSigSendType" SG_ 986 EC_BU_CBC13A 1;
BA_ "FlexKomSigStartValue" SG_ 986 EC_BU_CBC13A "0000000000000000h";
BA_ "FlexKomSigStartPos" SG_ 986 EC_BU_CBC13A 7;
BA_ "FlexKomSigName" SG_ 986 EC_BU_CBC13A "EC_BU_CBC13";
BA_ "FlexKomSigLaenge" SG_ 986 EC_BU_CBC13A 64;
BA_ "FlexKomSID" SG_ 986 EC_BU_CBC13A 1991;
BA_ "FlexKomIsMotorola" SG_ 986 EC_BU_CBC13A 1;
BA_ "FlexKomComment" SG_ 986 EC_BU_CBC13A "CBC ecu configuration 13";
BA_ "GenSigSNA" SG_ 986 EC_BU_CBC13B "0h";
BA_ "GenSigSendType" SG_ 986 EC_BU_CBC13B 1;
BA_ "FlexKomSigStartValue" SG_ 986 EC_BU_CBC13B "0000000000000000h";
BA_ "FlexKomSigStartPos" SG_ 986 EC_BU_CBC13B 7;
BA_ "FlexKomSigName" SG_ 986 EC_BU_CBC13B "EC_BU_CBC13";
BA_ "FlexKomSigLaenge" SG_ 986 EC_BU_CBC13B 64;
BA_ "FlexKomSID" SG_ 986 EC_BU_CBC13B 1991;
BA_ "FlexKomIsMotorola" SG_ 986 EC_BU_CBC13B 1;
BA_ "FlexKomComment" SG_ 986 EC_BU_CBC13B "CBC ecu configuration 13";
BA_ "GenSigStartValue" SG_ 986 EC_BU_ECUCfg13_Stat 3;
BA_ "GenSigSNA" SG_ 986 EC_BU_ECUCfg13_Stat "3h";
BA_ "GenSigSendType" SG_ 986 EC_BU_ECUCfg13_Stat 1;
BA_ "FlexKomSigStartValue" SG_ 986 EC_BU_ECUCfg13_Stat "03h";
BA_ "FlexKomSigStartPos" SG_ 986 EC_BU_ECUCfg13_Stat 1;
BA_ "FlexKomSigName" SG_ 986 EC_BU_ECUCfg13_Stat "EC_BU_ECUCfg13_Stat";
BA_ "FlexKomSigLaenge" SG_ 986 EC_BU_ECUCfg13_Stat 2;
BA_ "FlexKomSID" SG_ 986 EC_BU_ECUCfg13_Stat 1871;
BA_ "FlexKomIsMotorola" SG_ 986 EC_BU_ECUCfg13_Stat 1;
BA_ "FlexKomComment" SG_ 986 EC_BU_ECUCfg13_Stat "Backup for ECU Configuration messages status 13";
BA_ "GenSigSNA" SG_ 985 EC_BU_CBC14A "0h";
BA_ "GenSigSendType" SG_ 985 EC_BU_CBC14A 1;
BA_ "FlexKomSigStartValue" SG_ 985 EC_BU_CBC14A "0000000000000000h";
BA_ "FlexKomSigStartPos" SG_ 985 EC_BU_CBC14A 7;
BA_ "FlexKomSigName" SG_ 985 EC_BU_CBC14A "EC_BU_CBC14";
BA_ "FlexKomSigLaenge" SG_ 985 EC_BU_CBC14A 64;
BA_ "FlexKomSID" SG_ 985 EC_BU_CBC14A 1953;
BA_ "FlexKomIsMotorola" SG_ 985 EC_BU_CBC14A 1;
BA_ "FlexKomComment" SG_ 985 EC_BU_CBC14A "CBC ecu configuration 14";
BA_ "GenSigSNA" SG_ 985 EC_BU_CBC14B "0h";
BA_ "GenSigSendType" SG_ 985 EC_BU_CBC14B 1;
BA_ "FlexKomSigStartValue" SG_ 985 EC_BU_CBC14B "0000000000000000h";
BA_ "FlexKomSigStartPos" SG_ 985 EC_BU_CBC14B 7;
BA_ "FlexKomSigName" SG_ 985 EC_BU_CBC14B "EC_BU_CBC14";
BA_ "FlexKomSigLaenge" SG_ 985 EC_BU_CBC14B 64;
BA_ "FlexKomSID" SG_ 985 EC_BU_CBC14B 1953;
BA_ "FlexKomIsMotorola" SG_ 985 EC_BU_CBC14B 1;
BA_ "FlexKomComment" SG_ 985 EC_BU_CBC14B "CBC ecu configuration 14";
BA_ "GenSigStartValue" SG_ 985 EC_BU_ECUCfg14_Stat 3;
BA_ "GenSigSNA" SG_ 985 EC_BU_ECUCfg14_Stat "3h";
BA_ "GenSigSendType" SG_ 985 EC_BU_ECUCfg14_Stat 1;
BA_ "FlexKomSigStartValue" SG_ 985 EC_BU_ECUCfg14_Stat "03h";
BA_ "FlexKomSigStartPos" SG_ 985 EC_BU_ECUCfg14_Stat 1;
BA_ "FlexKomSigName" SG_ 985 EC_BU_ECUCfg14_Stat "EC_BU_ECUCfg14_Stat";
BA_ "FlexKomSigLaenge" SG_ 985 EC_BU_ECUCfg14_Stat 2;
BA_ "FlexKomSID" SG_ 985 EC_BU_ECUCfg14_Stat 1952;
BA_ "FlexKomIsMotorola" SG_ 985 EC_BU_ECUCfg14_Stat 1;
BA_ "FlexKomComment" SG_ 985 EC_BU_ECUCfg14_Stat "Backup for ECU Configuration messages status 14";
BA_ "GenSigSNA" SG_ 707 EC_BU_CBC15A "0h";
BA_ "GenSigSendType" SG_ 707 EC_BU_CBC15A 1;
BA_ "FlexKomSigStartValue" SG_ 707 EC_BU_CBC15A "000000000000h";
BA_ "FlexKomSigStartPos" SG_ 707 EC_BU_CBC15A 7;
BA_ "FlexKomSigName" SG_ 707 EC_BU_CBC15A "EC_BU_CBC15";
BA_ "FlexKomSigLaenge" SG_ 707 EC_BU_CBC15A 48;
BA_ "FlexKomSID" SG_ 707 EC_BU_CBC15A 2075;
BA_ "FlexKomIsMotorola" SG_ 707 EC_BU_CBC15A 1;
BA_ "FlexKomComment" SG_ 707 EC_BU_CBC15A "CBC ecu configuration 15";
BA_ "GenSigSNA" SG_ 707 EC_BU_CBC15B "0h";
BA_ "GenSigSendType" SG_ 707 EC_BU_CBC15B 1;
BA_ "FlexKomSigStartValue" SG_ 707 EC_BU_CBC15B "000000000000h";
BA_ "FlexKomSigStartPos" SG_ 707 EC_BU_CBC15B 7;
BA_ "FlexKomSigName" SG_ 707 EC_BU_CBC15B "EC_BU_CBC15";
BA_ "FlexKomSigLaenge" SG_ 707 EC_BU_CBC15B 48;
BA_ "FlexKomSID" SG_ 707 EC_BU_CBC15B 2075;
BA_ "FlexKomIsMotorola" SG_ 707 EC_BU_CBC15B 1;
BA_ "FlexKomComment" SG_ 707 EC_BU_CBC15B "CBC ecu configuration 15";
BA_ "GenSigStartValue" SG_ 707 EC_BU_ECUCfg15_Stat 3;
BA_ "GenSigSNA" SG_ 707 EC_BU_ECUCfg15_Stat "3h";
BA_ "GenSigSendType" SG_ 707 EC_BU_ECUCfg15_Stat 1;
BA_ "FlexKomSigStartValue" SG_ 707 EC_BU_ECUCfg15_Stat "03h";
BA_ "FlexKomSigStartPos" SG_ 707 EC_BU_ECUCfg15_Stat 1;
BA_ "FlexKomSigName" SG_ 707 EC_BU_ECUCfg15_Stat "EC_BU_ECUCfg15_Stat";
BA_ "FlexKomSigLaenge" SG_ 707 EC_BU_ECUCfg15_Stat 2;
BA_ "FlexKomSID" SG_ 707 EC_BU_ECUCfg15_Stat 2074;
BA_ "FlexKomIsMotorola" SG_ 707 EC_BU_ECUCfg15_Stat 1;
BA_ "FlexKomComment" SG_ 707 EC_BU_ECUCfg15_Stat "Backup for ECU Configuration messages status 15";
BA_ "GenSigSNA" SG_ 707 EC_BU_Suspension "0h";
BA_ "GenSigSendType" SG_ 707 EC_BU_Suspension 1;
BA_ "FlexKomSigStartValue" SG_ 707 EC_BU_Suspension "0000h";
BA_ "FlexKomSigStartPos" SG_ 707 EC_BU_Suspension 55;
BA_ "FlexKomSigName" SG_ 707 EC_BU_Suspension "EC_BU_Suspension";
BA_ "FlexKomSigLaenge" SG_ 707 EC_BU_Suspension 16;
BA_ "FlexKomSID" SG_ 707 EC_BU_Suspension 914;
BA_ "FlexKomIsMotorola" SG_ 707 EC_BU_Suspension 1;
BA_ "FlexKomComment" SG_ 707 EC_BU_Suspension "Backup for Suspension ecu configuration";
BA_ "GenSigSNA" SG_ 714 EC_BU_AudTel3A "0h";
BA_ "GenSigSendType" SG_ 714 EC_BU_AudTel3A 1;
BA_ "FlexKomSigStartValue" SG_ 714 EC_BU_AudTel3A "0000000000000000h";
BA_ "FlexKomSigStartPos" SG_ 714 EC_BU_AudTel3A 7;
BA_ "FlexKomSigName" SG_ 714 EC_BU_AudTel3A "EC_BU_AudTel3";
BA_ "FlexKomSigLaenge" SG_ 714 EC_BU_AudTel3A 64;
BA_ "FlexKomSID" SG_ 714 EC_BU_AudTel3A 2287;
BA_ "FlexKomIsMotorola" SG_ 714 EC_BU_AudTel3A 1;
BA_ "FlexKomComment" SG_ 714 EC_BU_AudTel3A "Backup for audio and telematics ecu configuration ";
BA_ "GenSigSNA" SG_ 714 EC_BU_AudTel3B "0h";
BA_ "GenSigSendType" SG_ 714 EC_BU_AudTel3B 1;
BA_ "FlexKomSigStartValue" SG_ 714 EC_BU_AudTel3B "0000000000000000h";
BA_ "FlexKomSigStartPos" SG_ 714 EC_BU_AudTel3B 7;
BA_ "FlexKomSigName" SG_ 714 EC_BU_AudTel3B "EC_BU_AudTel3";
BA_ "FlexKomSigLaenge" SG_ 714 EC_BU_AudTel3B 64;
BA_ "FlexKomSID" SG_ 714 EC_BU_AudTel3B 2287;
BA_ "FlexKomIsMotorola" SG_ 714 EC_BU_AudTel3B 1;
BA_ "FlexKomComment" SG_ 714 EC_BU_AudTel3B "Backup for audio and telematics ecu configuration ";
BA_ "GenSigStartValue" SG_ 714 EC_BU_ECUCfg16_Stat 3;
BA_ "GenSigSNA" SG_ 714 EC_BU_ECUCfg16_Stat "3h";
BA_ "GenSigSendType" SG_ 714 EC_BU_ECUCfg16_Stat 1;
BA_ "FlexKomSigStartValue" SG_ 714 EC_BU_ECUCfg16_Stat "03h";
BA_ "FlexKomSigStartPos" SG_ 714 EC_BU_ECUCfg16_Stat 1;
BA_ "FlexKomSigName" SG_ 714 EC_BU_ECUCfg16_Stat "EC_BU_ECUCfg16_Stat";
BA_ "FlexKomSigLaenge" SG_ 714 EC_BU_ECUCfg16_Stat 2;
BA_ "FlexKomSID" SG_ 714 EC_BU_ECUCfg16_Stat 2289;
BA_ "FlexKomIsMotorola" SG_ 714 EC_BU_ECUCfg16_Stat 1;
BA_ "FlexKomComment" SG_ 714 EC_BU_ECUCfg16_Stat "Backup for ECU Configuration messages status 16";
BA_ "GenSigSNA" SG_ 715 EC_BU_CBC17 "0h";
BA_ "GenSigSendType" SG_ 715 EC_BU_CBC17 1;
BA_ "FlexKomSigStartValue" SG_ 715 EC_BU_CBC17 "0300000000000000h";
BA_ "FlexKomSigStartPos" SG_ 715 EC_BU_CBC17 7;
BA_ "FlexKomSigName" SG_ 715 EC_BU_CBC17 "EcuBuCfg17Pkt";
BA_ "FlexKomSigLaenge" SG_ 715 EC_BU_CBC17 64;
BA_ "FlexKomSID" SG_ 715 EC_BU_CBC17 2479;
BA_ "FlexKomIsMotorola" SG_ 715 EC_BU_CBC17 1;
BA_ "FlexKomComment" SG_ 715 EC_BU_CBC17 "ECU backup configuration 17 packet";
BA_ "GenSigStartValue" SG_ 715 EC_BU_ECUCfg17_Stat 3;
BA_ "GenSigSNA" SG_ 715 EC_BU_ECUCfg17_Stat "3h";
BA_ "GenSigSendType" SG_ 715 EC_BU_ECUCfg17_Stat 1;
BA_ "FlexKomSigStartValue" SG_ 715 EC_BU_ECUCfg17_Stat "0300000000000000h";
BA_ "FlexKomSigStartPos" SG_ 715 EC_BU_ECUCfg17_Stat 7;
BA_ "FlexKomSigName" SG_ 715 EC_BU_ECUCfg17_Stat "EcuBuCfg17Pkt";
BA_ "FlexKomSigLaenge" SG_ 715 EC_BU_ECUCfg17_Stat 64;
BA_ "FlexKomSID" SG_ 715 EC_BU_ECUCfg17_Stat 2479;
BA_ "FlexKomIsMotorola" SG_ 715 EC_BU_ECUCfg17_Stat 1;
BA_ "FlexKomComment" SG_ 715 EC_BU_ECUCfg17_Stat "ECU backup configuration 17 packet";
BA_ "GenSigSNA" SG_ 715 EC_BU_HVAC1 "0h";
BA_ "GenSigSendType" SG_ 715 EC_BU_HVAC1 1;
BA_ "FlexKomSigStartValue" SG_ 715 EC_BU_HVAC1 "0300000000000000h";
BA_ "FlexKomSigStartPos" SG_ 715 EC_BU_HVAC1 7;
BA_ "FlexKomSigName" SG_ 715 EC_BU_HVAC1 "EcuBuCfg17Pkt";
BA_ "FlexKomSigLaenge" SG_ 715 EC_BU_HVAC1 64;
BA_ "FlexKomSID" SG_ 715 EC_BU_HVAC1 2479;
BA_ "FlexKomIsMotorola" SG_ 715 EC_BU_HVAC1 1;
BA_ "FlexKomComment" SG_ 715 EC_BU_HVAC1 "ECU backup configuration 17 packet";
BA_ "GenSigSNA" SG_ 715 EC_BU_HVAC2 "0h";
BA_ "GenSigSendType" SG_ 715 EC_BU_HVAC2 1;
BA_ "FlexKomSigStartValue" SG_ 715 EC_BU_HVAC2 "0300000000000000h";
BA_ "FlexKomSigStartPos" SG_ 715 EC_BU_HVAC2 7;
BA_ "FlexKomSigName" SG_ 715 EC_BU_HVAC2 "EcuBuCfg17Pkt";
BA_ "FlexKomSigLaenge" SG_ 715 EC_BU_HVAC2 64;
BA_ "FlexKomSID" SG_ 715 EC_BU_HVAC2 2479;
BA_ "FlexKomIsMotorola" SG_ 715 EC_BU_HVAC2 1;
BA_ "FlexKomComment" SG_ 715 EC_BU_HVAC2 "ECU backup configuration 17 packet";
BA_ "GenSigSNA" SG_ 715 EC_BU_PTS "0h";
BA_ "GenSigSendType" SG_ 715 EC_BU_PTS 1;
BA_ "FlexKomSigStartValue" SG_ 715 EC_BU_PTS "0300000000000000h";
BA_ "FlexKomSigStartPos" SG_ 715 EC_BU_PTS 7;
BA_ "FlexKomSigName" SG_ 715 EC_BU_PTS "EcuBuCfg17Pkt";
BA_ "FlexKomSigLaenge" SG_ 715 EC_BU_PTS 64;
BA_ "FlexKomSID" SG_ 715 EC_BU_PTS 2479;
BA_ "FlexKomIsMotorola" SG_ 715 EC_BU_PTS 1;
BA_ "FlexKomComment" SG_ 715 EC_BU_PTS "ECU backup configuration 17 packet";
BA_ "GenSigSNA" SG_ 715 EC_BU_SeatsA "0h";
BA_ "GenSigSendType" SG_ 715 EC_BU_SeatsA 1;
BA_ "FlexKomSigStartValue" SG_ 715 EC_BU_SeatsA "0300000000000000h";
BA_ "FlexKomSigStartPos" SG_ 715 EC_BU_SeatsA 7;
BA_ "FlexKomSigName" SG_ 715 EC_BU_SeatsA "EcuBuCfg17Pkt";
BA_ "FlexKomSigLaenge" SG_ 715 EC_BU_SeatsA 64;
BA_ "FlexKomSID" SG_ 715 EC_BU_SeatsA 2479;
BA_ "FlexKomIsMotorola" SG_ 715 EC_BU_SeatsA 1;
BA_ "FlexKomComment" SG_ 715 EC_BU_SeatsA "ECU backup configuration 17 packet";
BA_ "GenSigSNA" SG_ 715 EC_BU_SeatsB "0h";
BA_ "GenSigSendType" SG_ 715 EC_BU_SeatsB 1;
BA_ "FlexKomSigStartValue" SG_ 715 EC_BU_SeatsB "0300000000000000h";
BA_ "FlexKomSigStartPos" SG_ 715 EC_BU_SeatsB 7;
BA_ "FlexKomSigName" SG_ 715 EC_BU_SeatsB "EcuBuCfg17Pkt";
BA_ "FlexKomSigLaenge" SG_ 715 EC_BU_SeatsB 64;
BA_ "FlexKomSID" SG_ 715 EC_BU_SeatsB 2479;
BA_ "FlexKomIsMotorola" SG_ 715 EC_BU_SeatsB 1;
BA_ "FlexKomComment" SG_ 715 EC_BU_SeatsB "ECU backup configuration 17 packet";
BA_ "GenSigSNA" SG_ 716 EC_BU_AudTel4A "0h";
BA_ "GenSigSendType" SG_ 716 EC_BU_AudTel4A 1;
BA_ "FlexKomSigStartValue" SG_ 716 EC_BU_AudTel4A "0300000000000000h";
BA_ "FlexKomSigStartPos" SG_ 716 EC_BU_AudTel4A 7;
BA_ "FlexKomSigName" SG_ 716 EC_BU_AudTel4A "EcuBuCfg18Pkt";
BA_ "FlexKomSigLaenge" SG_ 716 EC_BU_AudTel4A 64;
BA_ "FlexKomSID" SG_ 716 EC_BU_AudTel4A 3024;
BA_ "FlexKomIsMotorola" SG_ 716 EC_BU_AudTel4A 1;
BA_ "FlexKomComment" SG_ 716 EC_BU_AudTel4A "ECU backup configuration 18 packet";
BA_ "GenSigSNA" SG_ 716 EC_BU_AudTel4B "0h";
BA_ "GenSigSendType" SG_ 716 EC_BU_AudTel4B 1;
BA_ "FlexKomSigStartValue" SG_ 716 EC_BU_AudTel4B "0300000000000000h";
BA_ "FlexKomSigStartPos" SG_ 716 EC_BU_AudTel4B 7;
BA_ "FlexKomSigName" SG_ 716 EC_BU_AudTel4B "EcuBuCfg18Pkt";
BA_ "FlexKomSigLaenge" SG_ 716 EC_BU_AudTel4B 64;
BA_ "FlexKomSID" SG_ 716 EC_BU_AudTel4B 3024;
BA_ "FlexKomIsMotorola" SG_ 716 EC_BU_AudTel4B 1;
BA_ "FlexKomComment" SG_ 716 EC_BU_AudTel4B "ECU backup configuration 18 packet";
BA_ "GenSigStartValue" SG_ 716 EC_BU_ECUCfg18_Stat 3;
BA_ "GenSigSNA" SG_ 716 EC_BU_ECUCfg18_Stat "3h";
BA_ "GenSigSendType" SG_ 716 EC_BU_ECUCfg18_Stat 1;
BA_ "FlexKomSigStartValue" SG_ 716 EC_BU_ECUCfg18_Stat "0300000000000000h";
BA_ "FlexKomSigStartPos" SG_ 716 EC_BU_ECUCfg18_Stat 7;
BA_ "FlexKomSigName" SG_ 716 EC_BU_ECUCfg18_Stat "EcuBuCfg18Pkt";
BA_ "FlexKomSigLaenge" SG_ 716 EC_BU_ECUCfg18_Stat 64;
BA_ "FlexKomSID" SG_ 716 EC_BU_ECUCfg18_Stat 3024;
BA_ "FlexKomIsMotorola" SG_ 716 EC_BU_ECUCfg18_Stat 1;
BA_ "FlexKomComment" SG_ 716 EC_BU_ECUCfg18_Stat "ECU backup configuration 18 packet";
BA_ "GenSigSNA" SG_ 1017 EC_BU_CBC3A "0h";
BA_ "GenSigSendType" SG_ 1017 EC_BU_CBC3A 1;
BA_ "FlexKomSigStartValue" SG_ 1017 EC_BU_CBC3A "00000000h";
BA_ "FlexKomSigStartPos" SG_ 1017 EC_BU_CBC3A 7;
BA_ "FlexKomSigName" SG_ 1017 EC_BU_CBC3A "EC_BU_CBC3";
BA_ "FlexKomSigLaenge" SG_ 1017 EC_BU_CBC3A 32;
BA_ "FlexKomSID" SG_ 1017 EC_BU_CBC3A 909;
BA_ "FlexKomIsMotorola" SG_ 1017 EC_BU_CBC3A 1;
BA_ "FlexKomComment" SG_ 1017 EC_BU_CBC3A "Backup for CBC ecu configuration 3";
BA_ "GenSigSNA" SG_ 1017 EC_BU_CBC3B "0h";
BA_ "GenSigSendType" SG_ 1017 EC_BU_CBC3B 1;
BA_ "FlexKomSigStartValue" SG_ 1017 EC_BU_CBC3B "00000000h";
BA_ "FlexKomSigStartPos" SG_ 1017 EC_BU_CBC3B 7;
BA_ "FlexKomSigName" SG_ 1017 EC_BU_CBC3B "EC_BU_CBC3";
BA_ "FlexKomSigLaenge" SG_ 1017 EC_BU_CBC3B 32;
BA_ "FlexKomSID" SG_ 1017 EC_BU_CBC3B 909;
BA_ "FlexKomIsMotorola" SG_ 1017 EC_BU_CBC3B 1;
BA_ "FlexKomComment" SG_ 1017 EC_BU_CBC3B "Backup for CBC ecu configuration 3";
BA_ "GenSigSNA" SG_ 1017 EC_BU_CBC4 "0h";
BA_ "GenSigSendType" SG_ 1017 EC_BU_CBC4 1;
BA_ "FlexKomSigStartValue" SG_ 1017 EC_BU_CBC4 "00000000h";
BA_ "FlexKomSigStartPos" SG_ 1017 EC_BU_CBC4 39;
BA_ "FlexKomSigName" SG_ 1017 EC_BU_CBC4 "EC_BU_CBC4";
BA_ "FlexKomSigLaenge" SG_ 1017 EC_BU_CBC4 32;
BA_ "FlexKomSID" SG_ 1017 EC_BU_CBC4 910;
BA_ "FlexKomIsMotorola" SG_ 1017 EC_BU_CBC4 1;
BA_ "FlexKomComment" SG_ 1017 EC_BU_CBC4 "Backup for CBC ecu configuration 4";
BA_ "GenSigStartValue" SG_ 1017 EC_BU_ECUCfg2_Stat 3;
BA_ "GenSigSNA" SG_ 1017 EC_BU_ECUCfg2_Stat "3h";
BA_ "GenSigSendType" SG_ 1017 EC_BU_ECUCfg2_Stat 1;
BA_ "FlexKomSigStartValue" SG_ 1017 EC_BU_ECUCfg2_Stat "03h";
BA_ "FlexKomSigStartPos" SG_ 1017 EC_BU_ECUCfg2_Stat 1;
BA_ "FlexKomSigName" SG_ 1017 EC_BU_ECUCfg2_Stat "EC_BU_ECUCfg2_Stat";
BA_ "FlexKomSigLaenge" SG_ 1017 EC_BU_ECUCfg2_Stat 2;
BA_ "FlexKomSID" SG_ 1017 EC_BU_ECUCfg2_Stat 1065;
BA_ "FlexKomIsMotorola" SG_ 1017 EC_BU_ECUCfg2_Stat 1;
BA_ "FlexKomComment" SG_ 1017 EC_BU_ECUCfg2_Stat "Backup for ECU Configuration messages status 2";
BA_ "GenSigSNA" SG_ 1018 EC_BU_AudTel1A "0h";
BA_ "GenSigSendType" SG_ 1018 EC_BU_AudTel1A 1;
BA_ "FlexKomSigStartValue" SG_ 1018 EC_BU_AudTel1A "00000000h";
BA_ "FlexKomSigStartPos" SG_ 1018 EC_BU_AudTel1A 7;
BA_ "FlexKomSigName" SG_ 1018 EC_BU_AudTel1A "EC_BU_AudTel1";
BA_ "FlexKomSigLaenge" SG_ 1018 EC_BU_AudTel1A 32;
BA_ "FlexKomSID" SG_ 1018 EC_BU_AudTel1A 904;
BA_ "FlexKomIsMotorola" SG_ 1018 EC_BU_AudTel1A 1;
BA_ "FlexKomComment" SG_ 1018 EC_BU_AudTel1A "Backup for Audio and telematics ecu configuration ";
BA_ "GenSigSNA" SG_ 1018 EC_BU_AudTel1B "0h";
BA_ "GenSigSendType" SG_ 1018 EC_BU_AudTel1B 1;
BA_ "FlexKomSigStartValue" SG_ 1018 EC_BU_AudTel1B "00000000h";
BA_ "FlexKomSigStartPos" SG_ 1018 EC_BU_AudTel1B 7;
BA_ "FlexKomSigName" SG_ 1018 EC_BU_AudTel1B "EC_BU_AudTel1";
BA_ "FlexKomSigLaenge" SG_ 1018 EC_BU_AudTel1B 32;
BA_ "FlexKomSID" SG_ 1018 EC_BU_AudTel1B 904;
BA_ "FlexKomIsMotorola" SG_ 1018 EC_BU_AudTel1B 1;
BA_ "FlexKomComment" SG_ 1018 EC_BU_AudTel1B "Backup for Audio and telematics ecu configuration ";
BA_ "GenSigSNA" SG_ 1018 EC_BU_AudTel2 "0h";
BA_ "GenSigSendType" SG_ 1018 EC_BU_AudTel2 1;
BA_ "FlexKomSigStartValue" SG_ 1018 EC_BU_AudTel2 "00000000h";
BA_ "FlexKomSigStartPos" SG_ 1018 EC_BU_AudTel2 39;
BA_ "FlexKomSigName" SG_ 1018 EC_BU_AudTel2 "EC_BU_AudTel2";
BA_ "FlexKomSigLaenge" SG_ 1018 EC_BU_AudTel2 32;
BA_ "FlexKomSID" SG_ 1018 EC_BU_AudTel2 905;
BA_ "FlexKomIsMotorola" SG_ 1018 EC_BU_AudTel2 1;
BA_ "FlexKomComment" SG_ 1018 EC_BU_AudTel2 "Backup for Audio and telematics ecu configuration ";
BA_ "GenSigStartValue" SG_ 1018 EC_BU_ECUCfg3_Stat 3;
BA_ "GenSigSNA" SG_ 1018 EC_BU_ECUCfg3_Stat "3h";
BA_ "GenSigSendType" SG_ 1018 EC_BU_ECUCfg3_Stat 1;
BA_ "FlexKomSigStartValue" SG_ 1018 EC_BU_ECUCfg3_Stat "03h";
BA_ "FlexKomSigStartPos" SG_ 1018 EC_BU_ECUCfg3_Stat 1;
BA_ "FlexKomSigName" SG_ 1018 EC_BU_ECUCfg3_Stat "EC_BU_ECUCfg3_Stat";
BA_ "FlexKomSigLaenge" SG_ 1018 EC_BU_ECUCfg3_Stat 2;
BA_ "FlexKomSID" SG_ 1018 EC_BU_ECUCfg3_Stat 1066;
BA_ "FlexKomIsMotorola" SG_ 1018 EC_BU_ECUCfg3_Stat 1;
BA_ "FlexKomComment" SG_ 1018 EC_BU_ECUCfg3_Stat "Backup for ECU Configuration messages status 3";
BA_ "GenSigSNA" SG_ 1019 EC_BU_Cluster1A "0h";
BA_ "GenSigSendType" SG_ 1019 EC_BU_Cluster1A 1;
BA_ "FlexKomSigStartValue" SG_ 1019 EC_BU_Cluster1A "00000000h";
BA_ "FlexKomSigStartPos" SG_ 1019 EC_BU_Cluster1A 7;
BA_ "FlexKomSigName" SG_ 1019 EC_BU_Cluster1A "EC_BU_Cluster1";
BA_ "FlexKomSigLaenge" SG_ 1019 EC_BU_Cluster1A 32;
BA_ "FlexKomSID" SG_ 1019 EC_BU_Cluster1A 911;
BA_ "FlexKomIsMotorola" SG_ 1019 EC_BU_Cluster1A 1;
BA_ "FlexKomComment" SG_ 1019 EC_BU_Cluster1A "Backup for Instrument cluster ecu configuration 1";
BA_ "GenSigSNA" SG_ 1019 EC_BU_Cluster1B "0h";
BA_ "GenSigSendType" SG_ 1019 EC_BU_Cluster1B 1;
BA_ "FlexKomSigStartValue" SG_ 1019 EC_BU_Cluster1B "00000000h";
BA_ "FlexKomSigStartPos" SG_ 1019 EC_BU_Cluster1B 7;
BA_ "FlexKomSigName" SG_ 1019 EC_BU_Cluster1B "EC_BU_Cluster1";
BA_ "FlexKomSigLaenge" SG_ 1019 EC_BU_Cluster1B 32;
BA_ "FlexKomSID" SG_ 1019 EC_BU_Cluster1B 911;
BA_ "FlexKomIsMotorola" SG_ 1019 EC_BU_Cluster1B 1;
BA_ "FlexKomComment" SG_ 1019 EC_BU_Cluster1B "Backup for Instrument cluster ecu configuration 1";
BA_ "GenSigSNA" SG_ 1019 EC_BU_Cluster2 "0h";
BA_ "GenSigSendType" SG_ 1019 EC_BU_Cluster2 1;
BA_ "FlexKomSigStartValue" SG_ 1019 EC_BU_Cluster2 "00000000h";
BA_ "FlexKomSigStartPos" SG_ 1019 EC_BU_Cluster2 39;
BA_ "FlexKomSigName" SG_ 1019 EC_BU_Cluster2 "EC_BU_Cluster2";
BA_ "FlexKomSigLaenge" SG_ 1019 EC_BU_Cluster2 32;
BA_ "FlexKomSID" SG_ 1019 EC_BU_Cluster2 912;
BA_ "FlexKomIsMotorola" SG_ 1019 EC_BU_Cluster2 1;
BA_ "FlexKomComment" SG_ 1019 EC_BU_Cluster2 "Backup for Instrument cluster ecu configuration 2";
BA_ "GenSigStartValue" SG_ 1019 EC_BU_ECUCfg4_Stat 3;
BA_ "GenSigSNA" SG_ 1019 EC_BU_ECUCfg4_Stat "3h";
BA_ "GenSigSendType" SG_ 1019 EC_BU_ECUCfg4_Stat 1;
BA_ "FlexKomSigStartValue" SG_ 1019 EC_BU_ECUCfg4_Stat "03h";
BA_ "FlexKomSigStartPos" SG_ 1019 EC_BU_ECUCfg4_Stat 1;
BA_ "FlexKomSigName" SG_ 1019 EC_BU_ECUCfg4_Stat "EC_BU_ECUCfg4_Stat";
BA_ "FlexKomSigLaenge" SG_ 1019 EC_BU_ECUCfg4_Stat 2;
BA_ "FlexKomSID" SG_ 1019 EC_BU_ECUCfg4_Stat 1067;
BA_ "FlexKomIsMotorola" SG_ 1019 EC_BU_ECUCfg4_Stat 1;
BA_ "FlexKomComment" SG_ 1019 EC_BU_ECUCfg4_Stat "Backup for ECU Configuration messages status 4";
BA_ "GenSigSNA" SG_ 1020 EC_BU_Doors "0h";
BA_ "GenSigSendType" SG_ 1020 EC_BU_Doors 1;
BA_ "FlexKomSigStartValue" SG_ 1020 EC_BU_Doors "000000h";
BA_ "FlexKomSigStartPos" SG_ 1020 EC_BU_Doors 31;
BA_ "FlexKomSigName" SG_ 1020 EC_BU_Doors "EC_BU_Doors";
BA_ "FlexKomSigLaenge" SG_ 1020 EC_BU_Doors 24;
BA_ "FlexKomSID" SG_ 1020 EC_BU_Doors 913;
BA_ "FlexKomIsMotorola" SG_ 1020 EC_BU_Doors 1;
BA_ "FlexKomComment" SG_ 1020 EC_BU_Doors "Backup for Doors ecu configuration";
BA_ "GenSigStartValue" SG_ 1020 EC_BU_ECUCfg5_Stat 3;
BA_ "GenSigSNA" SG_ 1020 EC_BU_ECUCfg5_Stat "3h";
BA_ "GenSigSendType" SG_ 1020 EC_BU_ECUCfg5_Stat 1;
BA_ "FlexKomSigStartValue" SG_ 1020 EC_BU_ECUCfg5_Stat "03h";
BA_ "FlexKomSigStartPos" SG_ 1020 EC_BU_ECUCfg5_Stat 1;
BA_ "FlexKomSigName" SG_ 1020 EC_BU_ECUCfg5_Stat "EC_BU_ECUCfg5_Stat";
BA_ "FlexKomSigLaenge" SG_ 1020 EC_BU_ECUCfg5_Stat 2;
BA_ "FlexKomSID" SG_ 1020 EC_BU_ECUCfg5_Stat 1068;
BA_ "FlexKomIsMotorola" SG_ 1020 EC_BU_ECUCfg5_Stat 1;
BA_ "FlexKomComment" SG_ 1020 EC_BU_ECUCfg5_Stat "Backup for ECU Configuration messages status 5";
BA_ "GenSigSNA" SG_ 1020 EC_BU_Memory "0h";
BA_ "GenSigSendType" SG_ 1020 EC_BU_Memory 1;
BA_ "FlexKomSigStartValue" SG_ 1020 EC_BU_Memory "0000h";
BA_ "FlexKomSigStartPos" SG_ 1020 EC_BU_Memory 55;
BA_ "FlexKomSigName" SG_ 1020 EC_BU_Memory "EC_BU_Memory";
BA_ "FlexKomSigLaenge" SG_ 1020 EC_BU_Memory 16;
BA_ "FlexKomSID" SG_ 1020 EC_BU_Memory 916;
BA_ "FlexKomIsMotorola" SG_ 1020 EC_BU_Memory 1;
BA_ "FlexKomComment" SG_ 1020 EC_BU_Memory "Backup for Memory ecu configuration";
BA_ "GenSigSNA" SG_ 1020 EC_BU_WirelessA "0h";
BA_ "GenSigSendType" SG_ 1020 EC_BU_WirelessA 1;
BA_ "FlexKomSigStartValue" SG_ 1020 EC_BU_WirelessA "000000h";
BA_ "FlexKomSigStartPos" SG_ 1020 EC_BU_WirelessA 7;
BA_ "FlexKomSigName" SG_ 1020 EC_BU_WirelessA "EC_BU_Wireless";
BA_ "FlexKomSigLaenge" SG_ 1020 EC_BU_WirelessA 24;
BA_ "FlexKomSID" SG_ 1020 EC_BU_WirelessA 915;
BA_ "FlexKomIsMotorola" SG_ 1020 EC_BU_WirelessA 1;
BA_ "FlexKomComment" SG_ 1020 EC_BU_WirelessA "Backup for Wireless ecu configuration";
BA_ "GenSigSNA" SG_ 1020 EC_BU_WirelessB "0h";
BA_ "GenSigSendType" SG_ 1020 EC_BU_WirelessB 1;
BA_ "FlexKomSigStartValue" SG_ 1020 EC_BU_WirelessB "000000h";
BA_ "FlexKomSigStartPos" SG_ 1020 EC_BU_WirelessB 7;
BA_ "FlexKomSigName" SG_ 1020 EC_BU_WirelessB "EC_BU_Wireless";
BA_ "FlexKomSigLaenge" SG_ 1020 EC_BU_WirelessB 24;
BA_ "FlexKomSID" SG_ 1020 EC_BU_WirelessB 915;
BA_ "FlexKomIsMotorola" SG_ 1020 EC_BU_WirelessB 1;
BA_ "FlexKomComment" SG_ 1020 EC_BU_WirelessB "Backup for Wireless ecu configuration";
BA_ "GenSigSNA" SG_ 1021 EC_BU_BrakesA "0h";
BA_ "GenSigSendType" SG_ 1021 EC_BU_BrakesA 1;
BA_ "FlexKomSigStartValue" SG_ 1021 EC_BU_BrakesA "0000h";
BA_ "FlexKomSigStartPos" SG_ 1021 EC_BU_BrakesA 7;
BA_ "FlexKomSigName" SG_ 1021 EC_BU_BrakesA "EC_BU_Brakes";
BA_ "FlexKomSigLaenge" SG_ 1021 EC_BU_BrakesA 16;
BA_ "FlexKomSID" SG_ 1021 EC_BU_BrakesA 906;
BA_ "FlexKomIsMotorola" SG_ 1021 EC_BU_BrakesA 1;
BA_ "FlexKomComment" SG_ 1021 EC_BU_BrakesA "Backup for Brake system ecu configuration";
BA_ "GenSigSNA" SG_ 1021 EC_BU_BrakesB "0h";
BA_ "GenSigSendType" SG_ 1021 EC_BU_BrakesB 1;
BA_ "FlexKomSigStartValue" SG_ 1021 EC_BU_BrakesB "0000h";
BA_ "FlexKomSigStartPos" SG_ 1021 EC_BU_BrakesB 7;
BA_ "FlexKomSigName" SG_ 1021 EC_BU_BrakesB "EC_BU_Brakes";
BA_ "FlexKomSigLaenge" SG_ 1021 EC_BU_BrakesB 16;
BA_ "FlexKomSID" SG_ 1021 EC_BU_BrakesB 906;
BA_ "FlexKomIsMotorola" SG_ 1021 EC_BU_BrakesB 1;
BA_ "FlexKomComment" SG_ 1021 EC_BU_BrakesB "Backup for Brake system ecu configuration";
BA_ "GenSigStartValue" SG_ 1021 EC_BU_ECUCfg6_Stat 3;
BA_ "GenSigSNA" SG_ 1021 EC_BU_ECUCfg6_Stat "3h";
BA_ "GenSigSendType" SG_ 1021 EC_BU_ECUCfg6_Stat 1;
BA_ "FlexKomSigStartValue" SG_ 1021 EC_BU_ECUCfg6_Stat "03h";
BA_ "FlexKomSigStartPos" SG_ 1021 EC_BU_ECUCfg6_Stat 1;
BA_ "FlexKomSigName" SG_ 1021 EC_BU_ECUCfg6_Stat "EC_BU_ECUCfg6_Stat";
BA_ "FlexKomSigLaenge" SG_ 1021 EC_BU_ECUCfg6_Stat 2;
BA_ "FlexKomSID" SG_ 1021 EC_BU_ECUCfg6_Stat 1069;
BA_ "FlexKomIsMotorola" SG_ 1021 EC_BU_ECUCfg6_Stat 1;
BA_ "FlexKomComment" SG_ 1021 EC_BU_ECUCfg6_Stat "Backup for ECU Configuration messages status 6";
BA_ "GenSigSNA" SG_ 1021 EC_BU_Powertrain "0h";
BA_ "GenSigSendType" SG_ 1021 EC_BU_Powertrain 1;
BA_ "FlexKomSigStartValue" SG_ 1021 EC_BU_Powertrain "0000h";
BA_ "FlexKomSigStartPos" SG_ 1021 EC_BU_Powertrain 39;
BA_ "FlexKomSigName" SG_ 1021 EC_BU_Powertrain "EC_BU_Powertrain";
BA_ "FlexKomSigLaenge" SG_ 1021 EC_BU_Powertrain 16;
BA_ "FlexKomSID" SG_ 1021 EC_BU_Powertrain 917;
BA_ "FlexKomIsMotorola" SG_ 1021 EC_BU_Powertrain 1;
BA_ "FlexKomComment" SG_ 1021 EC_BU_Powertrain "Backup for Powertrain ecu configuration";
BA_ "GenSigSNA" SG_ 1021 EC_BU_Safety "0h";
BA_ "GenSigSendType" SG_ 1021 EC_BU_Safety 1;
BA_ "FlexKomSigStartValue" SG_ 1021 EC_BU_Safety "0000h";
BA_ "FlexKomSigStartPos" SG_ 1021 EC_BU_Safety 55;
BA_ "FlexKomSigName" SG_ 1021 EC_BU_Safety "EC_BU_Safety";
BA_ "FlexKomSigLaenge" SG_ 1021 EC_BU_Safety 16;
BA_ "FlexKomSID" SG_ 1021 EC_BU_Safety 918;
BA_ "FlexKomIsMotorola" SG_ 1021 EC_BU_Safety 1;
BA_ "FlexKomComment" SG_ 1021 EC_BU_Safety "Backup for Safety ecu configuration";
BA_ "GenSigSNA" SG_ 1021 EC_BU_Steering "0h";
BA_ "GenSigSendType" SG_ 1021 EC_BU_Steering 1;
BA_ "FlexKomSigStartValue" SG_ 1021 EC_BU_Steering "0000h";
BA_ "FlexKomSigStartPos" SG_ 1021 EC_BU_Steering 23;
BA_ "FlexKomSigName" SG_ 1021 EC_BU_Steering "EC_BU_Steering";
BA_ "FlexKomSigLaenge" SG_ 1021 EC_BU_Steering 16;
BA_ "FlexKomSID" SG_ 1021 EC_BU_Steering 1981;
BA_ "FlexKomIsMotorola" SG_ 1021 EC_BU_Steering 1;
BA_ "FlexKomComment" SG_ 1021 EC_BU_Steering "Backup for steering ecu configuration";
BA_ "GenSigSNA" SG_ 1022 EC_BU_CBC5A "0h";
BA_ "GenSigSendType" SG_ 1022 EC_BU_CBC5A 1;
BA_ "FlexKomSigStartValue" SG_ 1022 EC_BU_CBC5A "00000000h";
BA_ "FlexKomSigStartPos" SG_ 1022 EC_BU_CBC5A 7;
BA_ "FlexKomSigName" SG_ 1022 EC_BU_CBC5A "EC_BU_CBC5";
BA_ "FlexKomSigLaenge" SG_ 1022 EC_BU_CBC5A 32;
BA_ "FlexKomSID" SG_ 1022 EC_BU_CBC5A 1099;
BA_ "FlexKomIsMotorola" SG_ 1022 EC_BU_CBC5A 1;
BA_ "FlexKomComment" SG_ 1022 EC_BU_CBC5A "Backup for CBC ecu configuration 5";
BA_ "GenSigSNA" SG_ 1022 EC_BU_CBC5B "0h";
BA_ "GenSigSendType" SG_ 1022 EC_BU_CBC5B 1;
BA_ "FlexKomSigStartValue" SG_ 1022 EC_BU_CBC5B "00000000h";
BA_ "FlexKomSigStartPos" SG_ 1022 EC_BU_CBC5B 7;
BA_ "FlexKomSigName" SG_ 1022 EC_BU_CBC5B "EC_BU_CBC5";
BA_ "FlexKomSigLaenge" SG_ 1022 EC_BU_CBC5B 32;
BA_ "FlexKomSID" SG_ 1022 EC_BU_CBC5B 1099;
BA_ "FlexKomIsMotorola" SG_ 1022 EC_BU_CBC5B 1;
BA_ "FlexKomComment" SG_ 1022 EC_BU_CBC5B "Backup for CBC ecu configuration 5";
BA_ "GenSigSNA" SG_ 1022 EC_BU_CBC6 "0h";
BA_ "GenSigSendType" SG_ 1022 EC_BU_CBC6 1;
BA_ "FlexKomSigStartValue" SG_ 1022 EC_BU_CBC6 "00000000h";
BA_ "FlexKomSigStartPos" SG_ 1022 EC_BU_CBC6 39;
BA_ "FlexKomSigName" SG_ 1022 EC_BU_CBC6 "EC_BU_CBC6";
BA_ "FlexKomSigLaenge" SG_ 1022 EC_BU_CBC6 32;
BA_ "FlexKomSID" SG_ 1022 EC_BU_CBC6 1096;
BA_ "FlexKomIsMotorola" SG_ 1022 EC_BU_CBC6 1;
BA_ "FlexKomComment" SG_ 1022 EC_BU_CBC6 "Backup for CBC ecu configuration 6";
BA_ "GenSigStartValue" SG_ 1022 EC_BU_ECUCfg7_Stat 3;
BA_ "GenSigSNA" SG_ 1022 EC_BU_ECUCfg7_Stat "3h";
BA_ "GenSigSendType" SG_ 1022 EC_BU_ECUCfg7_Stat 1;
BA_ "FlexKomSigStartValue" SG_ 1022 EC_BU_ECUCfg7_Stat "03h";
BA_ "FlexKomSigStartPos" SG_ 1022 EC_BU_ECUCfg7_Stat 1;
BA_ "FlexKomSigName" SG_ 1022 EC_BU_ECUCfg7_Stat "EC_BU_ECUCfg7_Stat";
BA_ "FlexKomSigLaenge" SG_ 1022 EC_BU_ECUCfg7_Stat 2;
BA_ "FlexKomSID" SG_ 1022 EC_BU_ECUCfg7_Stat 1097;
BA_ "FlexKomIsMotorola" SG_ 1022 EC_BU_ECUCfg7_Stat 1;
BA_ "FlexKomComment" SG_ 1022 EC_BU_ECUCfg7_Stat "Backup for ECU Configuration messages status 7";
BA_ "GenSigSNA" SG_ 1023 EC_BU_CBC7A "0h";
BA_ "GenSigSendType" SG_ 1023 EC_BU_CBC7A 1;
BA_ "FlexKomSigStartValue" SG_ 1023 EC_BU_CBC7A "00000000h";
BA_ "FlexKomSigStartPos" SG_ 1023 EC_BU_CBC7A 7;
BA_ "FlexKomSigName" SG_ 1023 EC_BU_CBC7A "EC_BU_CBC7";
BA_ "FlexKomSigLaenge" SG_ 1023 EC_BU_CBC7A 32;
BA_ "FlexKomSID" SG_ 1023 EC_BU_CBC7A 1100;
BA_ "FlexKomIsMotorola" SG_ 1023 EC_BU_CBC7A 1;
BA_ "FlexKomComment" SG_ 1023 EC_BU_CBC7A "Backup for CBC ecu configuration 7";
BA_ "GenSigSNA" SG_ 1023 EC_BU_CBC7B "0h";
BA_ "GenSigSendType" SG_ 1023 EC_BU_CBC7B 1;
BA_ "FlexKomSigStartValue" SG_ 1023 EC_BU_CBC7B "00000000h";
BA_ "FlexKomSigStartPos" SG_ 1023 EC_BU_CBC7B 7;
BA_ "FlexKomSigName" SG_ 1023 EC_BU_CBC7B "EC_BU_CBC7";
BA_ "FlexKomSigLaenge" SG_ 1023 EC_BU_CBC7B 32;
BA_ "FlexKomSID" SG_ 1023 EC_BU_CBC7B 1100;
BA_ "FlexKomIsMotorola" SG_ 1023 EC_BU_CBC7B 1;
BA_ "FlexKomComment" SG_ 1023 EC_BU_CBC7B "Backup for CBC ecu configuration 7";
BA_ "GenSigSNA" SG_ 1023 EC_BU_CBC8 "0h";
BA_ "GenSigSendType" SG_ 1023 EC_BU_CBC8 1;
BA_ "FlexKomSigStartValue" SG_ 1023 EC_BU_CBC8 "00000000h";
BA_ "FlexKomSigStartPos" SG_ 1023 EC_BU_CBC8 39;
BA_ "FlexKomSigName" SG_ 1023 EC_BU_CBC8 "EC_BU_CBC8";
BA_ "FlexKomSigLaenge" SG_ 1023 EC_BU_CBC8 32;
BA_ "FlexKomSID" SG_ 1023 EC_BU_CBC8 1095;
BA_ "FlexKomIsMotorola" SG_ 1023 EC_BU_CBC8 1;
BA_ "FlexKomComment" SG_ 1023 EC_BU_CBC8 "Backup for CBC ecu configuration 8";
BA_ "GenSigStartValue" SG_ 1023 EC_BU_ECUCfg8_Stat 3;
BA_ "GenSigSNA" SG_ 1023 EC_BU_ECUCfg8_Stat "3h";
BA_ "GenSigSendType" SG_ 1023 EC_BU_ECUCfg8_Stat 1;
BA_ "FlexKomSigStartValue" SG_ 1023 EC_BU_ECUCfg8_Stat "03h";
BA_ "FlexKomSigStartPos" SG_ 1023 EC_BU_ECUCfg8_Stat 1;
BA_ "FlexKomSigName" SG_ 1023 EC_BU_ECUCfg8_Stat "EC_BU_ECUCfg8_Stat";
BA_ "FlexKomSigLaenge" SG_ 1023 EC_BU_ECUCfg8_Stat 2;
BA_ "FlexKomSID" SG_ 1023 EC_BU_ECUCfg8_Stat 1098;
BA_ "FlexKomIsMotorola" SG_ 1023 EC_BU_ECUCfg8_Stat 1;
BA_ "FlexKomComment" SG_ 1023 EC_BU_ECUCfg8_Stat "Backup for ECU Configuration messages status 8";
BA_ "GenSigSNA" SG_ 991 EC_BU_CBC9A1 "0h";
BA_ "GenSigSendType" SG_ 991 EC_BU_CBC9A1 1;
BA_ "FlexKomSigStartValue" SG_ 991 EC_BU_CBC9A1 "00000000h";
BA_ "FlexKomSigStartPos" SG_ 991 EC_BU_CBC9A1 7;
BA_ "FlexKomSigName" SG_ 991 EC_BU_CBC9A1 "EC_BU_CBC9A";
BA_ "FlexKomSigLaenge" SG_ 991 EC_BU_CBC9A1 32;
BA_ "FlexKomSID" SG_ 991 EC_BU_CBC9A1 1419;
BA_ "FlexKomIsMotorola" SG_ 991 EC_BU_CBC9A1 1;
BA_ "FlexKomComment" SG_ 991 EC_BU_CBC9A1 "Backup for CBC configuration 9A";
BA_ "GenSigSNA" SG_ 991 EC_BU_CBC9A2 "0h";
BA_ "GenSigSendType" SG_ 991 EC_BU_CBC9A2 1;
BA_ "FlexKomSigStartValue" SG_ 991 EC_BU_CBC9A2 "00000000h";
BA_ "FlexKomSigStartPos" SG_ 991 EC_BU_CBC9A2 7;
BA_ "FlexKomSigName" SG_ 991 EC_BU_CBC9A2 "EC_BU_CBC9A";
BA_ "FlexKomSigLaenge" SG_ 991 EC_BU_CBC9A2 32;
BA_ "FlexKomSID" SG_ 991 EC_BU_CBC9A2 1419;
BA_ "FlexKomIsMotorola" SG_ 991 EC_BU_CBC9A2 1;
BA_ "FlexKomComment" SG_ 991 EC_BU_CBC9A2 "Backup for CBC configuration 9A";
BA_ "GenSigSNA" SG_ 991 EC_BU_CBC9B "0h";
BA_ "GenSigSendType" SG_ 991 EC_BU_CBC9B 1;
BA_ "FlexKomSigStartValue" SG_ 991 EC_BU_CBC9B "0000h";
BA_ "FlexKomSigStartPos" SG_ 991 EC_BU_CBC9B 39;
BA_ "FlexKomSigName" SG_ 991 EC_BU_CBC9B "EC_BU_CBC9B";
BA_ "FlexKomSigLaenge" SG_ 991 EC_BU_CBC9B 16;
BA_ "FlexKomSID" SG_ 991 EC_BU_CBC9B 1420;
BA_ "FlexKomIsMotorola" SG_ 991 EC_BU_CBC9B 1;
BA_ "FlexKomComment" SG_ 991 EC_BU_CBC9B "Backup for CBC configuration 9B";
BA_ "GenSigStartValue" SG_ 991 EC_BU_ECUCfg9_Stat 3;
BA_ "GenSigSNA" SG_ 991 EC_BU_ECUCfg9_Stat "3h";
BA_ "GenSigSendType" SG_ 991 EC_BU_ECUCfg9_Stat 1;
BA_ "FlexKomSigStartValue" SG_ 991 EC_BU_ECUCfg9_Stat "03h";
BA_ "FlexKomSigStartPos" SG_ 991 EC_BU_ECUCfg9_Stat 1;
BA_ "FlexKomSigName" SG_ 991 EC_BU_ECUCfg9_Stat "EC_BU_ECUCfg9_Stat";
BA_ "FlexKomSigLaenge" SG_ 991 EC_BU_ECUCfg9_Stat 2;
BA_ "FlexKomSID" SG_ 991 EC_BU_ECUCfg9_Stat 1216;
BA_ "FlexKomIsMotorola" SG_ 991 EC_BU_ECUCfg9_Stat 1;
BA_ "FlexKomComment" SG_ 991 EC_BU_ECUCfg9_Stat "Backup for ECU Configuration messages status 9";
BA_ "GenSigSNA" SG_ 991 EC_BU_ITM "0h";
BA_ "GenSigSendType" SG_ 991 EC_BU_ITM 1;
BA_ "FlexKomSigStartValue" SG_ 991 EC_BU_ITM "0000h";
BA_ "FlexKomSigStartPos" SG_ 991 EC_BU_ITM 55;
BA_ "FlexKomSigName" SG_ 991 EC_BU_ITM "EC_BU_ITM";
BA_ "FlexKomSigLaenge" SG_ 991 EC_BU_ITM 16;
BA_ "FlexKomSID" SG_ 991 EC_BU_ITM 1220;
BA_ "FlexKomIsMotorola" SG_ 991 EC_BU_ITM 1;
BA_ "FlexKomComment" SG_ 991 EC_BU_ITM "Backup for ITM ecu configuration";
BA_ "GenSigSNA" SG_ 1008 EC_CBC1A "0h";
BA_ "GenSigCycleTime" SG_ 1008 EC_CBC1A 2000;
BA_ "FlexKomSigStartValue" SG_ 1008 EC_CBC1A "00000000h";
BA_ "FlexKomSigStartPos" SG_ 1008 EC_CBC1A 7;
BA_ "FlexKomSigName" SG_ 1008 EC_CBC1A "EC_CBC1";
BA_ "FlexKomSigLaenge" SG_ 1008 EC_CBC1A 32;
BA_ "FlexKomSID" SG_ 1008 EC_CBC1A 899;
BA_ "FlexKomIsMotorola" SG_ 1008 EC_CBC1A 1;
BA_ "FlexKomComment" SG_ 1008 EC_CBC1A "CBC ecu configuration 1";
BA_ "GenSigSNA" SG_ 1008 EC_CBC1B "0h";
BA_ "GenSigCycleTime" SG_ 1008 EC_CBC1B 2000;
BA_ "FlexKomSigStartValue" SG_ 1008 EC_CBC1B "00000000h";
BA_ "FlexKomSigStartPos" SG_ 1008 EC_CBC1B 7;
BA_ "FlexKomSigName" SG_ 1008 EC_CBC1B "EC_CBC1";
BA_ "FlexKomSigLaenge" SG_ 1008 EC_CBC1B 32;
BA_ "FlexKomSID" SG_ 1008 EC_CBC1B 899;
BA_ "FlexKomIsMotorola" SG_ 1008 EC_CBC1B 1;
BA_ "FlexKomComment" SG_ 1008 EC_CBC1B "CBC ecu configuration 1";
BA_ "GenSigSNA" SG_ 1008 EC_CBC2 "0h";
BA_ "GenSigCycleTime" SG_ 1008 EC_CBC2 2000;
BA_ "FlexKomSigStartValue" SG_ 1008 EC_CBC2 "00000000h";
BA_ "FlexKomSigStartPos" SG_ 1008 EC_CBC2 39;
BA_ "FlexKomSigName" SG_ 1008 EC_CBC2 "EC_CBC2";
BA_ "FlexKomSigLaenge" SG_ 1008 EC_CBC2 32;
BA_ "FlexKomSID" SG_ 1008 EC_CBC2 900;
BA_ "FlexKomIsMotorola" SG_ 1008 EC_CBC2 1;
BA_ "FlexKomComment" SG_ 1008 EC_CBC2 "CBC ecu configuration 2";
BA_ "GenSigStartValue" SG_ 1008 EC_ECUCfg1_Stat 3;
BA_ "GenSigSNA" SG_ 1008 EC_ECUCfg1_Stat "3h";
BA_ "GenSigCycleTime" SG_ 1008 EC_ECUCfg1_Stat 2000;
BA_ "FlexKomSigStartValue" SG_ 1008 EC_ECUCfg1_Stat "03h";
BA_ "FlexKomSigStartPos" SG_ 1008 EC_ECUCfg1_Stat 1;
BA_ "FlexKomSigName" SG_ 1008 EC_ECUCfg1_Stat "EC_ECUCfg1_Stat";
BA_ "FlexKomSigLaenge" SG_ 1008 EC_ECUCfg1_Stat 2;
BA_ "FlexKomSID" SG_ 1008 EC_ECUCfg1_Stat 1058;
BA_ "FlexKomIsMotorola" SG_ 1008 EC_ECUCfg1_Stat 1;
BA_ "FlexKomComment" SG_ 1008 EC_ECUCfg1_Stat "ECU Configuration messages status 1";
BA_ "GenSigTimeout_IC" SG_ 983 EC_Cluster3A 21000;
BA_ "GenSigSNA" SG_ 983 EC_Cluster3A "0h";
BA_ "GenSigSendType" SG_ 983 EC_Cluster3A 5;
BA_ "GenSigCycleTime" SG_ 983 EC_Cluster3A 2000;
BA_ "FlexKomSigStartValue" SG_ 983 EC_Cluster3A "00000000h";
BA_ "FlexKomSigStartPos" SG_ 983 EC_Cluster3A 7;
BA_ "FlexKomSigName" SG_ 983 EC_Cluster3A "EC_Cluster3";
BA_ "FlexKomSigLaenge" SG_ 983 EC_Cluster3A 32;
BA_ "FlexKomSID" SG_ 983 EC_Cluster3A 1307;
BA_ "FlexKomIsMotorola" SG_ 983 EC_Cluster3A 1;
BA_ "FlexKomComment" SG_ 983 EC_Cluster3A "Instrument cluster ecu configuration 3";
BA_ "GenSigTimeout_IC" SG_ 983 EC_Cluster3B 21000;
BA_ "GenSigSNA" SG_ 983 EC_Cluster3B "0h";
BA_ "GenSigSendType" SG_ 983 EC_Cluster3B 5;
BA_ "GenSigCycleTime" SG_ 983 EC_Cluster3B 2000;
BA_ "FlexKomSigStartValue" SG_ 983 EC_Cluster3B "00000000h";
BA_ "FlexKomSigStartPos" SG_ 983 EC_Cluster3B 7;
BA_ "FlexKomSigName" SG_ 983 EC_Cluster3B "EC_Cluster3";
BA_ "FlexKomSigLaenge" SG_ 983 EC_Cluster3B 32;
BA_ "FlexKomSID" SG_ 983 EC_Cluster3B 1307;
BA_ "FlexKomIsMotorola" SG_ 983 EC_Cluster3B 1;
BA_ "FlexKomComment" SG_ 983 EC_Cluster3B "Instrument cluster ecu configuration 3";
BA_ "GenSigTimeout_IC" SG_ 983 EC_Cluster4 21000;
BA_ "GenSigSNA" SG_ 983 EC_Cluster4 "0h";
BA_ "GenSigSendType" SG_ 983 EC_Cluster4 5;
BA_ "GenSigCycleTime" SG_ 983 EC_Cluster4 2000;
BA_ "FlexKomSigStartValue" SG_ 983 EC_Cluster4 "00000000h";
BA_ "FlexKomSigStartPos" SG_ 983 EC_Cluster4 39;
BA_ "FlexKomSigName" SG_ 983 EC_Cluster4 "EC_Cluster4";
BA_ "FlexKomSigLaenge" SG_ 983 EC_Cluster4 32;
BA_ "FlexKomSID" SG_ 983 EC_Cluster4 1306;
BA_ "FlexKomIsMotorola" SG_ 983 EC_Cluster4 1;
BA_ "FlexKomComment" SG_ 983 EC_Cluster4 "Instrument cluster ecu configuration 4";
BA_ "GenSigTimeout_IC" SG_ 983 EC_ECUCfg10_Stat 21000;
BA_ "GenSigStartValue" SG_ 983 EC_ECUCfg10_Stat 3;
BA_ "GenSigSNA" SG_ 983 EC_ECUCfg10_Stat "3h";
BA_ "GenSigSendType" SG_ 983 EC_ECUCfg10_Stat 5;
BA_ "GenSigCycleTime" SG_ 983 EC_ECUCfg10_Stat 2000;
BA_ "FlexKomSigStartValue" SG_ 983 EC_ECUCfg10_Stat "03h";
BA_ "FlexKomSigStartPos" SG_ 983 EC_ECUCfg10_Stat 1;
BA_ "FlexKomSigName" SG_ 983 EC_ECUCfg10_Stat "EC_ECUCfg10_Stat";
BA_ "FlexKomSigLaenge" SG_ 983 EC_ECUCfg10_Stat 2;
BA_ "FlexKomSID" SG_ 983 EC_ECUCfg10_Stat 1303;
BA_ "FlexKomIsMotorola" SG_ 983 EC_ECUCfg10_Stat 1;
BA_ "FlexKomComment" SG_ 983 EC_ECUCfg10_Stat "ECU Configuration messages status 10";
BA_ "GenSigSNA" SG_ 982 EC_CBC10A "0h";
BA_ "GenSigCycleTime" SG_ 982 EC_CBC10A 2000;
BA_ "FlexKomSigStartValue" SG_ 982 EC_CBC10A "00000000h";
BA_ "FlexKomSigStartPos" SG_ 982 EC_CBC10A 7;
BA_ "FlexKomSigName" SG_ 982 EC_CBC10A "EC_CBC10";
BA_ "FlexKomSigLaenge" SG_ 982 EC_CBC10A 32;
BA_ "FlexKomSID" SG_ 982 EC_CBC10A 1709;
BA_ "FlexKomIsMotorola" SG_ 982 EC_CBC10A 1;
BA_ "FlexKomComment" SG_ 982 EC_CBC10A "CBC ecu configuration 10";
BA_ "GenSigSNA" SG_ 982 EC_CBC10B "0h";
BA_ "GenSigCycleTime" SG_ 982 EC_CBC10B 2000;
BA_ "FlexKomSigStartValue" SG_ 982 EC_CBC10B "00000000h";
BA_ "FlexKomSigStartPos" SG_ 982 EC_CBC10B 7;
BA_ "FlexKomSigName" SG_ 982 EC_CBC10B "EC_CBC10";
BA_ "FlexKomSigLaenge" SG_ 982 EC_CBC10B 32;
BA_ "FlexKomSID" SG_ 982 EC_CBC10B 1709;
BA_ "FlexKomIsMotorola" SG_ 982 EC_CBC10B 1;
BA_ "FlexKomComment" SG_ 982 EC_CBC10B "CBC ecu configuration 10";
BA_ "GenSigSNA" SG_ 982 EC_CBC11 "0h";
BA_ "GenSigCycleTime" SG_ 982 EC_CBC11 2000;
BA_ "FlexKomSigStartValue" SG_ 982 EC_CBC11 "00000000h";
BA_ "FlexKomSigStartPos" SG_ 982 EC_CBC11 39;
BA_ "FlexKomSigName" SG_ 982 EC_CBC11 "EC_CBC11";
BA_ "FlexKomSigLaenge" SG_ 982 EC_CBC11 32;
BA_ "FlexKomSID" SG_ 982 EC_CBC11 1710;
BA_ "FlexKomIsMotorola" SG_ 982 EC_CBC11 1;
BA_ "FlexKomComment" SG_ 982 EC_CBC11 "CBC ecu configuration 11";
BA_ "GenSigStartValue" SG_ 982 EC_ECUCfg11_Stat 3;
BA_ "GenSigSNA" SG_ 982 EC_ECUCfg11_Stat "3h";
BA_ "GenSigCycleTime" SG_ 982 EC_ECUCfg11_Stat 2000;
BA_ "FlexKomSigStartValue" SG_ 982 EC_ECUCfg11_Stat "03h";
BA_ "FlexKomSigStartPos" SG_ 982 EC_ECUCfg11_Stat 1;
BA_ "FlexKomSigName" SG_ 982 EC_ECUCfg11_Stat "EC_ECUCfg11_Stat";
BA_ "FlexKomSigLaenge" SG_ 982 EC_ECUCfg11_Stat 2;
BA_ "FlexKomSID" SG_ 982 EC_ECUCfg11_Stat 1708;
BA_ "FlexKomIsMotorola" SG_ 982 EC_ECUCfg11_Stat 1;
BA_ "FlexKomComment" SG_ 982 EC_ECUCfg11_Stat "ECU Configuration messages status 11";
BA_ "GenSigTimeout_RF_HUB" SG_ 981 EC_Cluster5A 21000;
BA_ "GenSigTimeout_IC" SG_ 981 EC_Cluster5A 21000;
BA_ "GenSigSNA" SG_ 981 EC_Cluster5A "0h";
BA_ "GenSigSendType" SG_ 981 EC_Cluster5A 5;
BA_ "GenSigCycleTime" SG_ 981 EC_Cluster5A 2000;
BA_ "FlexKomSigStartValue" SG_ 981 EC_Cluster5A "0000000000000000h";
BA_ "FlexKomSigStartPos" SG_ 981 EC_Cluster5A 7;
BA_ "FlexKomSigName" SG_ 981 EC_Cluster5A "EC_Cluster5";
BA_ "FlexKomSigLaenge" SG_ 981 EC_Cluster5A 64;
BA_ "FlexKomSID" SG_ 981 EC_Cluster5A 1835;
BA_ "FlexKomIsMotorola" SG_ 981 EC_Cluster5A 1;
BA_ "FlexKomComment" SG_ 981 EC_Cluster5A "Instrument cluster ecu configuration 5";
BA_ "GenSigTimeout_RF_HUB" SG_ 981 EC_Cluster5B 21000;
BA_ "GenSigTimeout_IC" SG_ 981 EC_Cluster5B 21000;
BA_ "GenSigSNA" SG_ 981 EC_Cluster5B "0h";
BA_ "GenSigSendType" SG_ 981 EC_Cluster5B 5;
BA_ "GenSigCycleTime" SG_ 981 EC_Cluster5B 2000;
BA_ "FlexKomSigStartValue" SG_ 981 EC_Cluster5B "0000000000000000h";
BA_ "FlexKomSigStartPos" SG_ 981 EC_Cluster5B 7;
BA_ "FlexKomSigName" SG_ 981 EC_Cluster5B "EC_Cluster5";
BA_ "FlexKomSigLaenge" SG_ 981 EC_Cluster5B 64;
BA_ "FlexKomSID" SG_ 981 EC_Cluster5B 1835;
BA_ "FlexKomIsMotorola" SG_ 981 EC_Cluster5B 1;
BA_ "FlexKomComment" SG_ 981 EC_Cluster5B "Instrument cluster ecu configuration 5";
BA_ "GenSigTimeout_RF_HUB" SG_ 981 EC_Cluster5C 21000;
BA_ "GenSigTimeout_IC" SG_ 981 EC_Cluster5C 21000;
BA_ "GenSigSNA" SG_ 981 EC_Cluster5C "0h";
BA_ "GenSigSendType" SG_ 981 EC_Cluster5C 5;
BA_ "GenSigCycleTime" SG_ 981 EC_Cluster5C 2000;
BA_ "FlexKomSigStartValue" SG_ 981 EC_Cluster5C "0000000000000000h";
BA_ "FlexKomSigStartPos" SG_ 981 EC_Cluster5C 7;
BA_ "FlexKomSigName" SG_ 981 EC_Cluster5C "EC_Cluster5";
BA_ "FlexKomSigLaenge" SG_ 981 EC_Cluster5C 64;
BA_ "FlexKomSID" SG_ 981 EC_Cluster5C 1835;
BA_ "FlexKomIsMotorola" SG_ 981 EC_Cluster5C 1;
BA_ "FlexKomComment" SG_ 981 EC_Cluster5C "Instrument cluster ecu configuration 5";
BA_ "GenSigTimeout_RF_HUB" SG_ 981 EC_ECUCfg12_Stat 21000;
BA_ "GenSigTimeout_IC" SG_ 981 EC_ECUCfg12_Stat 21000;
BA_ "GenSigStartValue" SG_ 981 EC_ECUCfg12_Stat 3;
BA_ "GenSigSNA" SG_ 981 EC_ECUCfg12_Stat "3h";
BA_ "GenSigSendType" SG_ 981 EC_ECUCfg12_Stat 5;
BA_ "GenSigCycleTime" SG_ 981 EC_ECUCfg12_Stat 2000;
BA_ "FlexKomSigStartValue" SG_ 981 EC_ECUCfg12_Stat "03h";
BA_ "FlexKomSigStartPos" SG_ 981 EC_ECUCfg12_Stat 1;
BA_ "FlexKomSigName" SG_ 981 EC_ECUCfg12_Stat "EC_ECUCfg12_Stat";
BA_ "FlexKomSigLaenge" SG_ 981 EC_ECUCfg12_Stat 2;
BA_ "FlexKomSID" SG_ 981 EC_ECUCfg12_Stat 1834;
BA_ "FlexKomIsMotorola" SG_ 981 EC_ECUCfg12_Stat 1;
BA_ "FlexKomComment" SG_ 981 EC_ECUCfg12_Stat "ECU Configuration messages status 12";
BA_ "GenSigSNA" SG_ 980 EC_CBC13A "0h";
BA_ "GenSigCycleTime" SG_ 980 EC_CBC13A 2000;
BA_ "FlexKomSigStartValue" SG_ 980 EC_CBC13A "0000000000000000h";
BA_ "FlexKomSigStartPos" SG_ 980 EC_CBC13A 7;
BA_ "FlexKomSigName" SG_ 980 EC_CBC13A "EC_CBC13";
BA_ "FlexKomSigLaenge" SG_ 980 EC_CBC13A 64;
BA_ "FlexKomSID" SG_ 980 EC_CBC13A 1990;
BA_ "FlexKomIsMotorola" SG_ 980 EC_CBC13A 1;
BA_ "FlexKomComment" SG_ 980 EC_CBC13A "CBC ecu configuration 13";
BA_ "GenSigSNA" SG_ 980 EC_CBC13B "0h";
BA_ "GenSigCycleTime" SG_ 980 EC_CBC13B 2000;
BA_ "FlexKomSigStartValue" SG_ 980 EC_CBC13B "0000000000000000h";
BA_ "FlexKomSigStartPos" SG_ 980 EC_CBC13B 7;
BA_ "FlexKomSigName" SG_ 980 EC_CBC13B "EC_CBC13";
BA_ "FlexKomSigLaenge" SG_ 980 EC_CBC13B 64;
BA_ "FlexKomSID" SG_ 980 EC_CBC13B 1990;
BA_ "FlexKomIsMotorola" SG_ 980 EC_CBC13B 1;
BA_ "FlexKomComment" SG_ 980 EC_CBC13B "CBC ecu configuration 13";
BA_ "GenSigStartValue" SG_ 980 EC_ECUCfg13_Stat 3;
BA_ "GenSigSNA" SG_ 980 EC_ECUCfg13_Stat "3h";
BA_ "GenSigCycleTime" SG_ 980 EC_ECUCfg13_Stat 2000;
BA_ "FlexKomSigStartValue" SG_ 980 EC_ECUCfg13_Stat "03h";
BA_ "FlexKomSigStartPos" SG_ 980 EC_ECUCfg13_Stat 1;
BA_ "FlexKomSigName" SG_ 980 EC_ECUCfg13_Stat "EC_ECUCfg13_Stat";
BA_ "FlexKomSigLaenge" SG_ 980 EC_ECUCfg13_Stat 2;
BA_ "FlexKomSID" SG_ 980 EC_ECUCfg13_Stat 1868;
BA_ "FlexKomIsMotorola" SG_ 980 EC_ECUCfg13_Stat 1;
BA_ "FlexKomComment" SG_ 980 EC_ECUCfg13_Stat "ECU Configuration messages status 13";
BA_ "GenSigSNA" SG_ 979 EC_CBC14A "0h";
BA_ "GenSigCycleTime" SG_ 979 EC_CBC14A 2000;
BA_ "FlexKomSigStartValue" SG_ 979 EC_CBC14A "0000000000000000h";
BA_ "FlexKomSigStartPos" SG_ 979 EC_CBC14A 7;
BA_ "FlexKomSigName" SG_ 979 EC_CBC14A "EC_CBC14";
BA_ "FlexKomSigLaenge" SG_ 979 EC_CBC14A 64;
BA_ "FlexKomSID" SG_ 979 EC_CBC14A 1951;
BA_ "FlexKomIsMotorola" SG_ 979 EC_CBC14A 1;
BA_ "FlexKomComment" SG_ 979 EC_CBC14A "CBC ecu configuration 14";
BA_ "GenSigSNA" SG_ 979 EC_CBC14B "0h";
BA_ "GenSigCycleTime" SG_ 979 EC_CBC14B 2000;
BA_ "FlexKomSigStartValue" SG_ 979 EC_CBC14B "0000000000000000h";
BA_ "FlexKomSigStartPos" SG_ 979 EC_CBC14B 7;
BA_ "FlexKomSigName" SG_ 979 EC_CBC14B "EC_CBC14";
BA_ "FlexKomSigLaenge" SG_ 979 EC_CBC14B 64;
BA_ "FlexKomSID" SG_ 979 EC_CBC14B 1951;
BA_ "FlexKomIsMotorola" SG_ 979 EC_CBC14B 1;
BA_ "FlexKomComment" SG_ 979 EC_CBC14B "CBC ecu configuration 14";
BA_ "GenSigStartValue" SG_ 979 EC_ECUCfg14_Stat 3;
BA_ "GenSigSNA" SG_ 979 EC_ECUCfg14_Stat "3h";
BA_ "GenSigCycleTime" SG_ 979 EC_ECUCfg14_Stat 2000;
BA_ "FlexKomSigStartValue" SG_ 979 EC_ECUCfg14_Stat "03h";
BA_ "FlexKomSigStartPos" SG_ 979 EC_ECUCfg14_Stat 1;
BA_ "FlexKomSigName" SG_ 979 EC_ECUCfg14_Stat "EC_ECUCfg14_Stat";
BA_ "FlexKomSigLaenge" SG_ 979 EC_ECUCfg14_Stat 2;
BA_ "FlexKomSID" SG_ 979 EC_ECUCfg14_Stat 1950;
BA_ "FlexKomIsMotorola" SG_ 979 EC_ECUCfg14_Stat 1;
BA_ "FlexKomComment" SG_ 979 EC_ECUCfg14_Stat "ECU Configuration messages status 14";
BA_ "GenSigSNA" SG_ 706 EC_CBC15A "0h";
BA_ "GenSigSendType" SG_ 706 EC_CBC15A 5;
BA_ "GenSigCycleTime" SG_ 706 EC_CBC15A 2000;
BA_ "FlexKomSigStartValue" SG_ 706 EC_CBC15A "000000000000h";
BA_ "FlexKomSigStartPos" SG_ 706 EC_CBC15A 7;
BA_ "FlexKomSigName" SG_ 706 EC_CBC15A "EC_CBC15";
BA_ "FlexKomSigLaenge" SG_ 706 EC_CBC15A 48;
BA_ "FlexKomSID" SG_ 706 EC_CBC15A 2072;
BA_ "FlexKomIsMotorola" SG_ 706 EC_CBC15A 1;
BA_ "FlexKomComment" SG_ 706 EC_CBC15A "CBC ecu configuration 15";
BA_ "GenSigSNA" SG_ 706 EC_CBC15B "0h";
BA_ "GenSigSendType" SG_ 706 EC_CBC15B 5;
BA_ "GenSigCycleTime" SG_ 706 EC_CBC15B 2000;
BA_ "FlexKomSigStartValue" SG_ 706 EC_CBC15B "000000000000h";
BA_ "FlexKomSigStartPos" SG_ 706 EC_CBC15B 7;
BA_ "FlexKomSigName" SG_ 706 EC_CBC15B "EC_CBC15";
BA_ "FlexKomSigLaenge" SG_ 706 EC_CBC15B 48;
BA_ "FlexKomSID" SG_ 706 EC_CBC15B 2072;
BA_ "FlexKomIsMotorola" SG_ 706 EC_CBC15B 1;
BA_ "FlexKomComment" SG_ 706 EC_CBC15B "CBC ecu configuration 15";
BA_ "GenSigStartValue" SG_ 706 EC_ECUCfg15_Stat 3;
BA_ "GenSigSNA" SG_ 706 EC_ECUCfg15_Stat "3h";
BA_ "GenSigSendType" SG_ 706 EC_ECUCfg15_Stat 5;
BA_ "GenSigCycleTime" SG_ 706 EC_ECUCfg15_Stat 2000;
BA_ "FlexKomSigStartValue" SG_ 706 EC_ECUCfg15_Stat "03h";
BA_ "FlexKomSigStartPos" SG_ 706 EC_ECUCfg15_Stat 1;
BA_ "FlexKomSigName" SG_ 706 EC_ECUCfg15_Stat "EC_ECUCfg15_Stat";
BA_ "FlexKomSigLaenge" SG_ 706 EC_ECUCfg15_Stat 2;
BA_ "FlexKomSID" SG_ 706 EC_ECUCfg15_Stat 2071;
BA_ "FlexKomIsMotorola" SG_ 706 EC_ECUCfg15_Stat 1;
BA_ "FlexKomComment" SG_ 706 EC_ECUCfg15_Stat "ECU Configuration messages status 15";
BA_ "GenSigSNA" SG_ 706 EC_Suspension "0h";
BA_ "GenSigSendType" SG_ 706 EC_Suspension 5;
BA_ "GenSigCycleTime" SG_ 706 EC_Suspension 2000;
BA_ "FlexKomSigStartValue" SG_ 706 EC_Suspension "0000h";
BA_ "FlexKomSigStartPos" SG_ 706 EC_Suspension 55;
BA_ "FlexKomSigName" SG_ 706 EC_Suspension "EC_Suspension";
BA_ "FlexKomSigLaenge" SG_ 706 EC_Suspension 16;
BA_ "FlexKomSID" SG_ 706 EC_Suspension 891;
BA_ "FlexKomIsMotorola" SG_ 706 EC_Suspension 1;
BA_ "FlexKomComment" SG_ 706 EC_Suspension "Suspension ecu configuration";
BA_ "GenSigSNA" SG_ 709 EC_AudTel3A "0h";
BA_ "GenSigSendType" SG_ 709 EC_AudTel3A 5;
BA_ "GenSigCycleTime" SG_ 709 EC_AudTel3A 2000;
BA_ "FlexKomSigStartValue" SG_ 709 EC_AudTel3A "0000000000000000h";
BA_ "FlexKomSigStartPos" SG_ 709 EC_AudTel3A 7;
BA_ "FlexKomSigName" SG_ 709 EC_AudTel3A "EC_AudTel3";
BA_ "FlexKomSigLaenge" SG_ 709 EC_AudTel3A 64;
BA_ "FlexKomSID" SG_ 709 EC_AudTel3A 2288;
BA_ "FlexKomIsMotorola" SG_ 709 EC_AudTel3A 1;
BA_ "FlexKomComment" SG_ 709 EC_AudTel3A "Audio and telematics ecu configuration 3";
BA_ "GenSigSNA" SG_ 709 EC_AudTel3B "0h";
BA_ "GenSigSendType" SG_ 709 EC_AudTel3B 5;
BA_ "GenSigCycleTime" SG_ 709 EC_AudTel3B 2000;
BA_ "FlexKomSigStartValue" SG_ 709 EC_AudTel3B "0000000000000000h";
BA_ "FlexKomSigStartPos" SG_ 709 EC_AudTel3B 7;
BA_ "FlexKomSigName" SG_ 709 EC_AudTel3B "EC_AudTel3";
BA_ "FlexKomSigLaenge" SG_ 709 EC_AudTel3B 64;
BA_ "FlexKomSID" SG_ 709 EC_AudTel3B 2288;
BA_ "FlexKomIsMotorola" SG_ 709 EC_AudTel3B 1;
BA_ "FlexKomComment" SG_ 709 EC_AudTel3B "Audio and telematics ecu configuration 3";
BA_ "GenSigStartValue" SG_ 709 EC_ECUCfg16_Stat 3;
BA_ "GenSigSNA" SG_ 709 EC_ECUCfg16_Stat "3h";
BA_ "GenSigSendType" SG_ 709 EC_ECUCfg16_Stat 5;
BA_ "GenSigCycleTime" SG_ 709 EC_ECUCfg16_Stat 2000;
BA_ "FlexKomSigStartValue" SG_ 709 EC_ECUCfg16_Stat "03h";
BA_ "FlexKomSigStartPos" SG_ 709 EC_ECUCfg16_Stat 1;
BA_ "FlexKomSigName" SG_ 709 EC_ECUCfg16_Stat "EC_ECUCfg16_Stat";
BA_ "FlexKomSigLaenge" SG_ 709 EC_ECUCfg16_Stat 2;
BA_ "FlexKomSID" SG_ 709 EC_ECUCfg16_Stat 2286;
BA_ "FlexKomIsMotorola" SG_ 709 EC_ECUCfg16_Stat 1;
BA_ "FlexKomComment" SG_ 709 EC_ECUCfg16_Stat "ECU Configuration messages status 16";
BA_ "GenSigSendType" SG_ 710 EC_CBC17 5;
BA_ "GenSigCycleTime" SG_ 710 EC_CBC17 2000;
BA_ "FlexKomSigStartValue" SG_ 710 EC_CBC17 "0300000000000000h";
BA_ "FlexKomSigStartPos" SG_ 710 EC_CBC17 7;
BA_ "FlexKomSigName" SG_ 710 EC_CBC17 "EcuCfg17Pkt";
BA_ "FlexKomSigLaenge" SG_ 710 EC_CBC17 64;
BA_ "FlexKomSID" SG_ 710 EC_CBC17 2478;
BA_ "FlexKomIsMotorola" SG_ 710 EC_CBC17 1;
BA_ "FlexKomComment" SG_ 710 EC_CBC17 "ECU Configuration 17 packet";
BA_ "GenSigTimeout_PTS" SG_ 710 EC_ECUCfg17_Stat 21000;
BA_ "GenSigStartValue" SG_ 710 EC_ECUCfg17_Stat 3;
BA_ "GenSigSNA" SG_ 710 EC_ECUCfg17_Stat "3h";
BA_ "GenSigSendType" SG_ 710 EC_ECUCfg17_Stat 5;
BA_ "GenSigCycleTime" SG_ 710 EC_ECUCfg17_Stat 2000;
BA_ "FlexKomSigStartValue" SG_ 710 EC_ECUCfg17_Stat "0300000000000000h";
BA_ "FlexKomSigStartPos" SG_ 710 EC_ECUCfg17_Stat 7;
BA_ "FlexKomSigName" SG_ 710 EC_ECUCfg17_Stat "EcuCfg17Pkt";
BA_ "FlexKomSigLaenge" SG_ 710 EC_ECUCfg17_Stat 64;
BA_ "FlexKomSID" SG_ 710 EC_ECUCfg17_Stat 2478;
BA_ "FlexKomIsMotorola" SG_ 710 EC_ECUCfg17_Stat 1;
BA_ "FlexKomComment" SG_ 710 EC_ECUCfg17_Stat "ECU Configuration 17 packet";
BA_ "GenSigSNA" SG_ 710 EC_HVAC1 "0h";
BA_ "GenSigSendType" SG_ 710 EC_HVAC1 5;
BA_ "GenSigCycleTime" SG_ 710 EC_HVAC1 2000;
BA_ "FlexKomSigStartValue" SG_ 710 EC_HVAC1 "0300000000000000h";
BA_ "FlexKomSigStartPos" SG_ 710 EC_HVAC1 7;
BA_ "FlexKomSigName" SG_ 710 EC_HVAC1 "EcuCfg17Pkt";
BA_ "FlexKomSigLaenge" SG_ 710 EC_HVAC1 64;
BA_ "FlexKomSID" SG_ 710 EC_HVAC1 2478;
BA_ "FlexKomIsMotorola" SG_ 710 EC_HVAC1 1;
BA_ "FlexKomComment" SG_ 710 EC_HVAC1 "ECU Configuration 17 packet";
BA_ "GenSigSNA" SG_ 710 EC_HVAC2 "0h";
BA_ "GenSigSendType" SG_ 710 EC_HVAC2 5;
BA_ "GenSigCycleTime" SG_ 710 EC_HVAC2 2000;
BA_ "FlexKomSigStartValue" SG_ 710 EC_HVAC2 "0300000000000000h";
BA_ "FlexKomSigStartPos" SG_ 710 EC_HVAC2 7;
BA_ "FlexKomSigName" SG_ 710 EC_HVAC2 "EcuCfg17Pkt";
BA_ "FlexKomSigLaenge" SG_ 710 EC_HVAC2 64;
BA_ "FlexKomSID" SG_ 710 EC_HVAC2 2478;
BA_ "FlexKomIsMotorola" SG_ 710 EC_HVAC2 1;
BA_ "FlexKomComment" SG_ 710 EC_HVAC2 "ECU Configuration 17 packet";
BA_ "GenSigTimeout_PTS" SG_ 710 EC_PTS 21000;
BA_ "GenSigSNA" SG_ 710 EC_PTS "0h";
BA_ "GenSigSendType" SG_ 710 EC_PTS 5;
BA_ "GenSigCycleTime" SG_ 710 EC_PTS 2000;
BA_ "FlexKomSigStartValue" SG_ 710 EC_PTS "0300000000000000h";
BA_ "FlexKomSigStartPos" SG_ 710 EC_PTS 7;
BA_ "FlexKomSigName" SG_ 710 EC_PTS "EcuCfg17Pkt";
BA_ "FlexKomSigLaenge" SG_ 710 EC_PTS 64;
BA_ "FlexKomSID" SG_ 710 EC_PTS 2478;
BA_ "FlexKomIsMotorola" SG_ 710 EC_PTS 1;
BA_ "FlexKomComment" SG_ 710 EC_PTS "ECU Configuration 17 packet";
BA_ "GenSigSNA" SG_ 710 EC_SeatsA "0h";
BA_ "GenSigSendType" SG_ 710 EC_SeatsA 5;
BA_ "GenSigCycleTime" SG_ 710 EC_SeatsA 2000;
BA_ "FlexKomSigStartValue" SG_ 710 EC_SeatsA "0300000000000000h";
BA_ "FlexKomSigStartPos" SG_ 710 EC_SeatsA 7;
BA_ "FlexKomSigName" SG_ 710 EC_SeatsA "EcuCfg17Pkt";
BA_ "FlexKomSigLaenge" SG_ 710 EC_SeatsA 64;
BA_ "FlexKomSID" SG_ 710 EC_SeatsA 2478;
BA_ "FlexKomIsMotorola" SG_ 710 EC_SeatsA 1;
BA_ "FlexKomComment" SG_ 710 EC_SeatsA "ECU Configuration 17 packet";
BA_ "GenSigSNA" SG_ 710 EC_SeatsB "0h";
BA_ "GenSigSendType" SG_ 710 EC_SeatsB 5;
BA_ "GenSigCycleTime" SG_ 710 EC_SeatsB 2000;
BA_ "FlexKomSigStartValue" SG_ 710 EC_SeatsB "0300000000000000h";
BA_ "FlexKomSigStartPos" SG_ 710 EC_SeatsB 7;
BA_ "FlexKomSigName" SG_ 710 EC_SeatsB "EcuCfg17Pkt";
BA_ "FlexKomSigLaenge" SG_ 710 EC_SeatsB 64;
BA_ "FlexKomSID" SG_ 710 EC_SeatsB 2478;
BA_ "FlexKomIsMotorola" SG_ 710 EC_SeatsB 1;
BA_ "FlexKomComment" SG_ 710 EC_SeatsB "ECU Configuration 17 packet";
BA_ "GenSigSNA" SG_ 711 EC_AudTel4A "0h";
BA_ "GenSigSendType" SG_ 711 EC_AudTel4A 5;
BA_ "GenSigCycleTime" SG_ 711 EC_AudTel4A 2000;
BA_ "FlexKomSigStartValue" SG_ 711 EC_AudTel4A "0300000000000000h";
BA_ "FlexKomSigStartPos" SG_ 711 EC_AudTel4A 7;
BA_ "FlexKomSigName" SG_ 711 EC_AudTel4A "EcuCfg18Pkt";
BA_ "FlexKomSigLaenge" SG_ 711 EC_AudTel4A 64;
BA_ "FlexKomSID" SG_ 711 EC_AudTel4A 3023;
BA_ "FlexKomIsMotorola" SG_ 711 EC_AudTel4A 1;
BA_ "FlexKomComment" SG_ 711 EC_AudTel4A "ECU Configuration 18 packet";
BA_ "GenSigSNA" SG_ 711 EC_AudTel4B "0h";
BA_ "GenSigSendType" SG_ 711 EC_AudTel4B 5;
BA_ "GenSigCycleTime" SG_ 711 EC_AudTel4B 2000;
BA_ "FlexKomSigStartValue" SG_ 711 EC_AudTel4B "0300000000000000h";
BA_ "FlexKomSigStartPos" SG_ 711 EC_AudTel4B 7;
BA_ "FlexKomSigName" SG_ 711 EC_AudTel4B "EcuCfg18Pkt";
BA_ "FlexKomSigLaenge" SG_ 711 EC_AudTel4B 64;
BA_ "FlexKomSID" SG_ 711 EC_AudTel4B 3023;
BA_ "FlexKomIsMotorola" SG_ 711 EC_AudTel4B 1;
BA_ "FlexKomComment" SG_ 711 EC_AudTel4B "ECU Configuration 18 packet";
BA_ "GenSigStartValue" SG_ 711 EC_ECUCfg18_Stat 3;
BA_ "GenSigSNA" SG_ 711 EC_ECUCfg18_Stat "3h";
BA_ "GenSigSendType" SG_ 711 EC_ECUCfg18_Stat 5;
BA_ "GenSigCycleTime" SG_ 711 EC_ECUCfg18_Stat 2000;
BA_ "FlexKomSigStartValue" SG_ 711 EC_ECUCfg18_Stat "0300000000000000h";
BA_ "FlexKomSigStartPos" SG_ 711 EC_ECUCfg18_Stat 7;
BA_ "FlexKomSigName" SG_ 711 EC_ECUCfg18_Stat "EcuCfg18Pkt";
BA_ "FlexKomSigLaenge" SG_ 711 EC_ECUCfg18_Stat 64;
BA_ "FlexKomSID" SG_ 711 EC_ECUCfg18_Stat 3023;
BA_ "FlexKomIsMotorola" SG_ 711 EC_ECUCfg18_Stat 1;
BA_ "FlexKomComment" SG_ 711 EC_ECUCfg18_Stat "ECU Configuration 18 packet";
BA_ "GenSigSNA" SG_ 1009 EC_CBC3A "0h";
BA_ "GenSigCycleTime" SG_ 1009 EC_CBC3A 2000;
BA_ "FlexKomSigStartValue" SG_ 1009 EC_CBC3A "00000000h";
BA_ "FlexKomSigStartPos" SG_ 1009 EC_CBC3A 7;
BA_ "FlexKomSigName" SG_ 1009 EC_CBC3A "EC_CBC3";
BA_ "FlexKomSigLaenge" SG_ 1009 EC_CBC3A 32;
BA_ "FlexKomSID" SG_ 1009 EC_CBC3A 901;
BA_ "FlexKomIsMotorola" SG_ 1009 EC_CBC3A 1;
BA_ "FlexKomComment" SG_ 1009 EC_CBC3A "CBC ecu configuration 3";
BA_ "GenSigSNA" SG_ 1009 EC_CBC3B "0h";
BA_ "GenSigCycleTime" SG_ 1009 EC_CBC3B 2000;
BA_ "FlexKomSigStartValue" SG_ 1009 EC_CBC3B "00000000h";
BA_ "FlexKomSigStartPos" SG_ 1009 EC_CBC3B 7;
BA_ "FlexKomSigName" SG_ 1009 EC_CBC3B "EC_CBC3";
BA_ "FlexKomSigLaenge" SG_ 1009 EC_CBC3B 32;
BA_ "FlexKomSID" SG_ 1009 EC_CBC3B 901;
BA_ "FlexKomIsMotorola" SG_ 1009 EC_CBC3B 1;
BA_ "FlexKomComment" SG_ 1009 EC_CBC3B "CBC ecu configuration 3";
BA_ "GenSigSNA" SG_ 1009 EC_CBC4 "0h";
BA_ "GenSigCycleTime" SG_ 1009 EC_CBC4 2000;
BA_ "FlexKomSigStartValue" SG_ 1009 EC_CBC4 "00000000h";
BA_ "FlexKomSigStartPos" SG_ 1009 EC_CBC4 39;
BA_ "FlexKomSigName" SG_ 1009 EC_CBC4 "EC_CBC4";
BA_ "FlexKomSigLaenge" SG_ 1009 EC_CBC4 32;
BA_ "FlexKomSID" SG_ 1009 EC_CBC4 902;
BA_ "FlexKomIsMotorola" SG_ 1009 EC_CBC4 1;
BA_ "FlexKomComment" SG_ 1009 EC_CBC4 "CBC ecu configuration 4";
BA_ "GenSigStartValue" SG_ 1009 EC_ECUCfg2_Stat 3;
BA_ "GenSigSNA" SG_ 1009 EC_ECUCfg2_Stat "3h";
BA_ "GenSigCycleTime" SG_ 1009 EC_ECUCfg2_Stat 2000;
BA_ "FlexKomSigStartValue" SG_ 1009 EC_ECUCfg2_Stat "03h";
BA_ "FlexKomSigStartPos" SG_ 1009 EC_ECUCfg2_Stat 1;
BA_ "FlexKomSigName" SG_ 1009 EC_ECUCfg2_Stat "EC_ECUCfg2_Stat";
BA_ "FlexKomSigLaenge" SG_ 1009 EC_ECUCfg2_Stat 2;
BA_ "FlexKomSID" SG_ 1009 EC_ECUCfg2_Stat 1059;
BA_ "FlexKomIsMotorola" SG_ 1009 EC_ECUCfg2_Stat 1;
BA_ "FlexKomComment" SG_ 1009 EC_ECUCfg2_Stat "ECU Configuration messages status 2";
BA_ "GenSigSNA" SG_ 1010 EC_AudTel1A "0h";
BA_ "GenSigSendType" SG_ 1010 EC_AudTel1A 5;
BA_ "GenSigCycleTime" SG_ 1010 EC_AudTel1A 2000;
BA_ "FlexKomSigStartValue" SG_ 1010 EC_AudTel1A "00000000h";
BA_ "FlexKomSigStartPos" SG_ 1010 EC_AudTel1A 7;
BA_ "FlexKomSigName" SG_ 1010 EC_AudTel1A "EC_AudTel1";
BA_ "FlexKomSigLaenge" SG_ 1010 EC_AudTel1A 32;
BA_ "FlexKomSID" SG_ 1010 EC_AudTel1A 897;
BA_ "FlexKomIsMotorola" SG_ 1010 EC_AudTel1A 1;
BA_ "FlexKomComment" SG_ 1010 EC_AudTel1A "Audio and telematics ecu configuration 1";
BA_ "GenSigSNA" SG_ 1010 EC_AudTel1B "0h";
BA_ "GenSigSendType" SG_ 1010 EC_AudTel1B 5;
BA_ "GenSigCycleTime" SG_ 1010 EC_AudTel1B 2000;
BA_ "FlexKomSigStartValue" SG_ 1010 EC_AudTel1B "00000000h";
BA_ "FlexKomSigStartPos" SG_ 1010 EC_AudTel1B 7;
BA_ "FlexKomSigName" SG_ 1010 EC_AudTel1B "EC_AudTel1";
BA_ "FlexKomSigLaenge" SG_ 1010 EC_AudTel1B 32;
BA_ "FlexKomSID" SG_ 1010 EC_AudTel1B 897;
BA_ "FlexKomIsMotorola" SG_ 1010 EC_AudTel1B 1;
BA_ "FlexKomComment" SG_ 1010 EC_AudTel1B "Audio and telematics ecu configuration 1";
BA_ "GenSigSNA" SG_ 1010 EC_AudTel2 "0h";
BA_ "GenSigSendType" SG_ 1010 EC_AudTel2 5;
BA_ "GenSigCycleTime" SG_ 1010 EC_AudTel2 2000;
BA_ "FlexKomSigStartValue" SG_ 1010 EC_AudTel2 "00000000h";
BA_ "FlexKomSigStartPos" SG_ 1010 EC_AudTel2 39;
BA_ "FlexKomSigName" SG_ 1010 EC_AudTel2 "EC_AudTel2";
BA_ "FlexKomSigLaenge" SG_ 1010 EC_AudTel2 32;
BA_ "FlexKomSID" SG_ 1010 EC_AudTel2 898;
BA_ "FlexKomIsMotorola" SG_ 1010 EC_AudTel2 1;
BA_ "FlexKomComment" SG_ 1010 EC_AudTel2 "Audio and telematics ecu configuration 2";
BA_ "GenSigStartValue" SG_ 1010 EC_ECUCfg3_Stat 3;
BA_ "GenSigSNA" SG_ 1010 EC_ECUCfg3_Stat "3h";
BA_ "GenSigSendType" SG_ 1010 EC_ECUCfg3_Stat 5;
BA_ "GenSigCycleTime" SG_ 1010 EC_ECUCfg3_Stat 2000;
BA_ "FlexKomSigStartValue" SG_ 1010 EC_ECUCfg3_Stat "03h";
BA_ "FlexKomSigStartPos" SG_ 1010 EC_ECUCfg3_Stat 1;
BA_ "FlexKomSigName" SG_ 1010 EC_ECUCfg3_Stat "EC_ECUCfg3_Stat";
BA_ "FlexKomSigLaenge" SG_ 1010 EC_ECUCfg3_Stat 2;
BA_ "FlexKomSID" SG_ 1010 EC_ECUCfg3_Stat 1060;
BA_ "FlexKomIsMotorola" SG_ 1010 EC_ECUCfg3_Stat 1;
BA_ "FlexKomComment" SG_ 1010 EC_ECUCfg3_Stat "ECU Configuration messages status 3";
BA_ "GenSigTimeout_IC" SG_ 1011 EC_Cluster1A 21000;
BA_ "GenSigSNA" SG_ 1011 EC_Cluster1A "0h";
BA_ "GenSigSendType" SG_ 1011 EC_Cluster1A 5;
BA_ "GenSigCycleTime" SG_ 1011 EC_Cluster1A 2000;
BA_ "FlexKomSigStartValue" SG_ 1011 EC_Cluster1A "00000000h";
BA_ "FlexKomSigStartPos" SG_ 1011 EC_Cluster1A 7;
BA_ "FlexKomSigName" SG_ 1011 EC_Cluster1A "EC_Cluster1";
BA_ "FlexKomSigLaenge" SG_ 1011 EC_Cluster1A 32;
BA_ "FlexKomSID" SG_ 1011 EC_Cluster1A 896;
BA_ "FlexKomIsMotorola" SG_ 1011 EC_Cluster1A 1;
BA_ "FlexKomComment" SG_ 1011 EC_Cluster1A "Instrument cluster ecu configuration 1";
BA_ "GenSigTimeout_IC" SG_ 1011 EC_Cluster1B 21000;
BA_ "GenSigSNA" SG_ 1011 EC_Cluster1B "0h";
BA_ "GenSigSendType" SG_ 1011 EC_Cluster1B 5;
BA_ "GenSigCycleTime" SG_ 1011 EC_Cluster1B 2000;
BA_ "FlexKomSigStartValue" SG_ 1011 EC_Cluster1B "00000000h";
BA_ "FlexKomSigStartPos" SG_ 1011 EC_Cluster1B 7;
BA_ "FlexKomSigName" SG_ 1011 EC_Cluster1B "EC_Cluster1";
BA_ "FlexKomSigLaenge" SG_ 1011 EC_Cluster1B 32;
BA_ "FlexKomSID" SG_ 1011 EC_Cluster1B 896;
BA_ "FlexKomIsMotorola" SG_ 1011 EC_Cluster1B 1;
BA_ "FlexKomComment" SG_ 1011 EC_Cluster1B "Instrument cluster ecu configuration 1";
BA_ "GenSigTimeout_IC" SG_ 1011 EC_Cluster2 21000;
BA_ "GenSigSNA" SG_ 1011 EC_Cluster2 "0h";
BA_ "GenSigSendType" SG_ 1011 EC_Cluster2 5;
BA_ "GenSigCycleTime" SG_ 1011 EC_Cluster2 2000;
BA_ "FlexKomSigStartValue" SG_ 1011 EC_Cluster2 "00000000h";
BA_ "FlexKomSigStartPos" SG_ 1011 EC_Cluster2 39;
BA_ "FlexKomSigName" SG_ 1011 EC_Cluster2 "EC_Cluster2";
BA_ "FlexKomSigLaenge" SG_ 1011 EC_Cluster2 32;
BA_ "FlexKomSID" SG_ 1011 EC_Cluster2 903;
BA_ "FlexKomIsMotorola" SG_ 1011 EC_Cluster2 1;
BA_ "FlexKomComment" SG_ 1011 EC_Cluster2 "Instrument cluster ecu configuration 2";
BA_ "GenSigTimeout_IC" SG_ 1011 EC_ECUCfg4_Stat 21000;
BA_ "GenSigStartValue" SG_ 1011 EC_ECUCfg4_Stat 3;
BA_ "GenSigSNA" SG_ 1011 EC_ECUCfg4_Stat "3h";
BA_ "GenSigSendType" SG_ 1011 EC_ECUCfg4_Stat 5;
BA_ "GenSigCycleTime" SG_ 1011 EC_ECUCfg4_Stat 2000;
BA_ "FlexKomSigStartValue" SG_ 1011 EC_ECUCfg4_Stat "03h";
BA_ "FlexKomSigStartPos" SG_ 1011 EC_ECUCfg4_Stat 1;
BA_ "FlexKomSigName" SG_ 1011 EC_ECUCfg4_Stat "EC_ECUCfg4_Stat";
BA_ "FlexKomSigLaenge" SG_ 1011 EC_ECUCfg4_Stat 2;
BA_ "FlexKomSID" SG_ 1011 EC_ECUCfg4_Stat 1061;
BA_ "FlexKomIsMotorola" SG_ 1011 EC_ECUCfg4_Stat 1;
BA_ "FlexKomComment" SG_ 1011 EC_ECUCfg4_Stat "ECU Configuration messages status 4";
BA_ "GenSigSNA" SG_ 1012 EC_Doors "0h";
BA_ "GenSigSendType" SG_ 1012 EC_Doors 5;
BA_ "GenSigCycleTime" SG_ 1012 EC_Doors 2000;
BA_ "FlexKomSigStartValue" SG_ 1012 EC_Doors "000000h";
BA_ "FlexKomSigStartPos" SG_ 1012 EC_Doors 31;
BA_ "FlexKomSigName" SG_ 1012 EC_Doors "EC_Doors";
BA_ "FlexKomSigLaenge" SG_ 1012 EC_Doors 24;
BA_ "FlexKomSID" SG_ 1012 EC_Doors 893;
BA_ "FlexKomIsMotorola" SG_ 1012 EC_Doors 1;
BA_ "FlexKomComment" SG_ 1012 EC_Doors "Doors ecu configuration";
BA_ "GenSigStartValue" SG_ 1012 EC_ECUCfg5_Stat 3;
BA_ "GenSigSNA" SG_ 1012 EC_ECUCfg5_Stat "3h";
BA_ "GenSigSendType" SG_ 1012 EC_ECUCfg5_Stat 5;
BA_ "GenSigCycleTime" SG_ 1012 EC_ECUCfg5_Stat 2000;
BA_ "FlexKomSigStartValue" SG_ 1012 EC_ECUCfg5_Stat "03h";
BA_ "FlexKomSigStartPos" SG_ 1012 EC_ECUCfg5_Stat 1;
BA_ "FlexKomSigName" SG_ 1012 EC_ECUCfg5_Stat "EC_ECUCfg5_Stat";
BA_ "FlexKomSigLaenge" SG_ 1012 EC_ECUCfg5_Stat 2;
BA_ "FlexKomSID" SG_ 1012 EC_ECUCfg5_Stat 1062;
BA_ "FlexKomIsMotorola" SG_ 1012 EC_ECUCfg5_Stat 1;
BA_ "FlexKomComment" SG_ 1012 EC_ECUCfg5_Stat "ECU Configuration messages status 5";
BA_ "GenSigSNA" SG_ 1012 EC_Memory "0h";
BA_ "GenSigSendType" SG_ 1012 EC_Memory 5;
BA_ "GenSigCycleTime" SG_ 1012 EC_Memory 2000;
BA_ "FlexKomSigStartValue" SG_ 1012 EC_Memory "0000h";
BA_ "FlexKomSigStartPos" SG_ 1012 EC_Memory 55;
BA_ "FlexKomSigName" SG_ 1012 EC_Memory "EC_Memory";
BA_ "FlexKomSigLaenge" SG_ 1012 EC_Memory 16;
BA_ "FlexKomSID" SG_ 1012 EC_Memory 894;
BA_ "FlexKomIsMotorola" SG_ 1012 EC_Memory 1;
BA_ "FlexKomComment" SG_ 1012 EC_Memory "Memory ecu configuration";
BA_ "GenSigSNA" SG_ 1012 EC_WirelessA "0h";
BA_ "GenSigSendType" SG_ 1012 EC_WirelessA 5;
BA_ "GenSigCycleTime" SG_ 1012 EC_WirelessA 2000;
BA_ "FlexKomSigStartValue" SG_ 1012 EC_WirelessA "000000h";
BA_ "FlexKomSigStartPos" SG_ 1012 EC_WirelessA 7;
BA_ "FlexKomSigName" SG_ 1012 EC_WirelessA "EC_Wireless";
BA_ "FlexKomSigLaenge" SG_ 1012 EC_WirelessA 24;
BA_ "FlexKomSID" SG_ 1012 EC_WirelessA 895;
BA_ "FlexKomIsMotorola" SG_ 1012 EC_WirelessA 1;
BA_ "FlexKomComment" SG_ 1012 EC_WirelessA "Wireless ecu configuration";
BA_ "GenSigSNA" SG_ 1012 EC_WirelessB "0h";
BA_ "GenSigSendType" SG_ 1012 EC_WirelessB 5;
BA_ "GenSigCycleTime" SG_ 1012 EC_WirelessB 2000;
BA_ "FlexKomSigStartValue" SG_ 1012 EC_WirelessB "000000h";
BA_ "FlexKomSigStartPos" SG_ 1012 EC_WirelessB 7;
BA_ "FlexKomSigName" SG_ 1012 EC_WirelessB "EC_Wireless";
BA_ "FlexKomSigLaenge" SG_ 1012 EC_WirelessB 24;
BA_ "FlexKomSID" SG_ 1012 EC_WirelessB 895;
BA_ "FlexKomIsMotorola" SG_ 1012 EC_WirelessB 1;
BA_ "FlexKomComment" SG_ 1012 EC_WirelessB "Wireless ecu configuration";
BA_ "GenSigSNA" SG_ 1013 EC_BrakesA "0h";
BA_ "GenSigSendType" SG_ 1013 EC_BrakesA 5;
BA_ "GenSigCycleTime" SG_ 1013 EC_BrakesA 2000;
BA_ "FlexKomSigStartValue" SG_ 1013 EC_BrakesA "0000h";
BA_ "FlexKomSigStartPos" SG_ 1013 EC_BrakesA 7;
BA_ "FlexKomSigName" SG_ 1013 EC_BrakesA "EC_Brakes";
BA_ "FlexKomSigLaenge" SG_ 1013 EC_BrakesA 16;
BA_ "FlexKomSID" SG_ 1013 EC_BrakesA 889;
BA_ "FlexKomIsMotorola" SG_ 1013 EC_BrakesA 1;
BA_ "FlexKomComment" SG_ 1013 EC_BrakesA "Brake system ecu configuration";
BA_ "GenSigSNA" SG_ 1013 EC_BrakesB "0h";
BA_ "GenSigSendType" SG_ 1013 EC_BrakesB 5;
BA_ "GenSigCycleTime" SG_ 1013 EC_BrakesB 2000;
BA_ "FlexKomSigStartValue" SG_ 1013 EC_BrakesB "0000h";
BA_ "FlexKomSigStartPos" SG_ 1013 EC_BrakesB 7;
BA_ "FlexKomSigName" SG_ 1013 EC_BrakesB "EC_Brakes";
BA_ "FlexKomSigLaenge" SG_ 1013 EC_BrakesB 16;
BA_ "FlexKomSID" SG_ 1013 EC_BrakesB 889;
BA_ "FlexKomIsMotorola" SG_ 1013 EC_BrakesB 1;
BA_ "FlexKomComment" SG_ 1013 EC_BrakesB "Brake system ecu configuration";
BA_ "GenSigTimeout_ORC" SG_ 1013 EC_ECUCfg6_Stat 7000;
BA_ "GenSigStartValue" SG_ 1013 EC_ECUCfg6_Stat 3;
BA_ "GenSigSNA" SG_ 1013 EC_ECUCfg6_Stat "3h";
BA_ "GenSigSendType" SG_ 1013 EC_ECUCfg6_Stat 5;
BA_ "GenSigCycleTime" SG_ 1013 EC_ECUCfg6_Stat 2000;
BA_ "FlexKomSigStartValue" SG_ 1013 EC_ECUCfg6_Stat "03h";
BA_ "FlexKomSigStartPos" SG_ 1013 EC_ECUCfg6_Stat 1;
BA_ "FlexKomSigName" SG_ 1013 EC_ECUCfg6_Stat "EC_ECUCfg6_Stat";
BA_ "FlexKomSigLaenge" SG_ 1013 EC_ECUCfg6_Stat 2;
BA_ "FlexKomSID" SG_ 1013 EC_ECUCfg6_Stat 1063;
BA_ "FlexKomIsMotorola" SG_ 1013 EC_ECUCfg6_Stat 1;
BA_ "FlexKomComment" SG_ 1013 EC_ECUCfg6_Stat "ECU Configuration messages status 6";
BA_ "GenSigSNA" SG_ 1013 EC_Powertrain "0h";
BA_ "GenSigSendType" SG_ 1013 EC_Powertrain 5;
BA_ "GenSigCycleTime" SG_ 1013 EC_Powertrain 2000;
BA_ "FlexKomSigStartValue" SG_ 1013 EC_Powertrain "0000h";
BA_ "FlexKomSigStartPos" SG_ 1013 EC_Powertrain 39;
BA_ "FlexKomSigName" SG_ 1013 EC_Powertrain "EC_Powertrain";
BA_ "FlexKomSigLaenge" SG_ 1013 EC_Powertrain 16;
BA_ "FlexKomSID" SG_ 1013 EC_Powertrain 890;
BA_ "FlexKomIsMotorola" SG_ 1013 EC_Powertrain 1;
BA_ "FlexKomComment" SG_ 1013 EC_Powertrain "Powertrain ecu configuration";
BA_ "GenSigTimeout_ORC" SG_ 1013 EC_Safety 7000;
BA_ "GenSigSNA" SG_ 1013 EC_Safety "0h";
BA_ "GenSigSendType" SG_ 1013 EC_Safety 5;
BA_ "GenSigCycleTime" SG_ 1013 EC_Safety 2000;
BA_ "FlexKomSigStartValue" SG_ 1013 EC_Safety "0000h";
BA_ "FlexKomSigStartPos" SG_ 1013 EC_Safety 55;
BA_ "FlexKomSigName" SG_ 1013 EC_Safety "EC_Safety";
BA_ "FlexKomSigLaenge" SG_ 1013 EC_Safety 16;
BA_ "FlexKomSID" SG_ 1013 EC_Safety 892;
BA_ "FlexKomIsMotorola" SG_ 1013 EC_Safety 1;
BA_ "FlexKomComment" SG_ 1013 EC_Safety "Safety ecu configuration";
BA_ "GenSigTimeout_ORC" SG_ 1013 EC_Steering 7000;
BA_ "GenSigSNA" SG_ 1013 EC_Steering "0h";
BA_ "GenSigSendType" SG_ 1013 EC_Steering 5;
BA_ "GenSigCycleTime" SG_ 1013 EC_Steering 2000;
BA_ "FlexKomSigStartValue" SG_ 1013 EC_Steering "0000h";
BA_ "FlexKomSigStartPos" SG_ 1013 EC_Steering 23;
BA_ "FlexKomSigName" SG_ 1013 EC_Steering "EC_Steering";
BA_ "FlexKomSigLaenge" SG_ 1013 EC_Steering 16;
BA_ "FlexKomSID" SG_ 1013 EC_Steering 1982;
BA_ "FlexKomIsMotorola" SG_ 1013 EC_Steering 1;
BA_ "FlexKomComment" SG_ 1013 EC_Steering "Steering ecu configuration";
BA_ "GenSigSNA" SG_ 1014 EC_CBC5A "0h";
BA_ "GenSigCycleTime" SG_ 1014 EC_CBC5A 2000;
BA_ "FlexKomSigStartValue" SG_ 1014 EC_CBC5A "00000000h";
BA_ "FlexKomSigStartPos" SG_ 1014 EC_CBC5A 7;
BA_ "FlexKomSigName" SG_ 1014 EC_CBC5A "EC_CBC5";
BA_ "FlexKomSigLaenge" SG_ 1014 EC_CBC5A 32;
BA_ "FlexKomSID" SG_ 1014 EC_CBC5A 1105;
BA_ "FlexKomIsMotorola" SG_ 1014 EC_CBC5A 1;
BA_ "FlexKomComment" SG_ 1014 EC_CBC5A "CBC ecu configuration 5";
BA_ "GenSigSNA" SG_ 1014 EC_CBC5B "0h";
BA_ "GenSigCycleTime" SG_ 1014 EC_CBC5B 2000;
BA_ "FlexKomSigStartValue" SG_ 1014 EC_CBC5B "00000000h";
BA_ "FlexKomSigStartPos" SG_ 1014 EC_CBC5B 7;
BA_ "FlexKomSigName" SG_ 1014 EC_CBC5B "EC_CBC5";
BA_ "FlexKomSigLaenge" SG_ 1014 EC_CBC5B 32;
BA_ "FlexKomSID" SG_ 1014 EC_CBC5B 1105;
BA_ "FlexKomIsMotorola" SG_ 1014 EC_CBC5B 1;
BA_ "FlexKomComment" SG_ 1014 EC_CBC5B "CBC ecu configuration 5";
BA_ "GenSigSNA" SG_ 1014 EC_CBC6 "0h";
BA_ "GenSigCycleTime" SG_ 1014 EC_CBC6 2000;
BA_ "FlexKomSigStartValue" SG_ 1014 EC_CBC6 "00000000h";
BA_ "FlexKomSigStartPos" SG_ 1014 EC_CBC6 39;
BA_ "FlexKomSigName" SG_ 1014 EC_CBC6 "EC_CBC6";
BA_ "FlexKomSigLaenge" SG_ 1014 EC_CBC6 32;
BA_ "FlexKomSID" SG_ 1014 EC_CBC6 1103;
BA_ "FlexKomIsMotorola" SG_ 1014 EC_CBC6 1;
BA_ "FlexKomComment" SG_ 1014 EC_CBC6 "CBC ecu configuration 6";
BA_ "GenSigStartValue" SG_ 1014 EC_ECUCfg7_Stat 3;
BA_ "GenSigSNA" SG_ 1014 EC_ECUCfg7_Stat "3h";
BA_ "GenSigCycleTime" SG_ 1014 EC_ECUCfg7_Stat 2000;
BA_ "FlexKomSigStartValue" SG_ 1014 EC_ECUCfg7_Stat "03h";
BA_ "FlexKomSigStartPos" SG_ 1014 EC_ECUCfg7_Stat 1;
BA_ "FlexKomSigName" SG_ 1014 EC_ECUCfg7_Stat "EC_ECUCfg7_Stat";
BA_ "FlexKomSigLaenge" SG_ 1014 EC_ECUCfg7_Stat 2;
BA_ "FlexKomSID" SG_ 1014 EC_ECUCfg7_Stat 1102;
BA_ "FlexKomIsMotorola" SG_ 1014 EC_ECUCfg7_Stat 1;
BA_ "FlexKomComment" SG_ 1014 EC_ECUCfg7_Stat "ECU Configuration messages status 7";
VAL_ 131 BrkPdl_Stat 0 "UPSTOP" 1 "PSD" 2 "NDEF2" 3 "SNA" ;
VAL_ 131 Brk_Stat 0 "IDLE" 1 "BRAKING" 2 "NDEF2" 3 "SNA" ;
VAL_ 131 DTR_CC_Enabled 0 "SNA" ;
VAL_ 131 DTR_CC_Engaged 0 "SNA" ;
VAL_ 131 ESP_Sys_Stat 0 "ABSERR" 1 "NORM" 2 "HALF" 3 "ABGAS" ;
VAL_ 131 GrMax_Rq_ESC 0 "PASSIVE" 1 "G1" 2 "G2" 3 "G3" 4 "G4" 5 "G5" 6 "G6" 7 "G7" ;
VAL_ 131 GrMin_Rq_ESC 0 "PASSIVE" 1 "G1" 2 "G2" 3 "G3" 4 "G4" 5 "G5" 6 "G6" 7 "G7" ;
VAL_ 131 HillHolderActive 0 "Not_Active" 1 "Active" ;
VAL_ 131 REF_VEH_SPEED 1023 "SNA" ;
VAL_ 131 RollTestMd_Actv 0 "OFF" 1 "ON" 2 "NDEF2" 3 "SNA" ;
VAL_ 131 SPCR_AS_Off_Rq 0 "IDLE" 1 "AS_TMP_OFF" 2 "AS_CNTS_OFF" 3 "SPCR_NA" ;
VAL_ 131 SelSpdSts 0 "OFF" 1 "SELECT" 2 "INHIBIT" 3 "SNA" ;
VAL_ 131 ShftChrDsp_Rq_ESC 0 "SKL0" 1 "SKL1" 2 "SKL2" 3 "SKL3" 4 "SKL4" 5 "SKL5" 6 "SKL6" 7 "SKL7" 8 "SKL8" 9 "SKL9" 10 "SKL10" 11 "SKL11" 12 "SKL12" 15 "SNA" ;
VAL_ 120 BSMHybridModeReq 0 "No_Request" 1 "Electric_Mode" 2 "Engine_On_Mode" 3 "SNA" ;
VAL_ 120 BrakeBoostPressure 2047 "SNA" ;
VAL_ 120 BrakeBoostStat 0 "INIT_Bst" 1 "Normal_Bst" 2 "Limited_Bst" 3 "Shutdown_Bst" 4 "MOCO" 5 "Half_Sys_Bst" 6 "No_Bst" 15 "SNA" ;
VAL_ 120 BrakePdlPosn 255 "SNA" ;
VAL_ 120 BrakePedalPressure 2047 "SNA" ;
VAL_ 113 BrkBstrVac 255 "SNA" ;
VAL_ 113 DAS_RqActv 0 "IDLE" 1 "ACC" 2 "CMS" 3 "ABA" 4 "LSCM" 5 "CMS_XTD" 6 "PEB" 7 "SNA" ;
VAL_ 113 EngTrq_Rq_As 8191 "SNA" ;
VAL_ 113 EngTrq_Rq_ESC 8191 "SNA" ;
VAL_ 135 BrkPrss_TMC 2047 "SNA" ;
VAL_ 135 HSA_BrkPrss 63 "SNA" ;
VAL_ 137 VehAccel_X 255 "SNA" ;
VAL_ 137 VehAccel_X_Offset 255 "SNA" ;
VAL_ 137 VehAccel_Y 255 "SNA" ;
VAL_ 137 VehAccel_Y_Offset 255 "SNA" ;
VAL_ 137 VehYawRate_Offset 255 "SNA" ;
VAL_ 137 VehYawRate_Raw 65535 "SNA" ;
VAL_ 127 CENT_DIFF_ESP_RQ 0 "FREE" 1 "HOLD" 2 "OPEN" 3 "SNA" ;
VAL_ 127 CENT_DIFF_TRQ_RQ 255 "SNA" ;
VAL_ 127 WhlPlsCnt_FL 255 "SNA" ;
VAL_ 127 WhlPlsCnt_FR 255 "SNA" ;
VAL_ 127 WhlPlsCnt_RL 255 "SNA" ;
VAL_ 127 WhlPlsCnt_RR 255 "SNA" ;
VAL_ 139 WhlDir_FL_Stat 0 "VOID" 1 "FORWARD" 2 "BACKWARD" 3 "SNA" ;
VAL_ 139 WhlDir_FR_Stat 0 "VOID" 1 "FORWARD" 2 "BACKWARD" 3 "SNA" ;
VAL_ 139 WhlDir_RL_Stat 0 "VOID" 1 "FORWARD" 2 "BACKWARD" 3 "SNA" ;
VAL_ 139 WhlDir_RR_Stat 0 "VOID" 1 "FORWARD" 2 "BACKWARD" 3 "SNA" ;
VAL_ 139 WhlRPM_FL 16383 "SNA" ;
VAL_ 139 WhlRPM_FR 16383 "SNA" ;
VAL_ 139 WhlRPM_RL 16383 "SNA" ;
VAL_ 139 WhlRPM_RR 16383 "SNA" ;
VAL_ 121 BrkTrq 4095 "SNA" ;
VAL_ 121 BrkTrq_D 4095 "SNA" ;
VAL_ 121 VEH_SPEED 65535 "SNA" ;
VAL_ 117 WhlTrq_Rq_As_2 65535 "SNA" ;
VAL_ 221 ABS_IndLmp_On_Rq 0 "OFF" 1 "CONT" 2 "BLINK" 3 "SNA" ;
VAL_ 221 BrkIndLmp_On_Rq_ESC 0 "OFF" 1 "CONT" 2 "BLINK" 3 "SNA" ;
VAL_ 221 ESC_CtrlLmp_Info 0 "OFF" 1 "CONT" 2 "BLINK" 3 "SNA" ;
VAL_ 221 ESP_Off_IndLmp_On_Rq 0 "SNA" ;
VAL_ 221 HILL_DES_STAT 0 "HDC_UNAVL" 1 "HDC_ACT" 2 "HDC_AVL" 3 "HDC_THRML_DEACT" ;
VAL_ 221 LT_DIST 65535 "SNA" ;
VAL_ 221 RT_DIST 65535 "SNA" ;
VAL_ 221 SelSpdLmp 0 "OFF" 1 "CONT" 2 "BLINK" 3 "SNA" ;
VAL_ 840 FailSafeError 65535 "SNA" ;
VAL_ 1016 EC_BU_ECUCfg1_Stat 0 "NA" 1 "PROGAMMED" 2 "NA1" 3 "SNA" ;
VAL_ 989 EC_BU_ECUCfg10_Stat 0 "NA" 1 "PROGAMMED" 2 "NA1" 3 "SNA" ;
VAL_ 988 EC_BU_ECUCfg11_Stat 0 "NA" 1 "PROGAMMED" 2 "REQUEST_DATA" 3 "SNA" ;
VAL_ 987 EC_BU_ECUCfg12_Stat 0 "NA" 1 "PROGAMMED" 2 "NA1" 3 "SNA" ;
VAL_ 986 EC_BU_ECUCfg13_Stat 0 "NA" 1 "PROGAMMED" 2 "NA1" 3 "SNA" ;
VAL_ 985 EC_BU_ECUCfg14_Stat 0 "NA" 1 "PROGAMMED" 2 "NA1" 3 "SNA" ;
VAL_ 707 EC_BU_ECUCfg15_Stat 0 "NA" 1 "PROGAMMED" 2 "NA1" 3 "SNA" ;
VAL_ 714 EC_BU_ECUCfg16_Stat 0 "NA" 1 "PROGAMMED" 2 "NA1" 3 "SNA" ;
VAL_ 715 EC_BU_ECUCfg17_Stat 0 "NA" 1 "PROGAMMED" 2 "REQUEST_DATA" 3 "SNA" ;
VAL_ 716 EC_BU_ECUCfg18_Stat 0 "NA" 1 "PROGAMMED" 2 "REQUEST_DATA" 3 "SNA" ;
VAL_ 1017 EC_BU_ECUCfg2_Stat 0 "NA" 1 "PROGAMMED" 2 "NA1" 3 "SNA" ;
VAL_ 1018 EC_BU_ECUCfg3_Stat 0 "NA" 1 "PROGAMMED" 2 "NA1" 3 "SNA" ;
VAL_ 1019 EC_BU_ECUCfg4_Stat 0 "NA" 1 "PROGAMMED" 2 "NA1" 3 "SNA" ;
VAL_ 1020 EC_BU_ECUCfg5_Stat 0 "NA" 1 "PROGAMMED" 2 "NA1" 3 "SNA" ;
VAL_ 1021 EC_BU_ECUCfg6_Stat 0 "NA" 1 "PROGAMMED" 2 "NA1" 3 "SNA" ;
VAL_ 1022 EC_BU_ECUCfg7_Stat 0 "NA" 1 "PROGAMMED" 2 "NA1" 3 "SNA" ;
VAL_ 1023 EC_BU_ECUCfg8_Stat 0 "NA" 1 "PROGAMMED" 2 "NA1" 3 "SNA" ;
VAL_ 991 EC_BU_ECUCfg9_Stat 0 "NA" 1 "PROGAMMED" 2 "NA1" 3 "SNA" ;
VAL_ 1008 EC_ECUCfg1_Stat 0 "NA" 1 "PROGAMMED" 2 "REQUEST_DATA" 3 "SNA" ;
VAL_ 983 EC_ECUCfg10_Stat 0 "NA" 1 "PROGAMMED" 2 "REQUEST_DATA" 3 "SNA" ;
VAL_ 982 EC_ECUCfg11_Stat 0 "NA" 1 "PROGAMMED" 2 "REQUEST_DATA" 3 "SNA" ;
VAL_ 981 EC_ECUCfg12_Stat 0 "NA" 1 "PROGAMMED" 2 "REQUEST_DATA" 3 "SNA" ;
VAL_ 980 EC_ECUCfg13_Stat 0 "NA" 1 "PROGAMMED" 2 "REQUEST_DATA" 3 "SNA" ;
VAL_ 979 EC_ECUCfg14_Stat 0 "NA" 1 "PROGAMMED" 2 "REQUEST_DATA" 3 "SNA" ;
VAL_ 706 EC_ECUCfg15_Stat 0 "NA" 1 "PROGAMMED" 2 "REQUEST_DATA" 3 "SNA" ;
VAL_ 709 EC_ECUCfg16_Stat 0 "NA" 1 "PROGAMMED" 2 "REQUEST_DATA" 3 "SNA" ;
VAL_ 710 EC_ECUCfg17_Stat 0 "NA" 1 "PROGAMMED" 2 "REQUEST_DATA" 3 "SNA" ;
VAL_ 711 EC_ECUCfg18_Stat 0 "NA" 1 "PROGAMMED" 2 "REQUEST_DATA" 3 "SNA" ;
VAL_ 1009 EC_ECUCfg2_Stat 0 "NA" 1 "PROGAMMED" 2 "REQUEST_DATA" 3 "SNA" ;
VAL_ 1010 EC_ECUCfg3_Stat 0 "NA" 1 "PROGAMMED" 2 "REQUEST_DATA" 3 "SNA" ;
VAL_ 1011 EC_ECUCfg4_Stat 0 "NA" 1 "PROGAMMED" 2 "REQUEST_DATA" 3 "SNA" ;
VAL_ 1012 EC_ECUCfg5_Stat 0 "NA" 1 "PROGAMMED" 2 "REQUEST_DATA" 3 "SNA" ;
VAL_ 1013 EC_ECUCfg6_Stat 0 "NA" 1 "PROGAMMED" 2 "REQUEST_DATA" 3 "SNA" ;
VAL_ 1014 EC_ECUCfg7_Stat 0 "NA" 1 "PROGAMMED" 2 "REQUEST_DATA" 3 "SNA" ;
